VERSION ""

NS_ :

BS_:

BU_: AAF AAF_Tester ABS ACU ADRV AEMC AFLS AHLS APRK AVM BCM CAMERA CGW CLU CUBIS DATC DI_BOX Dummy ECS EMS EPB ESC EVP FATC FPCM FRONT_RADAR HUD IAP IBOX LCA LDWS_LKAS LPI LVR MDPS MTS ODS OPI PGS PSB REA SAS SCC SMK SNV SPAS TCU TMU TPMS _4WD

BS_:

BU_: XXX CAMERA FRONT_RADAR ADRV APRK

BO_ 353 MSG_161: 32 CCNC
 SG_ CHECKSUM : 0|16@1+ (1,0) [0|65535] "" XXX
 SG_ COUNTER : 16|8@1+ (1,0) [0|255] "" XXX
 SG_ FCA_ICON : 24|3@1+ (1,0) [0|7] "" XXX
 SG_ FCA_ALT_ICON : 27|3@1+ (1,0) [0|7] "" XXX
 SG_ LKA_ICON : 30|3@1+ (1,0) [0|3] "" XXX
 SG_ HBA_ICON : 33|3@1+ (1,0) [0|7] "" XXX
 SG_ ZEROS_1 : 36|4@1+ (1,0) [0|15] "" XXX
 SG_ ZEROS_2 : 40|2@1+ (1,0) [0|3] "" XXX
 SG_ FCA_IMAGE : 42|3@1+ (1,0) [0|7] "" XXX
 SG_ ZEROS_3 : 45|3@1+ (1,0) [0|7] "" XXX
 SG_ ZEROS_4 : 48|3@1+ (1,0) [0|7] "" XXX
 SG_ BCA_LEFT : 51|3@1+ (1,0) [0|7] "" XXX
 SG_ BCA_RIGHT : 54|3@1+ (1,0) [0|7] "" XXX
 SG_ LCA_LEFT_ARROW : 57|3@1+ (1,0) [0|7] "" XXX
 SG_ LCA_RIGHT_ARROW : 60|3@1+ (1,0) [0|7] "" XXX
 SG_ ZEROS_5 : 63|1@0+ (1,0) [0|1] "" XXX
 SG_ CENTERLINE : 64|2@1+ (1,0) [0|3] "" XXX
 SG_ TARGET : 66|3@1+ (1,0) [0|7] "" XXX
 SG_ TARGET_POSITION : 69|11@1+ (1,0) [0|7] "" XXX
 SG_ LANELINE_LEFT : 80|4@1+ (1,0) [0|15] "" XXX
 SG_ LANELINE_LEFT_POSITION : 84|6@1+ (1,0) [0|15] "" XXX
 SG_ LANELINE_RIGHT : 90|4@1+ (1,0) [0|15] "" XXX
 SG_ LANELINE_RIGHT_POSITION : 94|6@1+ (1,0) [0|3] "" XXX
 SG_ LANELINE_CURVATURE : 100|5@1- (1,15) [0|31] "" XXX
 SG_ LANE_HIGHLIGHT : 105|4@1+ (1,0) [0|15] "" XXX
 SG_ LANE_HIGHLIGHT_DISTANCE : 109|11@1+ (1,0) [0|7] "" XXX
 SG_ LANE_LEFT : 120|3@1+ (1,0) [0|7] "" XXX
 SG_ LANE_RIGHT : 123|3@1+ (1,0) [0|7] "" XXX
 SG_ LANE_ZOOM : 126|2@1+ (1,0) [0|3] "" XXX
 SG_ ALERTS_1 : 128|6@1+ (1,0) [0|63] "" XXX
 SG_ ALERTS_2 : 134|5@1+ (1,0) [0|3] "" XXX
 SG_ ALERTS_3 : 139|4@1+ (1,0) [0|15] "" XXX
 SG_ ALERTS_4 : 143|9@1+ (1,0) [0|511] "" XXX
 SG_ ALERTS_5 : 152|5@1+ (1,0) [0|7] "" XXX
 SG_ MUTE : 157|3@1+ (1,0) [0|7] "" XXX
 SG_ SOUNDS_1 : 160|4@1+ (1,0) [0|3] "" XXX
 SG_ SOUNDS_2 : 164|4@1+ (1,0) [0|3] "" XXX
 SG_ SOUNDS_3 : 168|4@1+ (1,0) [0|15] "" XXX
 SG_ SOUNDS_4 : 172|3@1+ (1,0) [0|7] "" XXX
 SG_ ZEROS_6 : 175|1@0+ (1,0) [0|1] "" XXX
 SG_ ZEROS_7 : 176|5@1+ (1,0) [0|31] "" XXX
 SG_ SETSPEED_HUD : 181|3@1+ (1,0) [0|3] "" XXX
 SG_ DISTANCE_LEAD : 184|5@1+ (1,0) [0|31] "" XXX
 SG_ DISTANCE_CAR : 189|3@1+ (1,0) [0|7] "" XXX
 SG_ DISTANCE_SPACING : 192|4@1+ (1,0) [0|15] "" XXX
 SG_ DISTANCE : 196|4@1+ (1,0) [0|7] "" XXX
 SG_ SETSPEED_SPEED : 200|8@1+ (1,0) [0|255] "" XXX
 SG_ SETSPEED : 208|4@1+ (1,0) [0|3] "" XXX
 SG_ HDA_ICON : 212|4@1+ (1,0) [0|3] "" XXX
 SG_ SLA_ICON : 216|4@1+ (1,0) [0|15] "" XXX
 SG_ NAV_ICON : 220|4@1+ (1,0) [0|3] "" XXX
 SG_ LFA_ICON : 224|4@1+ (1,0) [0|3] "" XXX
 SG_ LCA_LEFT_ICON : 228|4@1+ (1,0) [0|15] "" XXX
 SG_ LCA_RIGHT_ICON : 232|4@1+ (1,0) [0|15] "" XXX
 SG_ BACKGROUND : 236|4@1+ (1,0) [0|15] "" XXX
 SG_ DAW_ICON : 240|3@1+ (1,0) [0|7] "" XXX
 SG_ CAR_CIRCLE : 243|3@1+ (1,0) [0|7] "" XXX
 SG_ ZEROS_8 : 246|2@1+ (1,0) [0|3] "" XXX
 SG_ ZEROS_9 : 248|8@1+ (1,0) [0|255] "" XXX

BO_ 354 MSG_162: 32 CCNC
 SG_ CHECKSUM : 0|16@1+ (1,0) [0|65535] "" XXX
 SG_ COUNTER : 16|8@1+ (1,0) [0|255] "" XXX
 SG_ SPEEDLIMIT_STYLE : 24|4@1+ (1,0) [0|7] "" XXX
 SG_ SPEEDLIMIT_FLASH : 28|4@1+ (1,0) [0|15] "" XXX
 SG_ SPEEDLIMIT : 32|8@1+ (1,0) [0|255] "" XXX
 SG_ SIGNS : 40|8@1+ (1,0) [0|15] "" XXX
 SG_ SPEEDLIMIT_WEATHER : 48|4@1+ (1,0) [0|15] "" XXX
 SG_ VIBRATE : 52|3@1+ (1,0) [0|7] "" XXX
 SG_ ZEROS_1 : 55|1@0+ (1,0) [0|1] "" XXX
 SG_ ZEROS_2 : 56|8@1+ (1,0) [0|255] "" XXX
 SG_ LEAD : 64|5@1+ (1,0) [0|31] "" XXX
 SG_ LEAD_DISTANCE : 69|11@1+ (1,0) [0|2047] "" XXX
 SG_ LEAD_LATERAL : 80|7@1+ (1,0) [0|127] "" XXX
 SG_ ZEROS_3 : 87|1@0+ (1,0) [0|1] "" XXX
 SG_ LEAD_ALT : 88|5@1+ (1,0) [0|31] "" XXX
 SG_ LEAD_ALT_DISTANCE : 93|11@1+ (1,0) [0|2047] "" XXX
 SG_ LEAD_ALT_LATERAL : 104|7@1+ (1,0) [0|127] "" XXX
 SG_ ZEROS_4 : 111|1@0+ (1,0) [0|1] "" XXX
 SG_ LEAD_LEFT : 112|5@1+ (1,0) [0|31] "" XXX
 SG_ LEAD_LEFT_DISTANCE : 117|11@1+ (1,0) [0|2047] "" XXX
 SG_ LEAD_LEFT_LATERAL : 128|7@1+ (1,0) [0|127] "" XXX
 SG_ ZEROS_5 : 135|1@0+ (1,0) [0|1] "" XXX
 SG_ LEAD_RIGHT : 136|5@1+ (1,0) [0|31] "" XXX
 SG_ LEAD_RIGHT_DISTANCE : 141|11@1+ (1,0) [0|2047] "" XXX
 SG_ LEAD_RIGHT_LATERAL : 152|7@1+ (1,0) [0|127] "" XXX
 SG_ ZEROS_6 : 159|1@0+ (1,0) [0|1] "" XXX
 SG_ ZEROS_7 : 160|8@1+ (1,0) [0|255] "" XXX
 SG_ ZEROS_8 : 168|8@1+ (1,0) [0|255] "" XXX
 SG_ ZEROS_9 : 176|8@1+ (1,0) [0|255] "" XXX
 SG_ ZEROS_10 : 184|8@1+ (1,0) [0|255] "" XXX
 SG_ ZEROS_11 : 192|8@1+ (1,0) [0|255] "" XXX
 SG_ ZEROS_12 : 200|8@1+ (1,0) [0|255] "" XXX
 SG_ ZEROS_13 : 208|5@1+ (1,0) [0|31] "" XXX
 SG_ FAULT_FSS : 213|3@1+ (1,0) [0|7] "" XXX
 SG_ FAULT_FCA : 216|3@1+ (1,0) [0|7] "" XXX
 SG_ FAULT_LSS : 219|3@1+ (1,0) [0|7] "" XXX
 SG_ FAULT_SLA : 222|3@1+ (1,0) [0|7] "" XXX
 SG_ FAULT_DAW : 225|3@1+ (1,0) [0|7] "" XXX
 SG_ FAULT_HBA : 228|3@1+ (1,0) [0|7] "" XXX
 SG_ FAULT_SCC : 231|3@1+ (1,0) [0|7] "" XXX
 SG_ FAULT_LFA : 234|3@1+ (1,0) [0|7] "" XXX
 SG_ FAULT_HDA : 237|3@1+ (1,0) [0|7] "" XXX
 SG_ FAULT_LCA : 240|3@1+ (1,0) [0|7] "" XXX
 SG_ FAULT_HDP : 243|3@1+ (1,0) [0|7] "" XXX
 SG_ FAULT_DAS : 246|3@1+ (1,0) [0|7] "" XXX
 SG_ FAULT_ESS : 249|3@1+ (1,0) [0|7] "" XXX
 SG_ ZEROS_14 : 252|4@1+ (1,0) [0|15] "" XXX

BS_:

BU_: IAP ODS _4WD BCM HUD DATC MDPS AAF_Tester AEMC SMK _4WD EPB CUBIS MTS TMU EVP CGW TPMS LPI DI_BOX SPAS EMS LCA TCU IBOX FATC AFLS FPCM SCC AHLS AVM ABS SNV OPI PGS SAS AAF Dummy LDWS_LKAS LVR ESC PSB CLU ECS ACU REA

BO_ 1532 ODS13: 5 ODS
 SG_ CR_Ods_ID : 0|8@1+ (1.0,0.0) [0.0|255.0] ""  ACU
 SG_ CR_Ods_Chksum_H : 8|8@1+ (1.0,0.0) [0.0|255.0] ""  Dummy
 SG_ CR_Ods_Chksum_L : 16|8@1+ (1.0,0.0) [0.0|255.0] ""  Dummy
 SG_ CR_Ods_RomID_H : 24|8@1+ (1.0,0.0) [0.0|255.0] ""  Dummy
 SG_ CR_Ods_RomID_L : 32|8@1+ (1.0,0.0) [0.0|255.0] ""  Dummy

BO_ 1531 ODS12: 8 ODS
 SG_ CR_Ods_SerNum0 : 0|8@1+ (1.0,0.0) [0.0|255.0] ""  ACU
 SG_ CR_Ods_SerNum1 : 8|8@1+ (1.0,0.0) [0.0|255.0] ""  ACU
 SG_ CR_Ods_SerNum2 : 16|8@1+ (1.0,0.0) [0.0|255.0] ""  ACU
 SG_ CR_Ods_SerNum3 : 24|8@1+ (1.0,0.0) [0.0|255.0] ""  ACU
 SG_ CR_Ods_SerNum4 : 32|8@1+ (1.0,0.0) [0.0|255.0] ""  ACU
 SG_ CR_Ods_SerNum5 : 40|8@1+ (1.0,0.0) [0.0|255.0] ""  ACU
 SG_ CR_Ods_SerNum6 : 48|8@1+ (1.0,0.0) [0.0|255.0] ""  ACU
 SG_ CR_Ods_SerNum7 : 56|8@1+ (1.0,0.0) [0.0|255.0] ""  ACU

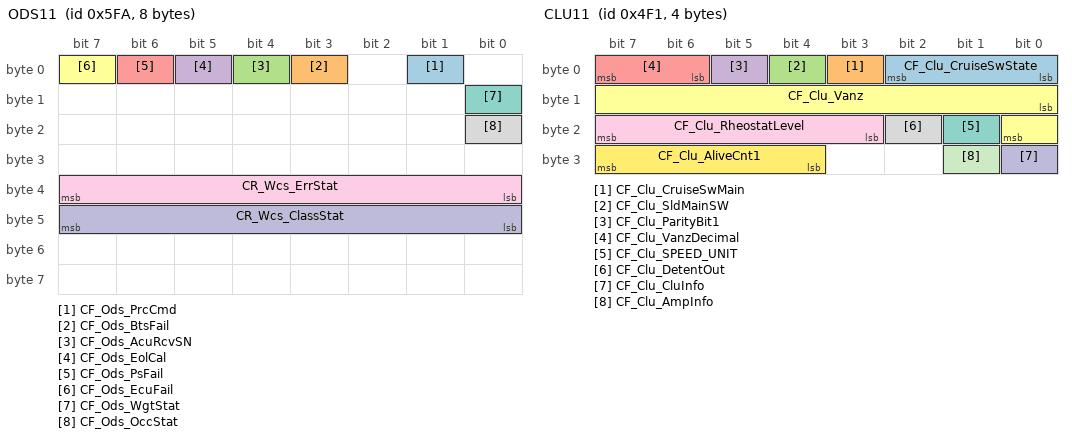
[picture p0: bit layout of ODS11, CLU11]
BO_ 1530 ODS11: 8 ODS
 SG_ CF_Ods_PrcCmd : 1|1@1+ (1.0,0.0) [0.0|1.0] ""  Dummy
 SG_ CF_Ods_BtsFail : 3|1@1+ (1.0,0.0) [0.0|1.0] ""  Dummy
 SG_ CF_Ods_AcuRcvSN : 4|1@1+ (1.0,0.0) [0.0|1.0] ""  ACU
 SG_ CF_Ods_EolCal : 5|1@1+ (1.0,0.0) [0.0|1.0] ""  ACU
 SG_ CF_Ods_PsFail : 6|1@1+ (1.0,0.0) [0.0|1.0] ""  ACU
 SG_ CF_Ods_EcuFail : 7|1@1+ (1.0,0.0) [0.0|1.0] ""  ACU
 SG_ CF_Ods_WgtStat : 8|1@1+ (1.0,0.0) [0.0|1.0] ""  ACU
 SG_ CF_Ods_OccStat : 16|1@1+ (1.0,0.0) [0.0|1.0] ""  ACU
 SG_ CR_Wcs_ErrStat : 32|8@1+ (1.0,0.0) [0.0|63.0] ""  ACU
 SG_ CR_Wcs_ClassStat : 40|8@1+ (1.0,0.0) [0.0|4.0] ""  ACU,BCM

BO_ 1017 ECS12: 4 ECS
 SG_ Height_FL : 0|8@1+ (1.0,-128.0) [-128.0|127.0] "mm"  AFLS
 SG_ Height_FR : 8|8@1+ (1.0,-128.0) [-128.0|127.0] "mm"  AFLS
 SG_ Height_RL : 16|8@1+ (1.0,-128.0) [-128.0|127.0] "mm"  AFLS
 SG_ Height_RR : 24|8@1+ (1.0,-128.0) [-128.0|127.0] "mm"  AFLS

BO_ 1268 SPAS12: 8 SPAS
 SG_ CF_Spas_HMI_Stat : 0|8@1+ (1.0,0.0) [0.0|255.0] ""  CLU
 SG_ CF_Spas_Disp : 8|2@1+ (1.0,0.0) [0.0|3.0] ""  CLU,EMS
 SG_ CF_Spas_FIL_Ind : 10|3@1+ (1.0,0.0) [0.0|7.0] ""  AVM,CLU
 SG_ CF_Spas_FIR_Ind : 13|3@1+ (1.0,0.0) [0.0|7.0] ""  AVM,CLU
 SG_ CF_Spas_FOL_Ind : 16|3@1+ (1.0,0.0) [0.0|7.0] ""  AVM,CLU
 SG_ CF_Spas_FOR_Ind : 19|3@1+ (1.0,0.0) [0.0|7.0] ""  AVM,CLU
 SG_ CF_Spas_VolDown : 22|2@1+ (1.0,0.0) [0.0|3.0] ""  CLU
 SG_ CF_Spas_RIL_Ind : 24|3@1+ (1.0,0.0) [0.0|7.0] ""  AVM,CLU
 SG_ CF_Spas_RIR_Ind : 27|3@1+ (1.0,0.0) [0.0|7.0] ""  AVM,CLU
 SG_ CF_Spas_FLS_Alarm : 30|2@1+ (1.0,0.0) [0.0|3.0] ""  CLU
 SG_ CF_Spas_ROL_Ind : 32|3@1+ (1.0,0.0) [0.0|7.0] ""  AVM,CLU
 SG_ CF_Spas_ROR_Ind : 35|3@1+ (1.0,0.0) [0.0|7.0] ""  AVM,CLU
 SG_ CF_Spas_FCS_Alarm : 38|2@1+ (1.0,0.0) [0.0|3.0] ""  CLU
 SG_ CF_Spas_FI_Ind : 40|3@1+ (1.0,0.0) [0.0|7.0] ""  AVM,CLU
 SG_ CF_Spas_RI_Ind : 43|3@1+ (1.0,0.0) [0.0|7.0] ""  AVM,CLU
 SG_ CF_Spas_FRS_Alarm : 46|2@1+ (1.0,0.0) [0.0|3.0] ""  CLU
 SG_ CF_Spas_FR_Alarm : 48|2@1+ (1.0,0.0) [0.0|3.0] ""  BCM,CLU
 SG_ CF_Spas_RR_Alarm : 50|2@1+ (1.0,0.0) [0.0|3.0] ""  BCM,CLU
 SG_ CF_Spas_BEEP_Alarm : 52|4@1+ (1.0,0.0) [0.0|15.0] ""  BCM,CLU
 SG_ CF_Spas_StatAlarm : 56|1@1+ (1.0,0.0) [0.0|1.0] ""  CLU
 SG_ CF_Spas_RLS_Alarm : 57|2@1+ (1.0,0.0) [0.0|3.0] ""  CLU
 SG_ CF_Spas_RCS_Alarm : 59|2@1+ (1.0,0.0) [0.0|3.0] ""  CLU
 SG_ CF_Spas_RRS_Alarm : 61|2@1+ (1.0,0.0) [0.0|3.0] ""  CLU

BO_ 1265 CLU11: 4 CLU
 SG_ CF_Clu_CruiseSwState : 0|3@1+ (1.0,0.0) [0.0|7.0] ""  EMS,LDWS_LKAS,SCC
 SG_ CF_Clu_CruiseSwMain : 3|1@1+ (1.0,0.0) [0.0|1.0] ""  EMS,LDWS_LKAS,SCC
 SG_ CF_Clu_SldMainSW : 4|1@1+ (1.0,0.0) [0.0|1.0] ""  EMS
 SG_ CF_Clu_ParityBit1 : 5|1@1+ (1.0,0.0) [0.0|1.0] "pulse count"  EMS
 SG_ CF_Clu_VanzDecimal : 6|2@1+ (0.125,0.0) [0.0|0.375] ""  EMS
 SG_ CF_Clu_Vanz : 8|9@1+ (0.5,0.0) [0.0|255.5] "km/h or MPH"  BCM,CUBIS,EMS,IBOX,LDWS_LKAS,MDPS,SCC
 SG_ CF_Clu_SPEED_UNIT : 17|1@1+ (1.0,0.0) [0.0|1.0] ""  BCM,CUBIS,EMS,IBOX,LDWS_LKAS,MDPS,SCC
 SG_ CF_Clu_DetentOut : 18|1@1+ (1.0,0.0) [0.0|1.0] ""  AVM,BCM,LCA,PGS,SPAS
 SG_ CF_Clu_RheostatLevel : 19|5@1+ (1.0,0.0) [0.0|31.0] ""  AVM,BCM,LCA,PGS,SPAS
 SG_ CF_Clu_CluInfo : 24|1@1+ (1.0,0.0) [0.0|1.0] ""  BCM
 SG_ CF_Clu_AmpInfo : 25|1@1+ (1.0,0.0) [0.0|1.0] ""  BCM
 SG_ CF_Clu_AliveCnt1 : 28|4@1+ (1.0,0.0) [0.0|15.0] ""  AHLS,EMS,EPB,LDWS_LKAS,MDPS,SCC

BO_ 1260 Sign_Detection: 8 XXX
 SG_ SpeedLim_Nav_Cam : 40|8@1+ (1,0) [0|255] "km/h / mph" XXX
 SG_ SpeedLim_Nav_Cam2 : 48|8@1+ (1,0) [0|255] "km/h / mph" XXX

BO_ 1492 TMU_GW_PE_01: 8 CLU
 SG_ TMU_IVRActivity : 0|2@1+ (1.0,0.0) [0.0|3.0] ""  DATC
 SG_ TMU_PhoneActivity : 2|2@1+ (1.0,0.0) [0.0|3.0] ""  DATC

BO_ 1491 HU_DATC_PE_00: 8 CLU
 SG_ HU_VRActivity : 0|2@1+ (1.0,0.0) [0.0|3.0] ""  DATC
 SG_ HU_PhoneActivity : 2|2@1+ (1.0,0.0) [0.0|3.0] ""  DATC
 SG_ BlowerNoiseControl : 4|2@1+ (1.0,0.0) [0.0|3.0] ""  DATC

BO_ 1490 HU_DATC_E_02: 8 CLU
 SG_ HU_DATC_RearOnOffSet : 6|2@1+ (1.0,0.0) [0.0|3.0] ""  DATC
 SG_ HU_DATC_ADSOnOffSet : 8|2@1+ (1.0,0.0) [0.0|3.0] ""  DATC

BO_ 1479 EMS21: 8 EMS
 SG_ SCR_LEVEL_WARN_LAMP : 0|1@1+ (1.0,0.0) [0.0|1.0] ""  CLU
 SG_ SCR_LEVEL_WARN : 1|3@1+ (1.0,0.0) [0.0|4.0] ""  CLU
 SG_ SCR_SYS_ERROR_WARN : 4|3@1+ (1.0,0.0) [0.0|7.0] ""  CLU
 SG_ SCR_SYSTEM_WARN_LAMP : 7|1@1+ (1.0,0.0) [0.0|1.0] ""  CLU
 SG_ SCR_INDUCEMENT_EXIT_COND : 8|2@1+ (1.0,0.0) [0.0|3.0] ""  CLU
 SG_ SCR_UREA_LEVEL : 16|8@1+ (0.5,0.0) [0.0|100.0] "%"  CLU
 SG_ SCR_NO_REMAINING_RESTARTS : 24|8@1+ (1.0,0.0) [0.0|255.0] ""  CLU
 SG_ SCR_REMAINING_DISTANCE : 32|16@1+ (1.0,0.0) [0.0|25000.0] "km"  CLU

BO_ 1472 GW_Warning_PE: 8 BCM
 SG_ Audio_VolumeDown : 38|2@1+ (1.0,0.0) [0.0|3.0] ""  CLU
 SG_ Pas_Spkr_Flh_Alarm : 48|2@1+ (1.0,0.0) [0.0|3.0] ""  CLU
 SG_ Pas_Spkr_Fcnt_Alarm : 50|2@1+ (1.0,0.0) [0.0|3.0] ""  CLU
 SG_ Pas_Spkr_Frh_Alarm : 52|2@1+ (1.0,0.0) [0.0|3.0] ""  CLU
 SG_ Pas_Spkr_Rlh_Alarm : 56|2@1+ (1.0,0.0) [0.0|3.0] ""  CLU,PGS
 SG_ Pas_Spkr_Rcnt_Alarm : 58|2@1+ (1.0,0.0) [0.0|3.0] ""  CLU
 SG_ Pas_Spkr_Rrh_Alarm : 60|2@1+ (1.0,0.0) [0.0|3.0] ""  CLU,PGS

BO_ 1984 CAL_SAS11: 2 ESC
 SG_ CCW : 0|4@1+ (1.0,0.0) [0.0|15.0] ""  SAS
 SG_ SAS_CID : 4|11@1+ (1.0,0.0) [0.0|2047.0] ""  SAS

BO_ 1456 CLU12: 4 CLU
 SG_ CF_Clu_Odometer : 0|24@1+ (0.1,0.0) [0.0|1677721.4] "km"  _4WD,AAF,BCM,CUBIS,EMS,EPB,IBOX,LDWS_LKAS,SCC,TPMS

BO_ 688 SAS11: 5 MDPS
 SG_ SAS_Angle : 0|16@1- (0.1,0.0) [-3276.8|3276.7] "Deg"  _4WD,ACU,AFLS,AVM,CLU,ECS,EMS,ESC,IBOX,LCA,LDWS_LKAS,PGS,PSB,SCC,SPAS,TCU,_4WD,ACU,AFLS,AVM,BCM,CLU,ECS,EMS,ESC,IBOX,LCA,LDWS_LKAS,PGS,PSB,SCC,SPAS,TCU
 SG_ SAS_Speed : 16|8@1+ (4.0,0.0) [0.0|1016.0] ""  AFLS,ECS,ESC,IBOX,LDWS_LKAS,SCC,SPAS,TCU,AFLS,ECS,ESC,IBOX,LDWS_LKAS,SCC,SPAS,TCU
 SG_ SAS_Stat : 24|8@1+ (1.0,0.0) [0.0|255.0] ""  ECS,ESC,IBOX,LDWS_LKAS,PSB,SCC,SPAS,TCU,ECS,ESC,IBOX,LDWS_LKAS,PSB,SCC,SPAS,TCU
 SG_ MsgCount : 32|4@1+ (1.0,0.0) [0.0|15.0] ""  ECS,ESC,IBOX,LDWS_LKAS,PSB,SCC,SPAS,ECS,ESC,IBOX,LDWS_LKAS,PSB,SCC,SPAS
 SG_ CheckSum : 36|4@1+ (1.0,0.0) [0.0|15.0] ""  ECS,EMS,ESC,IBOX,LDWS_LKAS,PSB,SCC,SPAS,ECS,EMS,ESC,IBOX,LDWS_LKAS,PSB,SCC,SPAS

BO_ 1441 ACU12: 8 ACU
 SG_ CR_Acu_SN : 0|64@1+ (1.0,0.0) [0.0|0.0] ""  ODS

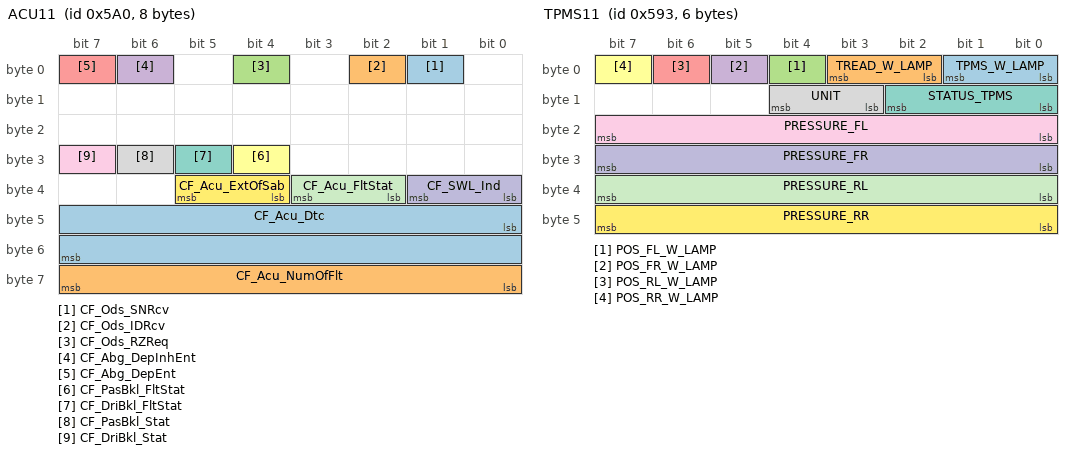
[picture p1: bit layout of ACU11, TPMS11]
BO_ 1440 ACU11: 8 ACU
 SG_ CF_Ods_SNRcv : 1|1@1+ (1.0,0.0) [0.0|1.0] ""  ODS
 SG_ CF_Ods_IDRcv : 2|1@1+ (1.0,0.0) [0.0|1.0] ""  ODS
 SG_ CF_Ods_RZReq : 4|1@1+ (1.0,0.0) [0.0|1.0] ""  ODS
 SG_ CF_Abg_DepInhEnt : 6|1@1+ (1.0,0.0) [0.0|1.0] ""  ODS
 SG_ CF_Abg_DepEnt : 7|1@1+ (1.0,0.0) [0.0|1.0] ""  ODS
 SG_ CF_PasBkl_FltStat : 28|1@1+ (1.0,0.0) [0.0|1.0] ""  ODS,PSB
 SG_ CF_DriBkl_FltStat : 29|1@1+ (1.0,0.0) [0.0|1.0] ""  ODS,PSB
 SG_ CF_PasBkl_Stat : 30|1@1+ (1.0,0.0) [0.0|1.0] ""  IBOX,ODS,PSB,TMU
 SG_ CF_DriBkl_Stat : 31|1@1+ (1.0,0.0) [0.0|1.0] ""  ODS,PSB
 SG_ CF_SWL_Ind : 32|2@1+ (1.0,0.0) [0.0|3.0] ""  CUBIS,IBOX
 SG_ CF_Acu_FltStat : 34|2@1+ (1.0,0.0) [0.0|3.0] ""  CUBIS,IBOX
 SG_ CF_Acu_ExtOfSab : 36|2@1+ (1.0,0.0) [0.0|3.0] ""  BCM,CLU,CUBIS,IBOX
 SG_ CF_Acu_Dtc : 40|16@1+ (1.0,0.0) [0.0|65535.0] ""  CUBIS,IBOX
 SG_ CF_Acu_NumOfFlt : 56|8@1+ (1.0,0.0) [0.0|255.0] ""  CUBIS,IBOX

BO_ 1437 AHLS11: 8 AHLS
 SG_ CF_Ahls_WarnLamp : 0|2@1+ (1.0,0.0) [0.0|3.0] ""  CLU
 SG_ CF_Ahls_WarnMsg : 2|2@1+ (1.0,0.0) [0.0|3.0] ""  CLU

BO_ 1434 PSB11: 2 PSB
 SG_ PSB_LH_FAIL : 0|2@1+ (1.0,0.0) [0.0|3.0] ""  CLU
 SG_ PSB_LH_TGL : 2|1@1+ (1.0,0.0) [0.0|1.0] ""  CLU
 SG_ PSB_LH_ACT : 3|4@1+ (1.0,0.0) [0.0|4.0] ""  Dummy
 SG_ PSB_RH_FAIL : 8|2@1+ (1.0,0.0) [0.0|3.0] ""  CLU
 SG_ PSB_RH_TGL : 10|1@1+ (1.0,0.0) [0.0|1.0] ""  CLU
 SG_ PSB_RH_ACT : 11|4@1+ (1.0,0.0) [0.0|4.0] ""  Dummy

BO_ 916 TCS13: 8 ESC
 SG_ aBasis : 0|11@1+ (0.01,-10.23) [-10.23|10.24] "m/s^2"  EMS,SCC
 SG_ BrakeLight : 11|1@1+ (1.0,0.0) [0.0|1.0] ""  CLU,EMS,SCC
 SG_ DCEnable : 12|1@1+ (1.0,0.0) [0.0|1.0] ""  EMS,SCC
 SG_ AliveCounterTCS : 13|3@1+ (1.0,0.0) [0.0|7.0] ""  EMS,SCC
 SG_ Pre_TCS_CTL : 16|1@1+ (1.0,0.0) [0.0|1.0] ""  Vector__XXX
 SG_ EBA_ACK : 17|1@1+ (1.0,0.0) [0.0|1.0] ""  Vector__XXX
 SG_ FCA_ACK : 18|1@1+ (1.0,0.0) [0.0|1.0] ""  Vector__XXX
 SG_ DF_BF_STAT : 19|2@1+ (1.0,0.0) [0.0|3.0] ""  BCW
 SG_ SCCReqLim : 22|2@1+ (1.0,0.0) [0.0|3.0] ""  SCC
 SG_ TQI_SCC : 24|8@1+ (0.390625,0.0) [0.0|199.609375] "%"  Vector__XXX
 SG_ ACCEL_REF_ACC : 32|11@1+ (0.01,-10.23) [-10.23|10.24] "m/s^2"  EMS,SCC
 SG_ ACCEnable : 43|2@1+ (1.0,0.0) [0.0|3.0] ""  EMS,SCC
 SG_ DriverOverride : 45|2@1+ (1.0,0.0) [0.0|3.0] ""  EMS,SCC
 SG_ StandStill : 47|1@1+ (1.0,0.0) [0.0|1.0] ""  EMS,SCC
 SG_ CheckSum_TCS3 : 48|4@1+ (1.0,0.0) [0.0|15.0] ""  EMS,SCC
 SG_ ACC_EQUIP : 52|1@1+ (1.0,0.0) [0.0|1.0] ""  EMS,SCC
 SG_ PBRAKE_ACT : 53|1@1+ (1.0,0.0) [0.0|1.0] ""  EMS,SCC
 SG_ ACC_REQ : 54|1@1+ (1.0,0.0) [0.0|1.0] ""  EMS
 SG_ DriverBraking : 55|1@1+ (1.0,0.0) [0.0|1.0] ""  EMS,SCC
 SG_ CF_VSM_Coded : 56|1@1+ (1.0,0.0) [0.0|1.0] ""  SCC
 SG_ CF_VSM_Avail : 57|2@1+ (1.0,0.0) [0.0|3.0] ""  CLU,SCC
 SG_ CF_VSM_Handshake : 59|1@1+ (1.0,0.0) [0.0|1.0] ""  SCC
 SG_ CF_DriBkeStat : 60|1@1+ (1.0,0.0) [0.0|1.0] ""  SCC
 SG_ CF_VSM_ConfSwi : 61|2@1+ (1.0,0.0) [0.0|3.0] ""  SCC
 SG_ AEB_EQUIP : 63|1@1+ (1.0,0.0) [0.0|1.0] ""  SCC

BO_ 1427 TPMS11: 6 BCM
 SG_ TPMS_W_LAMP : 0|2@1+ (1.0,0.0) [0.0|3.0] ""  CLU,CUBIS,HUD,IBOX,CLU,CUBIS,HUD,IBOX
 SG_ TREAD_W_LAMP : 2|2@1+ (1.0,0.0) [0.0|3.0] ""  CLU,CUBIS,HUD,IBOX,CLU,CUBIS,HUD,IBOX
 SG_ POS_FL_W_LAMP : 4|1@1+ (1.0,0.0) [0.0|1.0] ""  CLU,CUBIS,HUD,IBOX
 SG_ POS_FR_W_LAMP : 5|1@1+ (1.0,0.0) [0.0|1.0] ""  CLU,CUBIS,HUD,IBOX
 SG_ POS_RL_W_LAMP : 6|1@1+ (1.0,0.0) [0.0|1.0] ""  CLU,CUBIS,HUD,IBOX
 SG_ POS_RR_W_LAMP : 7|1@1+ (1.0,0.0) [0.0|1.0] ""  CLU,CUBIS,HUD,IBOX
 SG_ STATUS_TPMS : 8|3@1+ (1.0,0.0) [0.0|0.0] ""  CLU
 SG_ UNIT : 11|2@1+ (1.0,0.0) [0.0|3.0] ""  CLU
 SG_ PRESSURE_FL : 16|8@1+ (1.0,0.0) [0.0|255.0] ""  CLU
 SG_ PRESSURE_FR : 24|8@1+ (1.0,0.0) [0.0|255.0] ""  CLU
 SG_ PRESSURE_RL : 32|8@1+ (1.0,0.0) [0.0|255.0] ""  CLU
 SG_ PRESSURE_RR : 40|8@1+ (1.0,0.0) [0.0|255.0] ""  CLU

BO_ 915 TCS12: 4 ESC
 SG_ SA_COUNT : 0|16@1+ (2.0,-32768.0) [-32768.0|98302.0] ""  _4WD,ACU,MDPS
 SG_ SA_Z_COUNT : 16|15@1+ (2.0,-32768.0) [-32768.0|32766.0] ""  _4WD,ACU,MDPS
 SG_ SA_Z_FLAG : 31|1@1+ (1.0,0.0) [0.0|1.0] ""  _4WD,ACU,MDPS

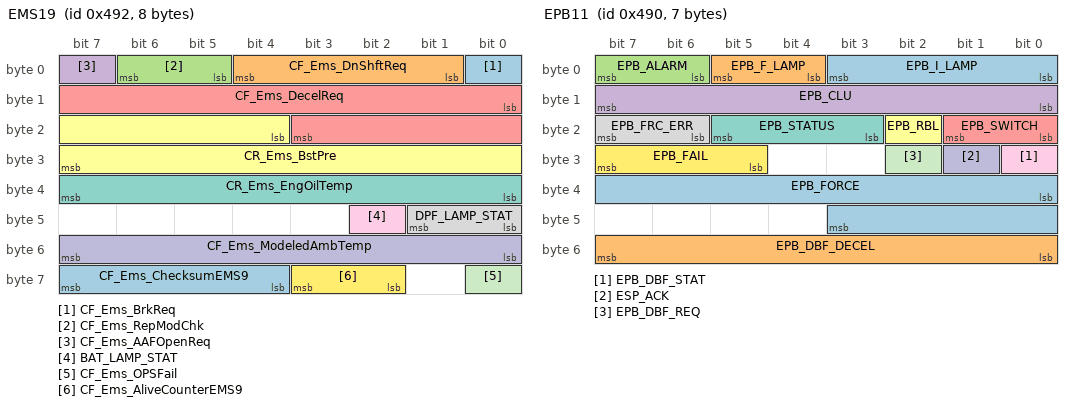
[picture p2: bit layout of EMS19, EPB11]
BO_ 1170 EMS19: 8 EMS
 SG_ CF_Ems_BrkReq : 0|1@1+ (1.0,0.0) [0.0|1.0] ""  ESC,IBOX,TCU
 SG_ CF_Ems_DnShftReq : 1|4@1+ (1.0,0.0) [0.0|14.0] ""  IBOX,TCU
 SG_ CF_Ems_RepModChk : 5|2@1+ (1.0,0.0) [0.0|3.0] ""  IBOX
 SG_ CF_Ems_AAFOpenReq : 7|1@1+ (1.0,0.0) [0.0|1.0] ""  AAF,IBOX
 SG_ CF_Ems_DecelReq : 8|12@1+ (0.0010,-4.094) [-4.094|0.0] "m/s^2"  ESC,IBOX,TCU
 SG_ CR_Ems_BstPre : 20|12@1+ (1.322,0.0) [0.0|4094.0] "hPa"  CLU,IBOX
 SG_ CR_Ems_EngOilTemp : 32|8@1+ (0.75,-40.0) [0.0|254.0] "deg"  CLU,IBOX
 SG_ DPF_LAMP_STAT : 40|2@1+ (1.0,0.0) [0.0|3.0] ""  CLU,IBOX
 SG_ BAT_LAMP_STAT : 42|1@1+ (1.0,0.0) [0.0|1.0] ""  CLU,IBOX
 SG_ CF_Ems_ModeledAmbTemp : 48|8@1+ (0.5,-41.0) [-41.0|85.5] "deg"  AAF,IBOX
 SG_ CF_Ems_OPSFail : 56|1@1+ (1.0,0.0) [0.0|1.0] ""  CLU,IBOX
 SG_ CF_Ems_AliveCounterEMS9 : 58|2@1+ (1.0,0.0) [0.0|3.0] ""  AAF,ABS,CUBIS,ECS,EPB,IBOX,MDPS,REA,SCC,SMK,TCU
 SG_ CF_Ems_ChecksumEMS9 : 60|4@1+ (1.0,0.0) [0.0|15.0] ""  AAF,ABS,CUBIS,ECS,EPB,IBOX,MDPS,REA,SCC,SMK,TCU

BO_ 1425 AFLS11: 2 AFLS
 SG_ AFLS_STAT : 1|2@1+ (1.0,0.0) [0.0|3.0] ""  CLU
 SG_ CF_Afls_TrfChgStat : 3|1@1+ (1.0,0.0) [0.0|1.0] ""  CLU
 SG_ CF_Afls_LedHLStat : 4|2@1+ (1.0,0.0) [0.0|3.0] ""  CLU

BO_ 912 SPAS11: 7 SPAS
 SG_ CF_Spas_Stat : 0|4@1+ (1.0,0.0) [0.0|15.0] ""  ESC,MDPS
 SG_ CF_Spas_TestMode : 4|2@1+ (1.0,0.0) [0.0|3.0] ""  MDPS
 SG_ CR_Spas_StrAngCmd : 8|16@1- (0.1,0.0) [-3276.8|3276.7] ""  MDPS
 SG_ CF_Spas_BeepAlarm : 24|4@1+ (1.0,0.0) [0.0|15.0] ""  CLU
 SG_ CF_Spas_Mode_Seq : 28|2@1+ (1.0,0.0) [0.0|3.0] ""  CLU
 SG_ CF_Spas_AliveCnt : 32|8@1+ (1.0,0.0) [0.0|255.0] ""  MDPS
 SG_ CF_Spas_Chksum : 40|8@1+ (1.0,0.0) [0.0|255.0] ""  MDPS
 SG_ CF_Spas_PasVol : 48|3@1+ (1.0,0.0) [0.0|7.0] ""  CGW,CLU

BO_ 1168 EPB11: 7 EPB
 SG_ EPB_I_LAMP : 0|4@1+ (1.0,0.0) [0.0|15.0] ""  BCM,CLU,CUBIS,ESC,IBOX
 SG_ EPB_F_LAMP : 4|2@1+ (1.0,0.0) [0.0|3.0] ""  CLU,CUBIS,ESC,IBOX
 SG_ EPB_ALARM : 6|2@1+ (1.0,0.0) [0.0|3.0] ""  CLU,ESC
 SG_ EPB_CLU : 8|8@1+ (1.0,0.0) [0.0|255.0] ""  CLU,ESC
 SG_ EPB_SWITCH : 16|2@1+ (1.0,0.0) [0.0|3.0] ""  ESC,SCC
 SG_ EPB_RBL : 18|1@1+ (1.0,0.0) [0.0|1.0] ""  EMS,ESC
 SG_ EPB_STATUS : 19|3@1+ (1.0,0.0) [0.0|7.0] ""  CLU,EMS,ESC,SCC,TCU
 SG_ EPB_FRC_ERR : 22|2@1+ (1.0,0.0) [0.0|3.0] ""  EMS,ESC,SCC,TCU
 SG_ EPB_DBF_STAT : 24|1@1+ (1.0,0.0) [0.0|1.0] ""  ESC
 SG_ ESP_ACK : 25|1@1+ (1.0,0.0) [0.0|1.0] ""  ESC
 SG_ EPB_DBF_REQ : 26|1@1+ (1.0,0.0) [0.0|1.0] ""  ESC
 SG_ EPB_FAIL : 29|3@1+ (1.0,0.0) [0.0|7.0] ""  ESC,SCC
 SG_ EPB_FORCE : 32|12@1+ (1.0,-1000.0) [-1000.0|3000.0] ""  ESC
 SG_ EPB_DBF_DECEL : 48|8@1+ (0.01,0.0) [0.0|2.54] "g"  ESC

BO_ 399 EMS_H12: 8 EMS
 SG_ R_TqAcnApvC : 0|8@1+ (0.2,0.0) [0.0|51.0] "Nm"  DATC,IBOX
 SG_ R_PAcnC : 8|8@1+ (125.0,0.0) [0.0|31875.0] "hPa"  DATC,IBOX
 SG_ TQI_B : 16|8@1+ (0.390625,0.0) [0.0|99.609375] "%"  ABS,ESC,IBOX
 SG_ SLD_VS : 24|8@1+ (1.0,0.0) [0.0|255.0] "km/h"  CLU,IBOX
 SG_ CF_CdaStat : 32|3@1+ (1.0,0.0) [0.0|7.0] ""  AEMC,IBOX,TCU
 SG_ CF_Ems_IsgStat : 35|3@1+ (1.0,0.0) [0.0|7.0] ""  ABS,BCM,CLU,DATC,EPB,ESC,IBOX,LDWS_LKAS,MDPS,SMK,TCU
 SG_ CF_Ems_OilChg : 38|1@1+ (1.0,0.0) [0.0|1.0] ""  CLU,IBOX
 SG_ CF_Ems_EtcLimpMod : 39|1@1+ (1.0,0.0) [0.0|1.0] ""  CLU,IBOX
 SG_ R_NEngIdlTgC : 40|8@1+ (10.0,0.0) [0.0|2550.0] "rpm"  DATC,IBOX,TCU
 SG_ CF_Ems_UpTarGr : 48|1@1+ (1.0,0.0) [0.0|1.0] ""  CLU,IBOX
 SG_ CF_Ems_DownTarGr : 49|1@1+ (1.0,0.0) [0.0|1.0] ""  CLU,IBOX
 SG_ CF_Ems_DesCurGr : 50|4@1+ (1.0,0.0) [0.0|15.0] ""  CLU,IBOX
 SG_ CF_Ems_SldAct : 54|1@1+ (1.0,0.0) [0.0|1.0] ""  CLU,IBOX
 SG_ CF_Ems_SldPosAct : 55|1@1+ (1.0,0.0) [0.0|1.0] ""  CLU,IBOX
 SG_ CF_Ems_HPresStat : 56|1@1+ (1.0,0.0) [0.0|1.0] ""  IBOX,TCU
 SG_ CF_Ems_IsgBuz : 57|1@1+ (1.0,0.0) [0.0|1.0] ""  CLU,IBOX
 SG_ CF_Ems_IdlStpFCO : 58|1@1+ (1.0,0.0) [0.0|1.0] ""  CLU,IBOX
 SG_ CF_Ems_FCopen : 59|1@1+ (1.0,0.0) [0.0|1.0] ""  CLU,IBOX
 SG_ CF_Ems_ActEcoAct : 60|1@1+ (1.0,0.0) [0.0|1.0] ""  CLU,IBOX,TCU
 SG_ CF_Ems_EngRunNorm : 61|1@1+ (1.0,0.0) [0.0|1.0] ""  ABS,ESC,IBOX,TCU
 SG_ CF_Ems_IsgStat2 : 62|2@1+ (2.0,0.0) [0.0|3.0] ""  CLU,IBOX,TCU

BO_ 1419 LCA11: 8 LCA
 SG_ CF_Lca_Stat : 0|4@1+ (1.0,0.0) [0.0|15.0] ""  BCM,CLU
 SG_ CF_Rcta_Stat : 4|4@1+ (1.0,0.0) [0.0|15.0] ""  BCM,CLU
 SG_ CF_Lca_IndLeft : 8|2@1+ (1.0,0.0) [0.0|3.0] ""  BCM,CLU
 SG_ CF_Rcw_Stat : 10|4@1+ (1.0,0.0) [0.0|15.0] ""  BCM,CLU
 SG_ CF_RCW_Warning : 14|2@1+ (1.0,0.0) [0.0|3.0] ""  BCM,CLU
 SG_ CF_Lca_IndRight : 16|2@1+ (1.0,0.0) [0.0|3.0] ""  BCM,CLU
 SG_ CF_Lca_SndWan_Stat : 18|2@1+ (1.0,0.0) [0.0|3.0] ""  BCM,CLU
 SG_ CF_FR_SndWan : 20|1@1+ (1.0,0.0) [0.0|1.0] ""  BCM,CLU
 SG_ CF_FL_SndWan : 21|1@1+ (1.0,0.0) [0.0|1.0] ""  BCM,CLU
 SG_ CF_RR_SndWan : 22|1@1+ (1.0,0.0) [0.0|1.0] ""  BCM,CLU
 SG_ CF_RL_SndWan : 23|1@1+ (1.0,0.0) [0.0|1.0] ""  BCM,CLU
 SG_ CF_Lca_IndBriLeft : 24|8@1+ (1.0,0.0) [0.0|255.0] ""  BCM,CLU
 SG_ CF_Lca_IndBriRight : 32|8@1+ (1.0,0.0) [0.0|255.0] ""  BCM,CLU
 SG_ CF_RCTA_IndBriLeft : 40|8@1+ (1.0,0.0) [0.0|255.0] ""  BCM,CLU
 SG_ CF_RCTA_IndBriRight : 48|8@1+ (1.0,0.0) [0.0|255.0] ""  BCM,CLU
 SG_ CF_RCTA_IndLeft : 56|2@1+ (1.0,0.0) [0.0|3.0] ""  BCM,CLU
 SG_ CF_RCTA_IndRight : 58|2@1+ (1.0,0.0) [0.0|3.0] ""  BCM,CLU
 SG_ CF_SndWarnForClu : 60|1@1+ (1.0,0.0) [0.0|1.0] ""  CLU

BO_ 906 ABS11: 8 ABS
 SG_ ABS_DEF : 0|1@1+ (1.0,0.0) [0.0|1.0] ""  _4WD,ACU,EMS,SPAS,TCU
 SG_ EBD_DEF : 1|1@1+ (1.0,0.0) [0.0|1.0] ""  _4WD,EMS,SPAS,TCU
 SG_ ABS_ACT : 2|1@1+ (1.0,0.0) [0.0|1.0] ""  _4WD,ACU,EPB,SPAS,TCU
 SG_ ABS_W_LAMP : 3|1@1+ (1.0,0.0) [0.0|1.0] ""  _4WD,CLU,CUBIS,MTS,TMU
 SG_ EBD_W_LAMP : 4|1@1+ (1.0,0.0) [0.0|1.0] ""  _4WD,CLU
 SG_ ABS_DIAG : 5|1@1+ (1.0,0.0) [0.0|1.0] ""  _4WD,CLU
 SG_ ESS_STAT : 6|2@1+ (1.0,0.0) [0.0|3.0] ""  _4WD,BCM,CLU,EMS

BO_ 903 WHL_PUL11: 6 ABS
 SG_ WHL_PUL_FL : 0|8@1+ (0.5,0.0) [0.0|127.5] "pulse count"  CUBIS,EPB,IBOX,SPAS,TMU,TPMS,CUBIS,EPB,IBOX,LDWS_LKAS,SPAS,TMU,TPMS
 SG_ WHL_PUL_FR : 8|8@1+ (0.5,0.0) [0.0|127.5] "pulse count"  CUBIS,EPB,IBOX,SPAS,TMU,TPMS,CUBIS,EPB,IBOX,LDWS_LKAS,SPAS,TMU,TPMS
 SG_ WHL_PUL_RL : 16|8@1+ (0.5,0.0) [0.0|127.5] "pulse count"  CUBIS,EPB,IBOX,SPAS,TMU,TPMS,CUBIS,EPB,IBOX,LDWS_LKAS,SPAS,TMU,TPMS
 SG_ WHL_PUL_RR : 24|8@1+ (0.5,0.0) [0.0|127.5] "pulse count"  CUBIS,EPB,IBOX,SPAS,TMU,TPMS,CUBIS,EPB,IBOX,LDWS_LKAS,SPAS,TMU,TPMS
 SG_ WHL_DIR_FL : 32|2@1+ (1.0,0.0) [0.0|3.0] ""  EPB,SPAS,TPMS,EPB,LCA,SPAS,TPMS
 SG_ WHL_DIR_FR : 34|2@1+ (1.0,0.0) [0.0|3.0] ""  EPB,SPAS,TPMS,EPB,LCA,SPAS,TPMS
 SG_ WHL_DIR_RL : 36|2@1+ (1.0,0.0) [0.0|3.0] ""  EPB,SPAS,TPMS,EPB,LCA,SPAS,TPMS
 SG_ WHL_DIR_RR : 38|2@1+ (1.0,0.0) [0.0|3.0] ""  EPB,SPAS,TPMS,EPB,LCA,SPAS,TPMS
 SG_ WHL_PUL_Chksum : 40|8@1+ (1.0,0.0) [0.0|255.0] ""  EPB,SPAS,TPMS,EPB,LCA,LDWS_LKAS,SPAS,TPMS

BO_ 1415 TMU11: 8 IBOX
 SG_ CF_Tmu_VehSld : 0|1@1+ (1.0,0.0) [0.0|1.0] ""  EMS
 SG_ CF_Tmu_VehImmo : 1|1@1+ (1.0,0.0) [0.0|1.0] ""  EMS
 SG_ CF_Tmu_ReqRepCnd : 2|2@1+ (1.0,0.0) [0.0|3.0] ""  EMS
 SG_ CF_Tmu_AirconCtr : 4|1@1+ (1.0,0.0) [0.0|1.0] ""  DATC
 SG_ CF_Tmu_TempMd : 5|1@1+ (1.0,0.0) [0.0|1.0] ""  DATC
 SG_ CF_Tmu_TempSet : 6|16@1+ (1.0,0.0) [0.0|20.0] ""  DATC
 SG_ CF_Tmu_DefrostCtr : 22|1@1+ (1.0,0.0) [0.0|1.0] ""  DATC,FATC
 SG_ CF_Tmu_AliveCnt1 : 56|4@1+ (1.0,0.0) [0.0|15.0] ""  EMS

BO_ 902 WHL_SPD11: 8 ABS
 SG_ WHL_SPD_FL : 0|14@1+ (0.03125,0.0) [0.0|511.96875] "km/h"  _4WD,AFLS,AHLS,AVM,CLU,CUBIS,ECS,EMS,EPB,IBOX,LDWS_LKAS,PGS,PSB,SCC,SMK,SPAS,TCU,TPMS,_4WD,ACU,AFLS,AHLS,AVM,CLU,ECS,EMS,EPB,IBOX,LCA,LDWS_LKAS,PGS,PSB,SCC,SMK,SPAS,TCU,TPMS
 SG_ WHL_SPD_FR : 16|14@1+ (0.03125,0.0) [0.0|511.96875] "km/h"  _4WD,ACU,AFLS,AHLS,AVM,CLU,CUBIS,ECS,EMS,EPB,IBOX,LDWS_LKAS,PGS,PSB,SCC,SMK,SPAS,TCU,TPMS,_4WD,ACU,AFLS,AHLS,AVM,CLU,ECS,EMS,EPB,IBOX,LCA,LDWS_LKAS,PGS,PSB,SCC,SMK,SPAS,TCU,TPMS
 SG_ WHL_SPD_RL : 32|14@1+ (0.03125,0.0) [0.0|511.96875] "km/h"  _4WD,AFLS,AHLS,AVM,BCM,CLU,CUBIS,ECS,EMS,EPB,IBOX,LDWS_LKAS,PGS,PSB,SCC,SMK,SPAS,TCU,TPMS,_4WD,ACU,AFLS,AHLS,AVM,BCM,CLU,ECS,EMS,EPB,IBOX,LCA,LDWS_LKAS,PGS,PSB,SCC,SMK,SPAS,TCU,TPMS
 SG_ WHL_SPD_RR : 48|14@1+ (0.03125,0.0) [0.0|511.96875] "km/h"  _4WD,AFLS,AHLS,AVM,CLU,CUBIS,ECS,EMS,EPB,IBOX,LDWS_LKAS,PGS,PSB,SCC,SMK,SPAS,TCU,TPMS,_4WD,ACU,AFLS,AHLS,AVM,CLU,ECS,EMS,EPB,IBOX,LCA,LDWS_LKAS,PGS,PSB,SCC,SMK,SPAS,TCU,TPMS
 SG_ WHL_SPD_AliveCounter_LSB : 14|2@1+ (1.0,0.0) [0.0|15.0] ""  _4WD,EMS,LPI,TCU,TMU
 SG_ WHL_SPD_AliveCounter_MSB : 30|2@1+ (1.0,0.0) [0.0|15.0] ""  _4WD,EMS,LPI,TCU,TMU
 SG_ WHL_SPD_Checksum_LSB : 46|2@1+ (1.0,0.0) [0.0|15.0] ""  _4WD,EMS,LPI,TCU,TMU
 SG_ WHL_SPD_Checksum_MSB : 62|2@1+ (1.0,0.0) [0.0|15.0] ""  _4WD,EMS,LPI,TCU,TMU

BO_ 1414 EVP11: 3 EVP
 SG_ CF_Evp_Stat : 0|1@1+ (1.0,0.0) [0.0|1.0] ""  CLU

BO_ 1412 AAF11: 8 AAF
 SG_ CF_Aaf_ActFlapStatus : 0|2@1+ (1.0,0.0) [0.0|3.0] ""  AAF_Tester
 SG_ CF_Aaf_ModeStatus : 2|3@1+ (1.0,0.0) [0.0|7.0] ""  AAF_Tester
 SG_ CF_Aaf_WrnLamp : 5|1@1+ (1.0,0.0) [0.0|1.0] ""  CLU
 SG_ CF_Aaf_ErrStatus : 6|10@1+ (1.0,0.0) [0.0|1023.0] ""  AAF_Tester,EMS
 SG_ CF_Aaf_OpenRqSysAct : 16|8@1+ (1.0,0.0) [0.0|255.0] ""  AAF_Tester
 SG_ CF_Aaf_PStatus : 24|8@1+ (1.0,0.0) [0.0|100.0] "%"  AAF_Tester
 SG_ CF_Aaf_OpenRqSysSol : 32|8@1+ (1.0,0.0) [0.0|255.0] ""  AAF_Tester
 SG_ CF_Aaf_SolFlapStatus : 40|2@1+ (1.0,0.0) [0.0|3.0] ""  AAF_Tester
 SG_ CF_Aaf_MilOnReq : 42|1@1+ (1.0,0.0) [0.0|1.0] ""  EMS

BO_ 900 EMS17: 8 EMS
 SG_ CF_Ems_PkpCurMSV : 0|8@1+ (1.0,0.0) [0.0|255.0] ""  DI_BOX
 SG_ CF_Ems_HolCurMSV : 8|8@1+ (1.0,0.0) [0.0|255.0] ""  DI_BOX
 SG_ CF_Ems_InjVBnkAct : 16|8@1+ (1.0,0.0) [0.0|255.0] ""  DI_BOX
 SG_ CF_Ems_InjVActSet : 24|8@1+ (1.0,0.0) [0.0|255.0] ""  DI_BOX
 SG_ CF_Ems_DiagFulHDEV : 32|1@1+ (1.0,0.0) [0.0|1.0] ""  DI_BOX
 SG_ CF_Ems_SwiOffIC1 : 33|1@1+ (1.0,0.0) [0.0|1.0] ""  DI_BOX
 SG_ CF_Ems_SwiOffIC2 : 34|1@1+ (1.0,0.0) [0.0|1.0] ""  DI_BOX
 SG_ CF_Ems_DiagReqHDEV : 38|1@1+ (1.0,0.0) [0.0|1.0] ""  DI_BOX
 SG_ CR_Ems_DutyCycMSV : 40|8@1+ (0.3921568627,0.0) [0.0|100.0] "%"  DI_BOX
 SG_ CR_Ems_BatVolRly : 48|8@1+ (0.1,0.0) [0.0|25.5] "V"  DI_BOX

BO_ 1411 CUBIS11: 8 CUBIS
 SG_ CF_Cubis_HUDisp : 0|4@1+ (1.0,0.0) [0.0|15.0] ""  CLU

BO_ 899 FATC11: 8 DATC
 SG_ CR_Fatc_TqAcnOut : 0|8@1+ (0.2,0.0) [0.0|50.8] "Nm"  EMS,IBOX
 SG_ CF_Fatc_AcnRqSwi : 8|1@1+ (1.0,0.0) [0.0|1.0] ""  AAF,EMS,IBOX
 SG_ CF_Fatc_AcnCltEnRq : 9|1@1+ (1.0,0.0) [0.0|1.0] ""  EMS,IBOX
 SG_ CF_Fatc_EcvFlt : 10|1@1+ (1.0,0.0) [0.0|1.0] ""  EMS,IBOX
 SG_ CF_Fatc_BlwrOn : 11|1@1+ (1.0,0.0) [0.0|1.0] ""  EMS,IBOX
 SG_ CF_FATC_Iden : 12|2@1+ (1.0,0.0) [0.0|3.0] ""  EMS,IBOX
 SG_ CF_Fatc_BlwrMax : 14|1@1+ (1.0,0.0) [0.0|1.0] ""  CLU,EMS,IBOX
 SG_ CF_Fatc_EngStartReq : 15|1@1+ (1.0,0.0) [0.0|1.0] ""  EMS,IBOX
 SG_ CF_Fatc_IsgStopReq : 16|1@1+ (1.0,0.0) [0.0|1.0] ""  EMS,IBOX
 SG_ CF_Fatc_CtrInf : 17|3@1+ (1.0,0.0) [0.0|7.0] ""  EMS,IBOX
 SG_ CF_Fatc_MsgCnt : 20|4@1+ (1.0,0.0) [0.0|15.0] ""  EMS,IBOX
 SG_ CR_Fatc_OutTemp : 24|8@1+ (0.5,-40.0) [-40.0|60.0] "deg"  BCM,CLU,EMS,IBOX,SPAS,TCU,TPMS
 SG_ CR_Fatc_OutTempSns : 32|8@1+ (0.5,-40.0) [-40.0|60.0] "deg"  AAF,AHLS,CLU,EMS,IBOX,SPAS,TCU
 SG_ CF_Fatc_Compload : 40|3@1+ (1.0,0.0) [0.0|7.0] ""  EMS,IBOX
 SG_ CF_Fatc_ActiveEco : 43|1@1+ (1.0,0.0) [0.0|1.0] ""  CLU,IBOX
 SG_ CF_Fatc_AutoActivation : 44|1@1+ (1.0,0.0) [0.0|1.0] ""  IBOX
 SG_ CF_Fatc_DefSw : 45|1@1+ (1.0,0.0) [0.0|1.0] ""  BCM,IBOX
 SG_ CF_Fatc_PtcRlyStat : 46|1@1+ (1.0,0.0) [0.0|1.0] ""  EMS,IBOX
 SG_ CF_Fatc_ChkSum : 56|8@1+ (1.0,0.0) [0.0|255.0] ""  EMS,IBOX,SPAS

BO_ 129 EMS_DCT12: 8 EMS
 SG_ CR_Ems_SoakTimeExt : 0|6@1+ (5.0,0.0) [0.0|315.0] "Min"  TCU
 SG_ BRAKE_ACT : 6|2@1+ (1.0,0.0) [0.0|3.0] ""  TCU
 SG_ CF_Ems_EngOperStat : 8|8@1+ (1.0,0.0) [0.0|255.0] ""  TCU
 SG_ CR_Ems_IndAirTemp : 16|8@1+ (0.75,-48.0) [-48.0|143.25] "deg"  TCU
 SG_ CF_Ems_Alive2 : 56|4@1+ (1.0,0.0) [0.0|15.0] ""  TCU
 SG_ CF_Ems_ChkSum2 : 60|4@1+ (1.0,0.0) [0.0|15.0] ""  TCU

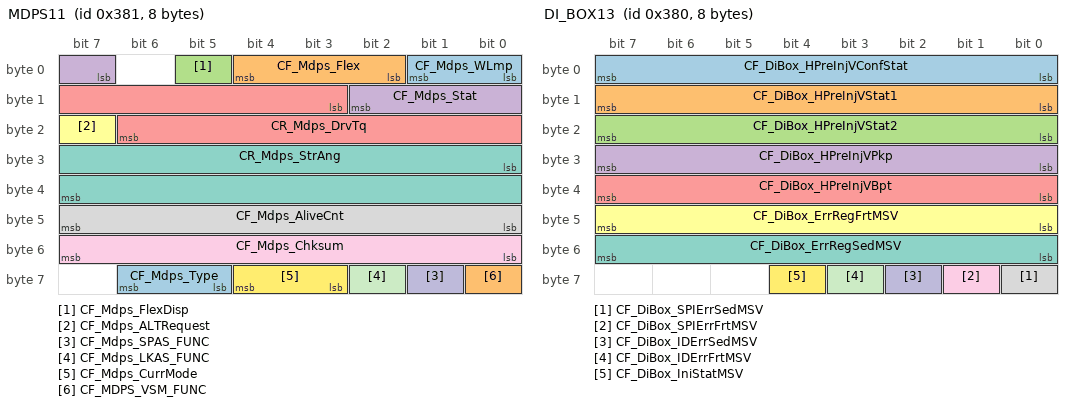
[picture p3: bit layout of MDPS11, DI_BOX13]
BO_ 897 MDPS11: 8 MDPS
 SG_ CF_Mdps_WLmp : 0|2@1+ (1.0,0.0) [0.0|3.0] ""  CLU,CUBIS,EMS,IBOX,SPAS
 SG_ CF_Mdps_Flex : 2|3@1+ (1.0,0.0) [0.0|3.0] ""  CLU,LDWS_LKAS
 SG_ CF_Mdps_FlexDisp : 5|1@1+ (1.0,0.0) [0.0|1.0] ""  CLU
 SG_ CF_Mdps_Stat : 7|4@1+ (1.0,0.0) [0.0|15.0] ""  SPAS
 SG_ CR_Mdps_DrvTq : 11|12@1+ (1.0,-2048.0) [-2048.0|2046.0] ""  SPAS
 SG_ CF_Mdps_ALTRequest : 23|1@1+ (1.0,0.0) [0.0|1.0] ""  EMS
 SG_ CR_Mdps_StrAng : 24|16@1- (0.1,0.0) [-3276.8|3276.7] "Deg"  SPAS
 SG_ CF_Mdps_AliveCnt : 40|8@1+ (1.0,0.0) [0.0|255.0] ""  LDWS_LKAS,SPAS
 SG_ CF_Mdps_Chksum : 48|8@1+ (1.0,0.0) [0.0|255.0] ""  LDWS_LKAS,SPAS
 SG_ CF_Mdps_SPAS_FUNC : 57|1@1+ (1.0,0.0) [0.0|1.0] "flag"  SPAS
 SG_ CF_Mdps_LKAS_FUNC : 58|1@1+ (1.0,0.0) [0.0|1.0] "flag"  LDWS_LKAS
 SG_ CF_Mdps_CurrMode : 59|2@1+ (1.0,0.0) [0.0|3.0] ""  LDWS_LKAS
 SG_ CF_Mdps_Type : 61|2@1+ (1.0,0.0) [0.0|2.0] ""  LDWS_LKAS,SPAS
 SG_ CF_MDPS_VSM_FUNC : 56|1@0+ (1.0,0.0) [0.0|1.0] "" XXX

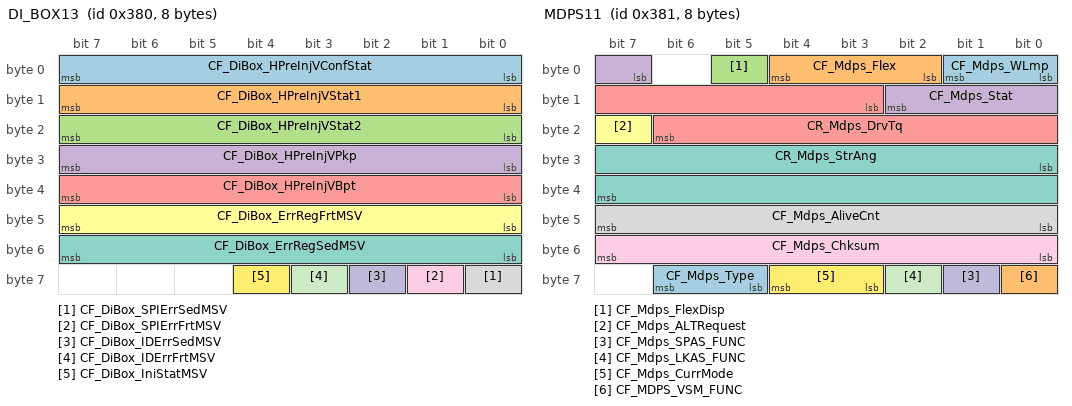
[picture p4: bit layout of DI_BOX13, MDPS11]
BO_ 896 DI_BOX13: 8 DI_BOX
 SG_ CF_DiBox_HPreInjVConfStat : 0|8@1+ (1.0,0.0) [0.0|255.0] ""  EMS
 SG_ CF_DiBox_HPreInjVStat1 : 8|8@1+ (1.0,0.0) [0.0|255.0] ""  EMS
 SG_ CF_DiBox_HPreInjVStat2 : 16|8@1+ (1.0,0.0) [0.0|255.0] ""  EMS
 SG_ CF_DiBox_HPreInjVPkp : 24|8@1+ (1.0,0.0) [0.0|255.0] ""  EMS
 SG_ CF_DiBox_HPreInjVBpt : 32|8@1+ (1.0,0.0) [0.0|255.0] ""  EMS
 SG_ CF_DiBox_ErrRegFrtMSV : 40|8@1+ (1.0,0.0) [0.0|255.0] ""  EMS
 SG_ CF_DiBox_ErrRegSedMSV : 48|8@1+ (1.0,0.0) [0.0|255.0] ""  EMS
 SG_ CF_DiBox_SPIErrSedMSV : 56|1@1+ (1.0,0.0) [0.0|1.0] ""  EMS
 SG_ CF_DiBox_SPIErrFrtMSV : 57|1@1+ (1.0,0.0) [0.0|1.0] ""  EMS
 SG_ CF_DiBox_IDErrSedMSV : 58|1@1+ (1.0,0.0) [0.0|1.0] ""  EMS
 SG_ CF_DiBox_IDErrFrtMSV : 59|1@1+ (1.0,0.0) [0.0|1.0] ""  EMS
 SG_ CF_DiBox_IniStatMSV : 60|1@1+ (1.0,0.0) [0.0|1.0] ""  EMS

BO_ 640 EMS13: 8 EMS
 SG_ LV_FUEL_TYPE_ECU : 0|1@1+ (1.0,0.0) [0.0|1.0] ""  BCM,CLU,LPI,SMK
 SG_ LV_BFS_CFIRM : 1|1@1+ (1.0,0.0) [0.0|1.0] ""  LPI
 SG_ LV_CRASH : 2|1@1+ (1.0,0.0) [0.0|1.0] ""  LPI
 SG_ LV_VB_OFF_ACT : 3|1@1+ (1.0,0.0) [0.0|1.0] ""  LPI
 SG_ LV_GSL_MAP M : 4|1@1+ (1.0,0.0) [0.0|1.0] ""  LPI
 SG_ LV_ENG_TURN : 5|1@1+ (1.0,0.0) [0.0|1.0] ""  LPI
 SG_ ERR_FUEL : 8|8@1+ (1.0,0.0) [0.0|255.0] ""  LPI
 SG_ EOS : 16|8@1+ (1.0,0.0) [0.0|255.0] ""  LPI
 SG_ TCO : 24|8@1+ (0.75,-48.0) [-48.0|143.25] "deg"  LPI
 SG_ N_32 : 32|8@1+ (32.0,0.0) [0.0|8160.0] "rpm"  LPI
 SG_ MAF : 40|8@1+ (5.447,0.0) [0.0|1388.985] "mg/TDC"  LPI
 SG_ TIA : 48|8@1+ (0.75,-48.0) [-48.0|143.25] "deg"  LPI
 SG_ MAP m1 : 56|8@1+ (0.47058,0.0) [0.0|119.9979] "kPa"  LPI
 SG_ AMP m0 : 56|8@1+ (21.22,0.0) [0.0|5411.1] "hPa"  LPI

BO_ 128 EMS_DCT11: 8 EMS
 SG_ PV_AV_CAN : 0|8@1+ (0.3906,0.0) [0.0|99.603] "%"  TCU
 SG_ TQ_STND : 8|6@1+ (10.0,0.0) [0.0|630.0] "Nm"  TCU
 SG_ F_N_ENG : 14|1@1+ (1.0,0.0) [0.0|1.0] ""  TCU
 SG_ F_SUB_TQI : 15|1@1+ (1.0,0.0) [0.0|1.0] ""  TCU
 SG_ N : 16|16@1+ (0.25,0.0) [0.0|16383.75] "rpm"  TCU
 SG_ TQI_ACOR : 32|8@1+ (0.390625,0.0) [0.0|99.6094] "%"  IBOX,TCU
 SG_ TQFR : 40|8@1+ (0.390625,0.0) [0.0|99.6094] "%"  TCU
 SG_ TQI : 48|8@1+ (0.390625,0.0) [0.0|99.609375] "%"  TCU
 SG_ CF_Ems_Alive : 56|4@1+ (1.0,0.0) [0.0|15.0] ""  TCU
 SG_ CF_Ems_ChkSum : 60|4@1+ (1.0,0.0) [0.0|15.0] ""  TCU

BO_ 1407 HU_MON_PE_01: 8 CLU
 SG_ HU_Type : 0|8@1+ (1.0,0.0) [0.0|255.0] ""  AVM,PGS

BO_ 127 CGW5: 8 BCM
 SG_ C_StopLampLhOpenSts : 0|1@1+ (1.0,0.0) [0.0|1.0] ""  CLU
 SG_ C_StopLampRhOpenSts : 1|1@1+ (1.0,0.0) [0.0|1.0] ""  CLU
 SG_ C_HMSLOpenSts : 2|1@1+ (1.0,0.0) [0.0|1.0] ""  CLU
 SG_ C_HLampLowLhOpenSts : 3|1@1+ (1.0,0.0) [0.0|1.0] ""  CLU
 SG_ C_HLampLowRhOpenSts : 4|1@1+ (1.0,0.0) [0.0|1.0] ""  CLU
 SG_ C_HLampHighLhOpenSts : 5|1@1+ (1.0,0.0) [0.0|1.0] ""  CLU
 SG_ C_HLampHighRhOpenSts : 6|1@1+ (1.0,0.0) [0.0|1.0] ""  CLU
 SG_ C_DRLLampLhOpenSts : 7|1@1+ (1.0,0.0) [0.0|1.0] ""  CLU
 SG_ C_DRLLampRhOpenSts : 8|1@1+ (1.0,0.0) [0.0|1.0] ""  CLU
 SG_ C_RearFOGLhOpenSts : 9|1@1+ (1.0,0.0) [0.0|1.0] ""  CLU
 SG_ C_RearFOGRhOpenSts : 10|1@1+ (1.0,0.0) [0.0|1.0] ""  CLU
 SG_ C_FrontFOGLhOpenSts : 11|1@1+ (1.0,0.0) [0.0|1.0] ""  CLU
 SG_ C_FrontFOGRhOpenSts : 12|1@1+ (1.0,0.0) [0.0|1.0] ""  CLU
 SG_ C_RearEXTTailLhOpenSts : 13|1@1+ (1.0,0.0) [0.0|1.0] ""  CLU
 SG_ C_RearEXTTailRhOpenSts : 14|1@1+ (1.0,0.0) [0.0|1.0] ""  CLU
 SG_ C_FrontEXTTailLhOpenSts : 15|1@1+ (1.0,0.0) [0.0|1.0] ""  CLU
 SG_ C_FrontEXTTailRhOpenSts : 16|1@1+ (1.0,0.0) [0.0|1.0] ""  CLU
 SG_ C_RearTSIGLhOpenSts : 17|1@1+ (1.0,0.0) [0.0|1.0] ""  CLU
 SG_ C_RearTSIGRhOpenSts : 18|1@1+ (1.0,0.0) [0.0|1.0] ""  CLU
 SG_ C_FrontTSIGLhOpenSts : 19|1@1+ (1.0,0.0) [0.0|1.0] ""  CLU
 SG_ C_FrontTSIGRhOpenSts : 20|1@1+ (1.0,0.0) [0.0|1.0] ""  CLU
 SG_ C_SBendingLhOpenSts : 21|1@1+ (1.0,0.0) [0.0|1.0] ""  CLU
 SG_ C_SBendingRhOpenSts : 22|1@1+ (1.0,0.0) [0.0|1.0] ""  CLU
 SG_ C_LicensePlateLhOpenSts : 23|1@1+ (1.0,0.0) [0.0|1.0] ""  CLU
 SG_ C_LicensePlateRhOpenSts : 24|1@1+ (1.0,0.0) [0.0|1.0] ""  CLU

BO_ 354 TCU_DCT13: 3 TCU
 SG_ Clutch_Driving_Tq : 0|10@1+ (1.0,-512.0) [0.0|0.0] "Nm"  ESC
 SG_ Cluster_Engine_RPM : 10|13@1+ (0.9766,0.0) [0.0|0.0] ""  CLU
 SG_ Cluster_Engine_RPM_Flag : 23|1@1+ (1.0,0.0) [0.0|0.0] ""  CLU

BO_ 127 CGW5: 8 BCM
 SG_ C_StopLampLhOpenSts : 0|1@1+ (1.0,0.0) [0.0|1.0] ""  CLU
 SG_ C_StopLampRhOpenSts : 1|1@1+ (1.0,0.0) [0.0|1.0] ""  CLU
 SG_ C_HMSLOpenSts : 2|1@1+ (1.0,0.0) [0.0|1.0] ""  CLU
 SG_ C_HLampLowLhOpenSts : 3|1@1+ (1.0,0.0) [0.0|1.0] ""  CLU
 SG_ C_HLampLowRhOpenSts : 4|1@1+ (1.0,0.0) [0.0|1.0] ""  CLU
 SG_ C_HLampHighLhOpenSts : 5|1@1+ (1.0,0.0) [0.0|1.0] ""  CLU
 SG_ C_HLampHighRhOpenSts : 6|1@1+ (1.0,0.0) [0.0|1.0] ""  CLU
 SG_ C_DRLLampLhOpenSts : 7|1@1+ (1.0,0.0) [0.0|1.0] ""  CLU
 SG_ C_DRLLampRhOpenSts : 8|1@1+ (1.0,0.0) [0.0|1.0] ""  CLU
 SG_ C_RearFOGLhOpenSts : 9|1@1+ (1.0,0.0) [0.0|1.0] ""  CLU
 SG_ C_RearFOGRhOpenSts : 10|1@1+ (1.0,0.0) [0.0|1.0] ""  CLU
 SG_ C_FrontFOGLhOpenSts : 11|1@1+ (1.0,0.0) [0.0|1.0] ""  CLU
 SG_ C_FrontFOGRhOpenSts : 12|1@1+ (1.0,0.0) [0.0|1.0] ""  CLU
 SG_ C_RearEXTTailLhOpenSts : 13|1@1+ (1.0,0.0) [0.0|1.0] ""  CLU
 SG_ C_RearEXTTailRhOpenSts : 14|1@1+ (1.0,0.0) [0.0|1.0] ""  CLU
 SG_ C_FrontEXTTailLhOpenSts : 15|1@1+ (1.0,0.0) [0.0|1.0] ""  CLU
 SG_ C_FrontEXTTailRhOpenSts : 16|1@1+ (1.0,0.0) [0.0|1.0] ""  CLU
 SG_ C_RearTSIGLhOpenSts : 17|1@1+ (1.0,0.0) [0.0|1.0] ""  CLU
 SG_ C_RearTSIGRhOpenSts : 18|1@1+ (1.0,0.0) [0.0|1.0] ""  CLU
 SG_ C_FrontTSIGLhOpenSts : 19|1@1+ (1.0,0.0) [0.0|1.0] ""  CLU
 SG_ C_FrontTSIGRhOpenSts : 20|1@1+ (1.0,0.0) [0.0|1.0] ""  CLU
 SG_ C_SBendingLhOpenSts : 21|1@1+ (1.0,0.0) [0.0|1.0] ""  CLU
 SG_ C_SBendingRhOpenSts : 22|1@1+ (1.0,0.0) [0.0|1.0] ""  CLU
 SG_ C_LicensePlateLhOpenSts : 23|1@1+ (1.0,0.0) [0.0|1.0] ""  CLU
 SG_ C_LicensePlateRhOpenSts : 24|1@1+ (1.0,0.0) [0.0|1.0] ""  CLU

BO_ 128 EMS_DCT11: 8 EMS
 SG_ PV_AV_CAN : 0|8@1+ (0.3906,0.0) [0.0|99.603] "%"  TCU
 SG_ TQ_STND : 8|6@1+ (10.0,0.0) [0.0|630.0] "Nm"  TCU
 SG_ F_N_ENG : 14|1@1+ (1.0,0.0) [0.0|1.0] ""  TCU
 SG_ F_SUB_TQI : 15|1@1+ (1.0,0.0) [0.0|1.0] ""  TCU
 SG_ N : 16|16@1+ (0.25,0.0) [0.0|16383.75] "rpm"  TCU
 SG_ TQI_ACOR : 32|8@1+ (0.390625,0.0) [0.0|99.6094] "%"  IBOX,TCU
 SG_ TQFR : 40|8@1+ (0.390625,0.0) [0.0|99.6094] "%"  TCU
 SG_ TQI : 48|8@1+ (0.390625,0.0) [0.0|99.609375] "%"  TCU
 SG_ CF_Ems_Alive : 56|4@1+ (1.0,0.0) [0.0|15.0] ""  TCU
 SG_ CF_Ems_ChkSum : 60|4@1+ (1.0,0.0) [0.0|15.0] ""  TCU

BO_ 129 EMS_DCT12: 8 EMS
 SG_ CR_Ems_SoakTimeExt : 0|6@1+ (5.0,0.0) [0.0|315.0] "Min"  TCU
 SG_ BRAKE_ACT : 6|2@1+ (1.0,0.0) [0.0|3.0] ""  TCU
 SG_ CF_Ems_EngOperStat : 8|8@1+ (1.0,0.0) [0.0|255.0] ""  TCU
 SG_ CR_Ems_IndAirTemp : 16|8@1+ (0.75,-48.0) [-48.0|143.25] "deg"  TCU
 SG_ CF_Ems_Alive2 : 56|4@1+ (1.0,0.0) [0.0|15.0] ""  TCU
 SG_ CF_Ems_ChkSum2 : 60|4@1+ (1.0,0.0) [0.0|15.0] ""  TCU

BO_ 353 MSG_161: 32 CCNC
 SG_ CHECKSUM : 0|16@1+ (1,0) [0|65535] "" XXX
 SG_ COUNTER : 16|8@1+ (1,0) [0|255] "" XXX
 SG_ FCA_ICON : 24|3@1+ (1,0) [0|7] "" XXX
 SG_ FCA_ALT_ICON : 27|3@1+ (1,0) [0|7] "" XXX
 SG_ LKA_ICON : 30|3@1+ (1,0) [0|3] "" XXX
 SG_ HBA_ICON : 33|3@1+ (1,0) [0|7] "" XXX
 SG_ ZEROS_1 : 36|4@1+ (1,0) [0|15] "" XXX
 SG_ ZEROS_2 : 40|2@1+ (1,0) [0|3] "" XXX
 SG_ FCA_IMAGE : 42|3@1+ (1,0) [0|7] "" XXX
 SG_ ZEROS_3 : 45|3@1+ (1,0) [0|7] "" XXX
 SG_ ZEROS_4 : 48|3@1+ (1,0) [0|7] "" XXX
 SG_ BCA_LEFT : 51|3@1+ (1,0) [0|7] "" XXX
 SG_ BCA_RIGHT : 54|3@1+ (1,0) [0|7] "" XXX
 SG_ LCA_LEFT_ARROW : 57|3@1+ (1,0) [0|7] "" XXX
 SG_ LCA_RIGHT_ARROW : 60|3@1+ (1,0) [0|7] "" XXX
 SG_ ZEROS_5 : 63|1@0+ (1,0) [0|1] "" XXX
 SG_ CENTERLINE : 64|2@1+ (1,0) [0|3] "" XXX
 SG_ TARGET : 66|3@1+ (1,0) [0|7] "" XXX
 SG_ TARGET_POSITION : 69|11@1+ (1,0) [0|7] "" XXX
 SG_ LANELINE_LEFT : 80|4@1+ (1,0) [0|15] "" XXX
 SG_ LANELINE_LEFT_POSITION : 84|6@1+ (1,0) [0|15] "" XXX
 SG_ LANELINE_RIGHT : 90|4@1+ (1,0) [0|15] "" XXX
 SG_ LANELINE_RIGHT_POSITION : 94|6@1+ (1,0) [0|3] "" XXX
 SG_ LANELINE_CURVATURE : 100|5@1- (1,15) [0|31] "" XXX
 SG_ LANE_HIGHLIGHT : 105|4@1+ (1,0) [0|15] "" XXX
 SG_ LANE_HIGHLIGHT_DISTANCE : 109|11@1+ (1,0) [0|7] "" XXX
 SG_ LANE_LEFT : 120|3@1+ (1,0) [0|7] "" XXX
 SG_ LANE_RIGHT : 123|3@1+ (1,0) [0|7] "" XXX
 SG_ LANE_ZOOM : 126|2@1+ (1,0) [0|3] "" XXX
 SG_ ALERTS_1 : 128|6@1+ (1,0) [0|63] "" XXX
 SG_ ALERTS_2 : 134|5@1+ (1,0) [0|3] "" XXX
 SG_ ALERTS_3 : 139|4@1+ (1,0) [0|15] "" XXX
 SG_ ALERTS_4 : 143|9@1+ (1,0) [0|511] "" XXX
 SG_ ALERTS_5 : 152|5@1+ (1,0) [0|7] "" XXX
 SG_ MUTE : 157|3@1+ (1,0) [0|7] "" XXX
 SG_ SOUNDS_1 : 160|4@1+ (1,0) [0|3] "" XXX
 SG_ SOUNDS_2 : 164|4@1+ (1,0) [0|3] "" XXX
 SG_ SOUNDS_3 : 168|4@1+ (1,0) [0|15] "" XXX
 SG_ SOUNDS_4 : 172|3@1+ (1,0) [0|7] "" XXX
 SG_ ZEROS_6 : 175|1@0+ (1,0) [0|1] "" XXX
 SG_ ZEROS_7 : 176|5@1+ (1,0) [0|31] "" XXX
 SG_ SETSPEED_HUD : 181|3@1+ (1,0) [0|3] "" XXX
 SG_ DISTANCE_LEAD : 184|5@1+ (1,0) [0|31] "" XXX
 SG_ DISTANCE_CAR : 189|3@1+ (1,0) [0|7] "" XXX
 SG_ DISTANCE_SPACING : 192|4@1+ (1,0) [0|15] "" XXX
 SG_ DISTANCE : 196|4@1+ (1,0) [0|7] "" XXX
 SG_ SETSPEED_SPEED : 200|8@1+ (1,0) [0|255] "" XXX
 SG_ SETSPEED : 208|4@1+ (1,0) [0|3] "" XXX
 SG_ HDA_ICON : 212|4@1+ (1,0) [0|3] "" XXX
 SG_ SLA_ICON : 216|4@1+ (1,0) [0|15] "" XXX
 SG_ NAV_ICON : 220|4@1+ (1,0) [0|3] "" XXX
 SG_ LFA_ICON : 224|4@1+ (1,0) [0|3] "" XXX
 SG_ LCA_LEFT_ICON : 228|4@1+ (1,0) [0|15] "" XXX
 SG_ LCA_RIGHT_ICON : 232|4@1+ (1,0) [0|15] "" XXX
 SG_ BACKGROUND : 236|4@1+ (1,0) [0|15] "" XXX
 SG_ DAW_ICON : 240|3@1+ (1,0) [0|7] "" XXX
 SG_ CAR_CIRCLE : 243|3@1+ (1,0) [0|7] "" XXX
 SG_ ZEROS_8 : 246|2@1+ (1,0) [0|3] "" XXX
 SG_ ZEROS_9 : 248|8@1+ (1,0) [0|255] "" XXX

BO_ 354 MSG_162: 32 CCNC
 SG_ CHECKSUM : 0|16@1+ (1,0) [0|65535] "" XXX
 SG_ COUNTER : 16|8@1+ (1,0) [0|255] "" XXX
 SG_ SPEEDLIMIT_STYLE : 24|4@1+ (1,0) [0|7] "" XXX
 SG_ SPEEDLIMIT_FLASH : 28|4@1+ (1,0) [0|15] "" XXX
 SG_ SPEEDLIMIT : 32|8@1+ (1,0) [0|255] "" XXX
 SG_ SIGNS : 40|8@1+ (1,0) [0|15] "" XXX
 SG_ SPEEDLIMIT_WEATHER : 48|4@1+ (1,0) [0|15] "" XXX
 SG_ VIBRATE : 52|3@1+ (1,0) [0|7] "" XXX
 SG_ ZEROS_1 : 55|1@0+ (1,0) [0|1] "" XXX
 SG_ ZEROS_2 : 56|8@1+ (1,0) [0|255] "" XXX
 SG_ LEAD : 64|5@1+ (1,0) [0|31] "" XXX
 SG_ LEAD_DISTANCE : 69|11@1+ (1,0) [0|2047] "" XXX
 SG_ LEAD_LATERAL : 80|7@1+ (1,0) [0|127] "" XXX
 SG_ ZEROS_3 : 87|1@0+ (1,0) [0|1] "" XXX
 SG_ LEAD_ALT : 88|5@1+ (1,0) [0|31] "" XXX
 SG_ LEAD_ALT_DISTANCE : 93|11@1+ (1,0) [0|2047] "" XXX
 SG_ LEAD_ALT_LATERAL : 104|7@1+ (1,0) [0|127] "" XXX
 SG_ ZEROS_4 : 111|1@0+ (1,0) [0|1] "" XXX
 SG_ LEAD_LEFT : 112|5@1+ (1,0) [0|31] "" XXX
 SG_ LEAD_LEFT_DISTANCE : 117|11@1+ (1,0) [0|2047] "" XXX
 SG_ LEAD_LEFT_LATERAL : 128|7@1+ (1,0) [0|127] "" XXX
 SG_ ZEROS_5 : 135|1@0+ (1,0) [0|1] "" XXX
 SG_ LEAD_RIGHT : 136|5@1+ (1,0) [0|31] "" XXX
 SG_ LEAD_RIGHT_DISTANCE : 141|11@1+ (1,0) [0|2047] "" XXX
 SG_ LEAD_RIGHT_LATERAL : 152|7@1+ (1,0) [0|127] "" XXX
 SG_ ZEROS_6 : 159|1@0+ (1,0) [0|1] "" XXX
 SG_ ZEROS_7 : 160|8@1+ (1,0) [0|255] "" XXX
 SG_ ZEROS_8 : 168|8@1+ (1,0) [0|255] "" XXX
 SG_ ZEROS_9 : 176|8@1+ (1,0) [0|255] "" XXX
 SG_ ZEROS_10 : 184|8@1+ (1,0) [0|255] "" XXX
 SG_ ZEROS_11 : 192|8@1+ (1,0) [0|255] "" XXX
 SG_ ZEROS_12 : 200|8@1+ (1,0) [0|255] "" XXX
 SG_ ZEROS_13 : 208|5@1+ (1,0) [0|31] "" XXX
 SG_ FAULT_FSS : 213|3@1+ (1,0) [0|7] "" XXX
 SG_ FAULT_FCA : 216|3@1+ (1,0) [0|7] "" XXX
 SG_ FAULT_LSS : 219|3@1+ (1,0) [0|7] "" XXX
 SG_ FAULT_SLA : 222|3@1+ (1,0) [0|7] "" XXX
 SG_ FAULT_DAW : 225|3@1+ (1,0) [0|7] "" XXX
 SG_ FAULT_HBA : 228|3@1+ (1,0) [0|7] "" XXX
 SG_ FAULT_SCC : 231|3@1+ (1,0) [0|7] "" XXX
 SG_ FAULT_LFA : 234|3@1+ (1,0) [0|7] "" XXX
 SG_ FAULT_HDA : 237|3@1+ (1,0) [0|7] "" XXX
 SG_ FAULT_LCA : 240|3@1+ (1,0) [0|7] "" XXX
 SG_ FAULT_HDP : 243|3@1+ (1,0) [0|7] "" XXX
 SG_ FAULT_DAS : 246|3@1+ (1,0) [0|7] "" XXX
 SG_ FAULT_ESS : 249|3@1+ (1,0) [0|7] "" XXX
 SG_ ZEROS_14 : 252|4@1+ (1,0) [0|15] "" XXX

BO_ 399 EMS_H12: 8 EMS
 SG_ R_TqAcnApvC : 0|8@1+ (0.2,0.0) [0.0|51.0] "Nm"  DATC,IBOX
 SG_ R_PAcnC : 8|8@1+ (125.0,0.0) [0.0|31875.0] "hPa"  DATC,IBOX
 SG_ TQI_B : 16|8@1+ (0.390625,0.0) [0.0|99.609375] "%"  ABS,ESC,IBOX
 SG_ SLD_VS : 24|8@1+ (1.0,0.0) [0.0|255.0] "km/h"  CLU,IBOX
 SG_ CF_CdaStat : 32|3@1+ (1.0,0.0) [0.0|7.0] ""  AEMC,IBOX,TCU
 SG_ CF_Ems_IsgStat : 35|3@1+ (1.0,0.0) [0.0|7.0] ""  ABS,BCM,CLU,DATC,EPB,ESC,IBOX,LDWS_LKAS,MDPS,SMK,TCU
 SG_ CF_Ems_OilChg : 38|1@1+ (1.0,0.0) [0.0|1.0] ""  CLU,IBOX
 SG_ CF_Ems_EtcLimpMod : 39|1@1+ (1.0,0.0) [0.0|1.0] ""  CLU,IBOX
 SG_ R_NEngIdlTgC : 40|8@1+ (10.0,0.0) [0.0|2550.0] "rpm"  DATC,IBOX,TCU
 SG_ CF_Ems_UpTarGr : 48|1@1+ (1.0,0.0) [0.0|1.0] ""  CLU,IBOX
 SG_ CF_Ems_DownTarGr : 49|1@1+ (1.0,0.0) [0.0|1.0] ""  CLU,IBOX
 SG_ CF_Ems_DesCurGr : 50|4@1+ (1.0,0.0) [0.0|15.0] ""  CLU,IBOX
 SG_ CF_Ems_SldAct : 54|1@1+ (1.0,0.0) [0.0|1.0] ""  CLU,IBOX
 SG_ CF_Ems_SldPosAct : 55|1@1+ (1.0,0.0) [0.0|1.0] ""  CLU,IBOX
 SG_ CF_Ems_HPresStat : 56|1@1+ (1.0,0.0) [0.0|1.0] ""  IBOX,TCU
 SG_ CF_Ems_IsgBuz : 57|1@1+ (1.0,0.0) [0.0|1.0] ""  CLU,IBOX
 SG_ CF_Ems_IdlStpFCO : 58|1@1+ (1.0,0.0) [0.0|1.0] ""  CLU,IBOX
 SG_ CF_Ems_FCopen : 59|1@1+ (1.0,0.0) [0.0|1.0] ""  CLU,IBOX
 SG_ CF_Ems_ActEcoAct : 60|1@1+ (1.0,0.0) [0.0|1.0] ""  CLU,IBOX,TCU
 SG_ CF_Ems_EngRunNorm : 61|1@1+ (1.0,0.0) [0.0|1.0] ""  ABS,ESC,IBOX,TCU
 SG_ CF_Ems_IsgStat2 : 62|2@1+ (2.0,0.0) [0.0|3.0] ""  CLU,IBOX,TCU

BO_ 640 EMS13: 8 EMS
 SG_ LV_FUEL_TYPE_ECU : 0|1@1+ (1.0,0.0) [0.0|1.0] ""  BCM,CLU,LPI,SMK
 SG_ LV_BFS_CFIRM : 1|1@1+ (1.0,0.0) [0.0|1.0] ""  LPI
 SG_ LV_CRASH : 2|1@1+ (1.0,0.0) [0.0|1.0] ""  LPI
 SG_ LV_VB_OFF_ACT : 3|1@1+ (1.0,0.0) [0.0|1.0] ""  LPI
 SG_ LV_GSL_MAP M : 4|1@1+ (1.0,0.0) [0.0|1.0] ""  LPI
 SG_ LV_ENG_TURN : 5|1@1+ (1.0,0.0) [0.0|1.0] ""  LPI
 SG_ ERR_FUEL : 8|8@1+ (1.0,0.0) [0.0|255.0] ""  LPI
 SG_ EOS : 16|8@1+ (1.0,0.0) [0.0|255.0] ""  LPI
 SG_ TCO : 24|8@1+ (0.75,-48.0) [-48.0|143.25] "deg"  LPI
 SG_ N_32 : 32|8@1+ (32.0,0.0) [0.0|8160.0] "rpm"  LPI
 SG_ MAF : 40|8@1+ (5.447,0.0) [0.0|1388.985] "mg/TDC"  LPI
 SG_ TIA : 48|8@1+ (0.75,-48.0) [-48.0|143.25] "deg"  LPI
 SG_ MAP m1 : 56|8@1+ (0.47058,0.0) [0.0|119.9979] "kPa"  LPI
 SG_ AMP m0 : 56|8@1+ (21.22,0.0) [0.0|5411.1] "hPa"  LPI

BO_ 688 SAS11: 5 MDPS
 SG_ SAS_Angle : 0|16@1- (0.1,0.0) [-3276.8|3276.7] "Deg"  _4WD,ACU,AFLS,AVM,CLU,ECS,EMS,ESC,IBOX,LCA,LDWS_LKAS,PGS,PSB,SCC,SPAS,TCU,_4WD,ACU,AFLS,AVM,BCM,CLU,ECS,EMS,ESC,IBOX,LCA,LDWS_LKAS,PGS,PSB,SCC,SPAS,TCU
 SG_ SAS_Speed : 16|8@1+ (4.0,0.0) [0.0|1016.0] ""  AFLS,ECS,ESC,IBOX,LDWS_LKAS,SCC,SPAS,TCU,AFLS,ECS,ESC,IBOX,LDWS_LKAS,SCC,SPAS,TCU
 SG_ SAS_Stat : 24|8@1+ (1.0,0.0) [0.0|255.0] ""  ECS,ESC,IBOX,LDWS_LKAS,PSB,SCC,SPAS,TCU,ECS,ESC,IBOX,LDWS_LKAS,PSB,SCC,SPAS,TCU
 SG_ MsgCount : 32|4@1+ (1.0,0.0) [0.0|15.0] ""  ECS,ESC,IBOX,LDWS_LKAS,PSB,SCC,SPAS,ECS,ESC,IBOX,LDWS_LKAS,PSB,SCC,SPAS
 SG_ CheckSum : 36|4@1+ (1.0,0.0) [0.0|15.0] ""  ECS,EMS,ESC,IBOX,LDWS_LKAS,PSB,SCC,SPAS,ECS,EMS,ESC,IBOX,LDWS_LKAS,PSB,SCC,SPAS

BO_ 896 DI_BOX13: 8 DI_BOX
 SG_ CF_DiBox_HPreInjVConfStat : 0|8@1+ (1.0,0.0) [0.0|255.0] ""  EMS
 SG_ CF_DiBox_HPreInjVStat1 : 8|8@1+ (1.0,0.0) [0.0|255.0] ""  EMS
 SG_ CF_DiBox_HPreInjVStat2 : 16|8@1+ (1.0,0.0) [0.0|255.0] ""  EMS
 SG_ CF_DiBox_HPreInjVPkp : 24|8@1+ (1.0,0.0) [0.0|255.0] ""  EMS
 SG_ CF_DiBox_HPreInjVBpt : 32|8@1+ (1.0,0.0) [0.0|255.0] ""  EMS
 SG_ CF_DiBox_ErrRegFrtMSV : 40|8@1+ (1.0,0.0) [0.0|255.0] ""  EMS
 SG_ CF_DiBox_ErrRegSedMSV : 48|8@1+ (1.0,0.0) [0.0|255.0] ""  EMS
 SG_ CF_DiBox_SPIErrSedMSV : 56|1@1+ (1.0,0.0) [0.0|1.0] ""  EMS
 SG_ CF_DiBox_SPIErrFrtMSV : 57|1@1+ (1.0,0.0) [0.0|1.0] ""  EMS
 SG_ CF_DiBox_IDErrSedMSV : 58|1@1+ (1.0,0.0) [0.0|1.0] ""  EMS
 SG_ CF_DiBox_IDErrFrtMSV : 59|1@1+ (1.0,0.0) [0.0|1.0] ""  EMS
 SG_ CF_DiBox_IniStatMSV : 60|1@1+ (1.0,0.0) [0.0|1.0] ""  EMS

BO_ 897 MDPS11: 8 MDPS
 SG_ CF_Mdps_WLmp : 0|2@1+ (1.0,0.0) [0.0|3.0] ""  CLU,CUBIS,EMS,IBOX,SPAS
 SG_ CF_Mdps_Flex : 2|3@1+ (1.0,0.0) [0.0|3.0] ""  CLU,LDWS_LKAS
 SG_ CF_Mdps_FlexDisp : 5|1@1+ (1.0,0.0) [0.0|1.0] ""  CLU
 SG_ CF_Mdps_Stat : 7|4@1+ (1.0,0.0) [0.0|15.0] ""  SPAS
 SG_ CR_Mdps_DrvTq : 11|12@1+ (1.0,-2048.0) [-2048.0|2046.0] ""  SPAS
 SG_ CF_Mdps_ALTRequest : 23|1@1+ (1.0,0.0) [0.0|1.0] ""  EMS
 SG_ CR_Mdps_StrAng : 24|16@1- (0.1,0.0) [-3276.8|3276.7] "Deg"  SPAS
 SG_ CF_Mdps_AliveCnt : 40|8@1+ (1.0,0.0) [0.0|255.0] ""  LDWS_LKAS,SPAS
 SG_ CF_Mdps_Chksum : 48|8@1+ (1.0,0.0) [0.0|255.0] ""  LDWS_LKAS,SPAS
 SG_ CF_Mdps_SPAS_FUNC : 57|1@1+ (1.0,0.0) [0.0|1.0] "flag"  SPAS
 SG_ CF_Mdps_LKAS_FUNC : 58|1@1+ (1.0,0.0) [0.0|1.0] "flag"  LDWS_LKAS
 SG_ CF_Mdps_CurrMode : 59|2@1+ (1.0,0.0) [0.0|3.0] ""  LDWS_LKAS
 SG_ CF_Mdps_Type : 61|2@1+ (1.0,0.0) [0.0|2.0] ""  LDWS_LKAS,SPAS
 SG_ CF_MDPS_VSM_FUNC : 56|1@0+ (1.0,0.0) [0.0|1.0] "" XXX

BO_ 899 FATC11: 8 DATC
 SG_ CR_Fatc_TqAcnOut : 0|8@1+ (0.2,0.0) [0.0|50.8] "Nm"  EMS,IBOX
 SG_ CF_Fatc_AcnRqSwi : 8|1@1+ (1.0,0.0) [0.0|1.0] ""  AAF,EMS,IBOX
 SG_ CF_Fatc_AcnCltEnRq : 9|1@1+ (1.0,0.0) [0.0|1.0] ""  EMS,IBOX
 SG_ CF_Fatc_EcvFlt : 10|1@1+ (1.0,0.0) [0.0|1.0] ""  EMS,IBOX
 SG_ CF_Fatc_BlwrOn : 11|1@1+ (1.0,0.0) [0.0|1.0] ""  EMS,IBOX
 SG_ CF_FATC_Iden : 12|2@1+ (1.0,0.0) [0.0|3.0] ""  EMS,IBOX
 SG_ CF_Fatc_BlwrMax : 14|1@1+ (1.0,0.0) [0.0|1.0] ""  CLU,EMS,IBOX
 SG_ CF_Fatc_EngStartReq : 15|1@1+ (1.0,0.0) [0.0|1.0] ""  EMS,IBOX
 SG_ CF_Fatc_IsgStopReq : 16|1@1+ (1.0,0.0) [0.0|1.0] ""  EMS,IBOX
 SG_ CF_Fatc_CtrInf : 17|3@1+ (1.0,0.0) [0.0|7.0] ""  EMS,IBOX
 SG_ CF_Fatc_MsgCnt : 20|4@1+ (1.0,0.0) [0.0|15.0] ""  EMS,IBOX
 SG_ CR_Fatc_OutTemp : 24|8@1+ (0.5,-40.0) [-40.0|60.0] "deg"  BCM,CLU,EMS,IBOX,SPAS,TCU,TPMS
 SG_ CR_Fatc_OutTempSns : 32|8@1+ (0.5,-40.0) [-40.0|60.0] "deg"  AAF,AHLS,CLU,EMS,IBOX,SPAS,TCU
 SG_ CF_Fatc_Compload : 40|3@1+ (1.0,0.0) [0.0|7.0] ""  EMS,IBOX
 SG_ CF_Fatc_ActiveEco : 43|1@1+ (1.0,0.0) [0.0|1.0] ""  CLU,IBOX
 SG_ CF_Fatc_AutoActivation : 44|1@1+ (1.0,0.0) [0.0|1.0] ""  IBOX
 SG_ CF_Fatc_DefSw : 45|1@1+ (1.0,0.0) [0.0|1.0] ""  BCM,IBOX
 SG_ CF_Fatc_PtcRlyStat : 46|1@1+ (1.0,0.0) [0.0|1.0] ""  EMS,IBOX
 SG_ CF_Fatc_ChkSum : 56|8@1+ (1.0,0.0) [0.0|255.0] ""  EMS,IBOX,SPAS

BO_ 900 EMS17: 8 EMS
 SG_ CF_Ems_PkpCurMSV : 0|8@1+ (1.0,0.0) [0.0|255.0] ""  DI_BOX
 SG_ CF_Ems_HolCurMSV : 8|8@1+ (1.0,0.0) [0.0|255.0] ""  DI_BOX
 SG_ CF_Ems_InjVBnkAct : 16|8@1+ (1.0,0.0) [0.0|255.0] ""  DI_BOX
 SG_ CF_Ems_InjVActSet : 24|8@1+ (1.0,0.0) [0.0|255.0] ""  DI_BOX
 SG_ CF_Ems_DiagFulHDEV : 32|1@1+ (1.0,0.0) [0.0|1.0] ""  DI_BOX
 SG_ CF_Ems_SwiOffIC1 : 33|1@1+ (1.0,0.0) [0.0|1.0] ""  DI_BOX
 SG_ CF_Ems_SwiOffIC2 : 34|1@1+ (1.0,0.0) [0.0|1.0] ""  DI_BOX
 SG_ CF_Ems_DiagReqHDEV : 38|1@1+ (1.0,0.0) [0.0|1.0] ""  DI_BOX
 SG_ CR_Ems_DutyCycMSV : 40|8@1+ (0.3921568627,0.0) [0.0|100.0] "%"  DI_BOX
 SG_ CR_Ems_BatVolRly : 48|8@1+ (0.1,0.0) [0.0|25.5] "V"  DI_BOX

BO_ 902 WHL_SPD11: 8 ABS
 SG_ WHL_SPD_FL : 0|14@1+ (0.03125,0.0) [0.0|511.96875] "km/h"  _4WD,AFLS,AHLS,AVM,CLU,CUBIS,ECS,EMS,EPB,IBOX,LDWS_LKAS,PGS,PSB,SCC,SMK,SPAS,TCU,TPMS,_4WD,ACU,AFLS,AHLS,AVM,CLU,ECS,EMS,EPB,IBOX,LCA,LDWS_LKAS,PGS,PSB,SCC,SMK,SPAS,TCU,TPMS
 SG_ WHL_SPD_FR : 16|14@1+ (0.03125,0.0) [0.0|511.96875] "km/h"  _4WD,ACU,AFLS,AHLS,AVM,CLU,CUBIS,ECS,EMS,EPB,IBOX,LDWS_LKAS,PGS,PSB,SCC,SMK,SPAS,TCU,TPMS,_4WD,ACU,AFLS,AHLS,AVM,CLU,ECS,EMS,EPB,IBOX,LCA,LDWS_LKAS,PGS,PSB,SCC,SMK,SPAS,TCU,TPMS
 SG_ WHL_SPD_RL : 32|14@1+ (0.03125,0.0) [0.0|511.96875] "km/h"  _4WD,AFLS,AHLS,AVM,BCM,CLU,CUBIS,ECS,EMS,EPB,IBOX,LDWS_LKAS,PGS,PSB,SCC,SMK,SPAS,TCU,TPMS,_4WD,ACU,AFLS,AHLS,AVM,BCM,CLU,ECS,EMS,EPB,IBOX,LCA,LDWS_LKAS,PGS,PSB,SCC,SMK,SPAS,TCU,TPMS
 SG_ WHL_SPD_RR : 48|14@1+ (0.03125,0.0) [0.0|511.96875] "km/h"  _4WD,AFLS,AHLS,AVM,CLU,CUBIS,ECS,EMS,EPB,IBOX,LDWS_LKAS,PGS,PSB,SCC,SMK,SPAS,TCU,TPMS,_4WD,ACU,AFLS,AHLS,AVM,CLU,ECS,EMS,EPB,IBOX,LCA,LDWS_LKAS,PGS,PSB,SCC,SMK,SPAS,TCU,TPMS
 SG_ WHL_SPD_AliveCounter_LSB : 14|2@1+ (1.0,0.0) [0.0|15.0] ""  _4WD,EMS,LPI,TCU,TMU
 SG_ WHL_SPD_AliveCounter_MSB : 30|2@1+ (1.0,0.0) [0.0|15.0] ""  _4WD,EMS,LPI,TCU,TMU
 SG_ WHL_SPD_Checksum_LSB : 46|2@1+ (1.0,0.0) [0.0|15.0] ""  _4WD,EMS,LPI,TCU,TMU
 SG_ WHL_SPD_Checksum_MSB : 62|2@1+ (1.0,0.0) [0.0|15.0] ""  _4WD,EMS,LPI,TCU,TMU

BO_ 903 WHL_PUL11: 6 ABS
 SG_ WHL_PUL_FL : 0|8@1+ (0.5,0.0) [0.0|127.5] "pulse count"  CUBIS,EPB,IBOX,SPAS,TMU,TPMS,CUBIS,EPB,IBOX,LDWS_LKAS,SPAS,TMU,TPMS
 SG_ WHL_PUL_FR : 8|8@1+ (0.5,0.0) [0.0|127.5] "pulse count"  CUBIS,EPB,IBOX,SPAS,TMU,TPMS,CUBIS,EPB,IBOX,LDWS_LKAS,SPAS,TMU,TPMS
 SG_ WHL_PUL_RL : 16|8@1+ (0.5,0.0) [0.0|127.5] "pulse count"  CUBIS,EPB,IBOX,SPAS,TMU,TPMS,CUBIS,EPB,IBOX,LDWS_LKAS,SPAS,TMU,TPMS
 SG_ WHL_PUL_RR : 24|8@1+ (0.5,0.0) [0.0|127.5] "pulse count"  CUBIS,EPB,IBOX,SPAS,TMU,TPMS,CUBIS,EPB,IBOX,LDWS_LKAS,SPAS,TMU,TPMS
 SG_ WHL_DIR_FL : 32|2@1+ (1.0,0.0) [0.0|3.0] ""  EPB,SPAS,TPMS,EPB,LCA,SPAS,TPMS
 SG_ WHL_DIR_FR : 34|2@1+ (1.0,0.0) [0.0|3.0] ""  EPB,SPAS,TPMS,EPB,LCA,SPAS,TPMS
 SG_ WHL_DIR_RL : 36|2@1+ (1.0,0.0) [0.0|3.0] ""  EPB,SPAS,TPMS,EPB,LCA,SPAS,TPMS
 SG_ WHL_DIR_RR : 38|2@1+ (1.0,0.0) [0.0|3.0] ""  EPB,SPAS,TPMS,EPB,LCA,SPAS,TPMS
 SG_ WHL_PUL_Chksum : 40|8@1+ (1.0,0.0) [0.0|255.0] ""  EPB,SPAS,TPMS,EPB,LCA,LDWS_LKAS,SPAS,TPMS

BO_ 906 ABS11: 8 ABS
 SG_ ABS_DEF : 0|1@1+ (1.0,0.0) [0.0|1.0] ""  _4WD,ACU,EMS,SPAS,TCU
 SG_ EBD_DEF : 1|1@1+ (1.0,0.0) [0.0|1.0] ""  _4WD,EMS,SPAS,TCU
 SG_ ABS_ACT : 2|1@1+ (1.0,0.0) [0.0|1.0] ""  _4WD,ACU,EPB,SPAS,TCU
 SG_ ABS_W_LAMP : 3|1@1+ (1.0,0.0) [0.0|1.0] ""  _4WD,CLU,CUBIS,MTS,TMU
 SG_ EBD_W_LAMP : 4|1@1+ (1.0,0.0) [0.0|1.0] ""  _4WD,CLU
 SG_ ABS_DIAG : 5|1@1+ (1.0,0.0) [0.0|1.0] ""  _4WD,CLU
 SG_ ESS_STAT : 6|2@1+ (1.0,0.0) [0.0|3.0] ""  _4WD,BCM,CLU,EMS

BO_ 912 SPAS11: 7 SPAS
 SG_ CF_Spas_Stat : 0|4@1+ (1.0,0.0) [0.0|15.0] ""  ESC,MDPS
 SG_ CF_Spas_TestMode : 4|2@1+ (1.0,0.0) [0.0|3.0] ""  MDPS
 SG_ CR_Spas_StrAngCmd : 8|16@1- (0.1,0.0) [-3276.8|3276.7] ""  MDPS
 SG_ CF_Spas_BeepAlarm : 24|4@1+ (1.0,0.0) [0.0|15.0] ""  CLU
 SG_ CF_Spas_Mode_Seq : 28|2@1+ (1.0,0.0) [0.0|3.0] ""  CLU
 SG_ CF_Spas_AliveCnt : 32|8@1+ (1.0,0.0) [0.0|255.0] ""  MDPS
 SG_ CF_Spas_Chksum : 40|8@1+ (1.0,0.0) [0.0|255.0] ""  MDPS
 SG_ CF_Spas_PasVol : 48|3@1+ (1.0,0.0) [0.0|7.0] ""  CGW,CLU

BO_ 915 TCS12: 4 ESC
 SG_ SA_COUNT : 0|16@1+ (2.0,-32768.0) [-32768.0|98302.0] ""  _4WD,ACU,MDPS
 SG_ SA_Z_COUNT : 16|15@1+ (2.0,-32768.0) [-32768.0|32766.0] ""  _4WD,ACU,MDPS
 SG_ SA_Z_FLAG : 31|1@1+ (1.0,0.0) [0.0|1.0] ""  _4WD,ACU,MDPS

BO_ 916 TCS13: 8 ESC
 SG_ aBasis : 0|11@1+ (0.01,-10.23) [-10.23|10.24] "m/s^2"  EMS,SCC
 SG_ BrakeLight : 11|1@1+ (1.0,0.0) [0.0|1.0] ""  CLU,EMS,SCC
 SG_ DCEnable : 12|1@1+ (1.0,0.0) [0.0|1.0] ""  EMS,SCC
 SG_ AliveCounterTCS : 13|3@1+ (1.0,0.0) [0.0|7.0] ""  EMS,SCC
 SG_ Pre_TCS_CTL : 16|1@1+ (1.0,0.0) [0.0|1.0] ""  Vector__XXX
 SG_ EBA_ACK : 17|1@1+ (1.0,0.0) [0.0|1.0] ""  Vector__XXX
 SG_ FCA_ACK : 18|1@1+ (1.0,0.0) [0.0|1.0] ""  Vector__XXX
 SG_ DF_BF_STAT : 19|2@1+ (1.0,0.0) [0.0|3.0] ""  BCW
 SG_ SCCReqLim : 22|2@1+ (1.0,0.0) [0.0|3.0] ""  SCC
 SG_ TQI_SCC : 24|8@1+ (0.390625,0.0) [0.0|199.609375] "%"  Vector__XXX
 SG_ ACCEL_REF_ACC : 32|11@1+ (0.01,-10.23) [-10.23|10.24] "m/s^2"  EMS,SCC
 SG_ ACCEnable : 43|2@1+ (1.0,0.0) [0.0|3.0] ""  EMS,SCC
 SG_ DriverOverride : 45|2@1+ (1.0,0.0) [0.0|3.0] ""  EMS,SCC
 SG_ StandStill : 47|1@1+ (1.0,0.0) [0.0|1.0] ""  EMS,SCC
 SG_ CheckSum_TCS3 : 48|4@1+ (1.0,0.0) [0.0|15.0] ""  EMS,SCC
 SG_ ACC_EQUIP : 52|1@1+ (1.0,0.0) [0.0|1.0] ""  EMS,SCC
 SG_ PBRAKE_ACT : 53|1@1+ (1.0,0.0) [0.0|1.0] ""  EMS,SCC
 SG_ ACC_REQ : 54|1@1+ (1.0,0.0) [0.0|1.0] ""  EMS
 SG_ DriverBraking : 55|1@1+ (1.0,0.0) [0.0|1.0] ""  EMS,SCC
 SG_ CF_VSM_Coded : 56|1@1+ (1.0,0.0) [0.0|1.0] ""  SCC
 SG_ CF_VSM_Avail : 57|2@1+ (1.0,0.0) [0.0|3.0] ""  CLU,SCC
 SG_ CF_VSM_Handshake : 59|1@1+ (1.0,0.0) [0.0|1.0] ""  SCC
 SG_ CF_DriBkeStat : 60|1@1+ (1.0,0.0) [0.0|1.0] ""  SCC
 SG_ CF_VSM_ConfSwi : 61|2@1+ (1.0,0.0) [0.0|3.0] ""  SCC
 SG_ AEB_EQUIP : 63|1@1+ (1.0,0.0) [0.0|1.0] ""  SCC

BO_ 1017 ECS12: 4 ECS
 SG_ Height_FL : 0|8@1+ (1.0,-128.0) [-128.0|127.0] "mm"  AFLS
 SG_ Height_FR : 8|8@1+ (1.0,-128.0) [-128.0|127.0] "mm"  AFLS
 SG_ Height_RL : 16|8@1+ (1.0,-128.0) [-128.0|127.0] "mm"  AFLS
 SG_ Height_RR : 24|8@1+ (1.0,-128.0) [-128.0|127.0] "mm"  AFLS

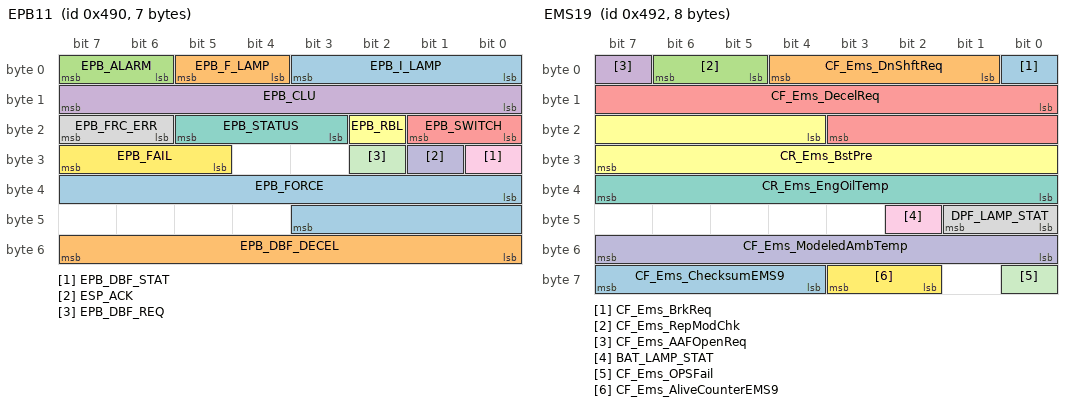
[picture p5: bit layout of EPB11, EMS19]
BO_ 1168 EPB11: 7 EPB
 SG_ EPB_I_LAMP : 0|4@1+ (1.0,0.0) [0.0|15.0] ""  BCM,CLU,CUBIS,ESC,IBOX
 SG_ EPB_F_LAMP : 4|2@1+ (1.0,0.0) [0.0|3.0] ""  CLU,CUBIS,ESC,IBOX
 SG_ EPB_ALARM : 6|2@1+ (1.0,0.0) [0.0|3.0] ""  CLU,ESC
 SG_ EPB_CLU : 8|8@1+ (1.0,0.0) [0.0|255.0] ""  CLU,ESC
 SG_ EPB_SWITCH : 16|2@1+ (1.0,0.0) [0.0|3.0] ""  ESC,SCC
 SG_ EPB_RBL : 18|1@1+ (1.0,0.0) [0.0|1.0] ""  EMS,ESC
 SG_ EPB_STATUS : 19|3@1+ (1.0,0.0) [0.0|7.0] ""  CLU,EMS,ESC,SCC,TCU
 SG_ EPB_FRC_ERR : 22|2@1+ (1.0,0.0) [0.0|3.0] ""  EMS,ESC,SCC,TCU
 SG_ EPB_DBF_STAT : 24|1@1+ (1.0,0.0) [0.0|1.0] ""  ESC
 SG_ ESP_ACK : 25|1@1+ (1.0,0.0) [0.0|1.0] ""  ESC
 SG_ EPB_DBF_REQ : 26|1@1+ (1.0,0.0) [0.0|1.0] ""  ESC
 SG_ EPB_FAIL : 29|3@1+ (1.0,0.0) [0.0|7.0] ""  ESC,SCC
 SG_ EPB_FORCE : 32|12@1+ (1.0,-1000.0) [-1000.0|3000.0] ""  ESC
 SG_ EPB_DBF_DECEL : 48|8@1+ (0.01,0.0) [0.0|2.54] "g"  ESC

BO_ 1170 EMS19: 8 EMS
 SG_ CF_Ems_BrkReq : 0|1@1+ (1.0,0.0) [0.0|1.0] ""  ESC,IBOX,TCU
 SG_ CF_Ems_DnShftReq : 1|4@1+ (1.0,0.0) [0.0|14.0] ""  IBOX,TCU
 SG_ CF_Ems_RepModChk : 5|2@1+ (1.0,0.0) [0.0|3.0] ""  IBOX
 SG_ CF_Ems_AAFOpenReq : 7|1@1+ (1.0,0.0) [0.0|1.0] ""  AAF,IBOX
 SG_ CF_Ems_DecelReq : 8|12@1+ (0.0010,-4.094) [-4.094|0.0] "m/s^2"  ESC,IBOX,TCU
 SG_ CR_Ems_BstPre : 20|12@1+ (1.322,0.0) [0.0|4094.0] "hPa"  CLU,IBOX
 SG_ CR_Ems_EngOilTemp : 32|8@1+ (0.75,-40.0) [0.0|254.0] "deg"  CLU,IBOX
 SG_ DPF_LAMP_STAT : 40|2@1+ (1.0,0.0) [0.0|3.0] ""  CLU,IBOX
 SG_ BAT_LAMP_STAT : 42|1@1+ (1.0,0.0) [0.0|1.0] ""  CLU,IBOX
 SG_ CF_Ems_ModeledAmbTemp : 48|8@1+ (0.5,-41.0) [-41.0|85.5] "deg"  AAF,IBOX
 SG_ CF_Ems_OPSFail : 56|1@1+ (1.0,0.0) [0.0|1.0] ""  CLU,IBOX
 SG_ CF_Ems_AliveCounterEMS9 : 58|2@1+ (1.0,0.0) [0.0|3.0] ""  AAF,ABS,CUBIS,ECS,EPB,IBOX,MDPS,REA,SCC,SMK,TCU
 SG_ CF_Ems_ChecksumEMS9 : 60|4@1+ (1.0,0.0) [0.0|15.0] ""  AAF,ABS,CUBIS,ECS,EPB,IBOX,MDPS,REA,SCC,SMK,TCU

BO_ 1260 Sign_Detection: 8 XXX
 SG_ SpeedLim_Nav_Cam : 40|8@1+ (1,0) [0|255] "km/h / mph" XXX
 SG_ SpeedLim_Nav_Cam2 : 48|8@1+ (1,0) [0|255] "km/h / mph" XXX

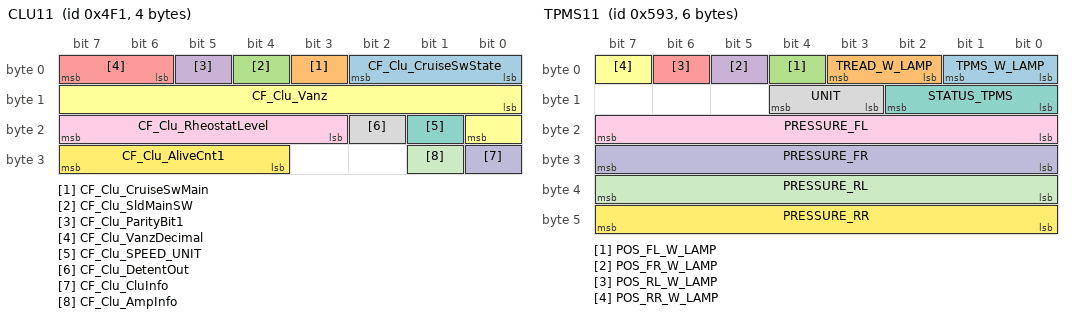
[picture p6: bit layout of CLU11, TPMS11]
BO_ 1265 CLU11: 4 CLU
 SG_ CF_Clu_CruiseSwState : 0|3@1+ (1.0,0.0) [0.0|7.0] ""  EMS,LDWS_LKAS,SCC
 SG_ CF_Clu_CruiseSwMain : 3|1@1+ (1.0,0.0) [0.0|1.0] ""  EMS,LDWS_LKAS,SCC
 SG_ CF_Clu_SldMainSW : 4|1@1+ (1.0,0.0) [0.0|1.0] ""  EMS
 SG_ CF_Clu_ParityBit1 : 5|1@1+ (1.0,0.0) [0.0|1.0] "pulse count"  EMS
 SG_ CF_Clu_VanzDecimal : 6|2@1+ (0.125,0.0) [0.0|0.375] ""  EMS
 SG_ CF_Clu_Vanz : 8|9@1+ (0.5,0.0) [0.0|255.5] "km/h or MPH"  BCM,CUBIS,EMS,IBOX,LDWS_LKAS,MDPS,SCC
 SG_ CF_Clu_SPEED_UNIT : 17|1@1+ (1.0,0.0) [0.0|1.0] ""  BCM,CUBIS,EMS,IBOX,LDWS_LKAS,MDPS,SCC
 SG_ CF_Clu_DetentOut : 18|1@1+ (1.0,0.0) [0.0|1.0] ""  AVM,BCM,LCA,PGS,SPAS
 SG_ CF_Clu_RheostatLevel : 19|5@1+ (1.0,0.0) [0.0|31.0] ""  AVM,BCM,LCA,PGS,SPAS
 SG_ CF_Clu_CluInfo : 24|1@1+ (1.0,0.0) [0.0|1.0] ""  BCM
 SG_ CF_Clu_AmpInfo : 25|1@1+ (1.0,0.0) [0.0|1.0] ""  BCM
 SG_ CF_Clu_AliveCnt1 : 28|4@1+ (1.0,0.0) [0.0|15.0] ""  AHLS,EMS,EPB,LDWS_LKAS,MDPS,SCC

BO_ 1268 SPAS12: 8 SPAS
 SG_ CF_Spas_HMI_Stat : 0|8@1+ (1.0,0.0) [0.0|255.0] ""  CLU
 SG_ CF_Spas_Disp : 8|2@1+ (1.0,0.0) [0.0|3.0] ""  CLU,EMS
 SG_ CF_Spas_FIL_Ind : 10|3@1+ (1.0,0.0) [0.0|7.0] ""  AVM,CLU
 SG_ CF_Spas_FIR_Ind : 13|3@1+ (1.0,0.0) [0.0|7.0] ""  AVM,CLU
 SG_ CF_Spas_FOL_Ind : 16|3@1+ (1.0,0.0) [0.0|7.0] ""  AVM,CLU
 SG_ CF_Spas_FOR_Ind : 19|3@1+ (1.0,0.0) [0.0|7.0] ""  AVM,CLU
 SG_ CF_Spas_VolDown : 22|2@1+ (1.0,0.0) [0.0|3.0] ""  CLU
 SG_ CF_Spas_RIL_Ind : 24|3@1+ (1.0,0.0) [0.0|7.0] ""  AVM,CLU
 SG_ CF_Spas_RIR_Ind : 27|3@1+ (1.0,0.0) [0.0|7.0] ""  AVM,CLU
 SG_ CF_Spas_FLS_Alarm : 30|2@1+ (1.0,0.0) [0.0|3.0] ""  CLU
 SG_ CF_Spas_ROL_Ind : 32|3@1+ (1.0,0.0) [0.0|7.0] ""  AVM,CLU
 SG_ CF_Spas_ROR_Ind : 35|3@1+ (1.0,0.0) [0.0|7.0] ""  AVM,CLU
 SG_ CF_Spas_FCS_Alarm : 38|2@1+ (1.0,0.0) [0.0|3.0] ""  CLU
 SG_ CF_Spas_FI_Ind : 40|3@1+ (1.0,0.0) [0.0|7.0] ""  AVM,CLU
 SG_ CF_Spas_RI_Ind : 43|3@1+ (1.0,0.0) [0.0|7.0] ""  AVM,CLU
 SG_ CF_Spas_FRS_Alarm : 46|2@1+ (1.0,0.0) [0.0|3.0] ""  CLU
 SG_ CF_Spas_FR_Alarm : 48|2@1+ (1.0,0.0) [0.0|3.0] ""  BCM,CLU
 SG_ CF_Spas_RR_Alarm : 50|2@1+ (1.0,0.0) [0.0|3.0] ""  BCM,CLU
 SG_ CF_Spas_BEEP_Alarm : 52|4@1+ (1.0,0.0) [0.0|15.0] ""  BCM,CLU
 SG_ CF_Spas_StatAlarm : 56|1@1+ (1.0,0.0) [0.0|1.0] ""  CLU
 SG_ CF_Spas_RLS_Alarm : 57|2@1+ (1.0,0.0) [0.0|3.0] ""  CLU
 SG_ CF_Spas_RCS_Alarm : 59|2@1+ (1.0,0.0) [0.0|3.0] ""  CLU
 SG_ CF_Spas_RRS_Alarm : 61|2@1+ (1.0,0.0) [0.0|3.0] ""  CLU

BO_ 1407 HU_MON_PE_01: 8 CLU
 SG_ HU_Type : 0|8@1+ (1.0,0.0) [0.0|255.0] ""  AVM,PGS

BO_ 1411 CUBIS11: 8 CUBIS
 SG_ CF_Cubis_HUDisp : 0|4@1+ (1.0,0.0) [0.0|15.0] ""  CLU

BO_ 1412 AAF11: 8 AAF
 SG_ CF_Aaf_ActFlapStatus : 0|2@1+ (1.0,0.0) [0.0|3.0] ""  AAF_Tester
 SG_ CF_Aaf_ModeStatus : 2|3@1+ (1.0,0.0) [0.0|7.0] ""  AAF_Tester
 SG_ CF_Aaf_WrnLamp : 5|1@1+ (1.0,0.0) [0.0|1.0] ""  CLU
 SG_ CF_Aaf_ErrStatus : 6|10@1+ (1.0,0.0) [0.0|1023.0] ""  AAF_Tester,EMS
 SG_ CF_Aaf_OpenRqSysAct : 16|8@1+ (1.0,0.0) [0.0|255.0] ""  AAF_Tester
 SG_ CF_Aaf_PStatus : 24|8@1+ (1.0,0.0) [0.0|100.0] "%"  AAF_Tester
 SG_ CF_Aaf_OpenRqSysSol : 32|8@1+ (1.0,0.0) [0.0|255.0] ""  AAF_Tester
 SG_ CF_Aaf_SolFlapStatus : 40|2@1+ (1.0,0.0) [0.0|3.0] ""  AAF_Tester
 SG_ CF_Aaf_MilOnReq : 42|1@1+ (1.0,0.0) [0.0|1.0] ""  EMS

BO_ 1414 EVP11: 3 EVP
 SG_ CF_Evp_Stat : 0|1@1+ (1.0,0.0) [0.0|1.0] ""  CLU

BO_ 1415 TMU11: 8 IBOX
 SG_ CF_Tmu_VehSld : 0|1@1+ (1.0,0.0) [0.0|1.0] ""  EMS
 SG_ CF_Tmu_VehImmo : 1|1@1+ (1.0,0.0) [0.0|1.0] ""  EMS
 SG_ CF_Tmu_ReqRepCnd : 2|2@1+ (1.0,0.0) [0.0|3.0] ""  EMS
 SG_ CF_Tmu_AirconCtr : 4|1@1+ (1.0,0.0) [0.0|1.0] ""  DATC
 SG_ CF_Tmu_TempMd : 5|1@1+ (1.0,0.0) [0.0|1.0] ""  DATC
 SG_ CF_Tmu_TempSet : 6|16@1+ (1.0,0.0) [0.0|20.0] ""  DATC
 SG_ CF_Tmu_DefrostCtr : 22|1@1+ (1.0,0.0) [0.0|1.0] ""  DATC,FATC
 SG_ CF_Tmu_AliveCnt1 : 56|4@1+ (1.0,0.0) [0.0|15.0] ""  EMS

BO_ 1419 LCA11: 8 LCA
 SG_ CF_Lca_Stat : 0|4@1+ (1.0,0.0) [0.0|15.0] ""  BCM,CLU
 SG_ CF_Rcta_Stat : 4|4@1+ (1.0,0.0) [0.0|15.0] ""  BCM,CLU
 SG_ CF_Lca_IndLeft : 8|2@1+ (1.0,0.0) [0.0|3.0] ""  BCM,CLU
 SG_ CF_Rcw_Stat : 10|4@1+ (1.0,0.0) [0.0|15.0] ""  BCM,CLU
 SG_ CF_RCW_Warning : 14|2@1+ (1.0,0.0) [0.0|3.0] ""  BCM,CLU
 SG_ CF_Lca_IndRight : 16|2@1+ (1.0,0.0) [0.0|3.0] ""  BCM,CLU
 SG_ CF_Lca_SndWan_Stat : 18|2@1+ (1.0,0.0) [0.0|3.0] ""  BCM,CLU
 SG_ CF_FR_SndWan : 20|1@1+ (1.0,0.0) [0.0|1.0] ""  BCM,CLU
 SG_ CF_FL_SndWan : 21|1@1+ (1.0,0.0) [0.0|1.0] ""  BCM,CLU
 SG_ CF_RR_SndWan : 22|1@1+ (1.0,0.0) [0.0|1.0] ""  BCM,CLU
 SG_ CF_RL_SndWan : 23|1@1+ (1.0,0.0) [0.0|1.0] ""  BCM,CLU
 SG_ CF_Lca_IndBriLeft : 24|8@1+ (1.0,0.0) [0.0|255.0] ""  BCM,CLU
 SG_ CF_Lca_IndBriRight : 32|8@1+ (1.0,0.0) [0.0|255.0] ""  BCM,CLU
 SG_ CF_RCTA_IndBriLeft : 40|8@1+ (1.0,0.0) [0.0|255.0] ""  BCM,CLU
 SG_ CF_RCTA_IndBriRight : 48|8@1+ (1.0,0.0) [0.0|255.0] ""  BCM,CLU
 SG_ CF_RCTA_IndLeft : 56|2@1+ (1.0,0.0) [0.0|3.0] ""  BCM,CLU
 SG_ CF_RCTA_IndRight : 58|2@1+ (1.0,0.0) [0.0|3.0] ""  BCM,CLU
 SG_ CF_SndWarnForClu : 60|1@1+ (1.0,0.0) [0.0|1.0] ""  CLU

BO_ 1425 AFLS11: 2 AFLS
 SG_ AFLS_STAT : 1|2@1+ (1.0,0.0) [0.0|3.0] ""  CLU
 SG_ CF_Afls_TrfChgStat : 3|1@1+ (1.0,0.0) [0.0|1.0] ""  CLU
 SG_ CF_Afls_LedHLStat : 4|2@1+ (1.0,0.0) [0.0|3.0] ""  CLU

BO_ 1427 TPMS11: 6 BCM
 SG_ TPMS_W_LAMP : 0|2@1+ (1.0,0.0) [0.0|3.0] ""  CLU,CUBIS,HUD,IBOX,CLU,CUBIS,HUD,IBOX
 SG_ TREAD_W_LAMP : 2|2@1+ (1.0,0.0) [0.0|3.0] ""  CLU,CUBIS,HUD,IBOX,CLU,CUBIS,HUD,IBOX
 SG_ POS_FL_W_LAMP : 4|1@1+ (1.0,0.0) [0.0|1.0] ""  CLU,CUBIS,HUD,IBOX
 SG_ POS_FR_W_LAMP : 5|1@1+ (1.0,0.0) [0.0|1.0] ""  CLU,CUBIS,HUD,IBOX
 SG_ POS_RL_W_LAMP : 6|1@1+ (1.0,0.0) [0.0|1.0] ""  CLU,CUBIS,HUD,IBOX
 SG_ POS_RR_W_LAMP : 7|1@1+ (1.0,0.0) [0.0|1.0] ""  CLU,CUBIS,HUD,IBOX
 SG_ STATUS_TPMS : 8|3@1+ (1.0,0.0) [0.0|0.0] ""  CLU
 SG_ UNIT : 11|2@1+ (1.0,0.0) [0.0|3.0] ""  CLU
 SG_ PRESSURE_FL : 16|8@1+ (1.0,0.0) [0.0|255.0] ""  CLU
 SG_ PRESSURE_FR : 24|8@1+ (1.0,0.0) [0.0|255.0] ""  CLU
 SG_ PRESSURE_RL : 32|8@1+ (1.0,0.0) [0.0|255.0] ""  CLU
 SG_ PRESSURE_RR : 40|8@1+ (1.0,0.0) [0.0|255.0] ""  CLU

BO_ 1434 PSB11: 2 PSB
 SG_ PSB_LH_FAIL : 0|2@1+ (1.0,0.0) [0.0|3.0] ""  CLU
 SG_ PSB_LH_TGL : 2|1@1+ (1.0,0.0) [0.0|1.0] ""  CLU
 SG_ PSB_LH_ACT : 3|4@1+ (1.0,0.0) [0.0|4.0] ""  Dummy
 SG_ PSB_RH_FAIL : 8|2@1+ (1.0,0.0) [0.0|3.0] ""  CLU
 SG_ PSB_RH_TGL : 10|1@1+ (1.0,0.0) [0.0|1.0] ""  CLU
 SG_ PSB_RH_ACT : 11|4@1+ (1.0,0.0) [0.0|4.0] ""  Dummy

BO_ 1437 AHLS11: 8 AHLS
 SG_ CF_Ahls_WarnLamp : 0|2@1+ (1.0,0.0) [0.0|3.0] ""  CLU
 SG_ CF_Ahls_WarnMsg : 2|2@1+ (1.0,0.0) [0.0|3.0] ""  CLU

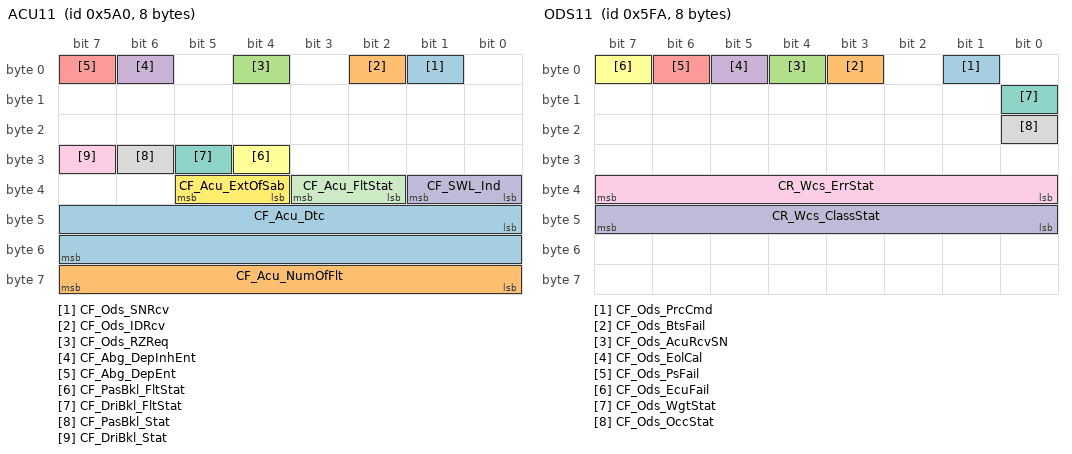
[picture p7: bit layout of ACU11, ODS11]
BO_ 1440 ACU11: 8 ACU
 SG_ CF_Ods_SNRcv : 1|1@1+ (1.0,0.0) [0.0|1.0] ""  ODS
 SG_ CF_Ods_IDRcv : 2|1@1+ (1.0,0.0) [0.0|1.0] ""  ODS
 SG_ CF_Ods_RZReq : 4|1@1+ (1.0,0.0) [0.0|1.0] ""  ODS
 SG_ CF_Abg_DepInhEnt : 6|1@1+ (1.0,0.0) [0.0|1.0] ""  ODS
 SG_ CF_Abg_DepEnt : 7|1@1+ (1.0,0.0) [0.0|1.0] ""  ODS
 SG_ CF_PasBkl_FltStat : 28|1@1+ (1.0,0.0) [0.0|1.0] ""  ODS,PSB
 SG_ CF_DriBkl_FltStat : 29|1@1+ (1.0,0.0) [0.0|1.0] ""  ODS,PSB
 SG_ CF_PasBkl_Stat : 30|1@1+ (1.0,0.0) [0.0|1.0] ""  IBOX,ODS,PSB,TMU
 SG_ CF_DriBkl_Stat : 31|1@1+ (1.0,0.0) [0.0|1.0] ""  ODS,PSB
 SG_ CF_SWL_Ind : 32|2@1+ (1.0,0.0) [0.0|3.0] ""  CUBIS,IBOX
 SG_ CF_Acu_FltStat : 34|2@1+ (1.0,0.0) [0.0|3.0] ""  CUBIS,IBOX
 SG_ CF_Acu_ExtOfSab : 36|2@1+ (1.0,0.0) [0.0|3.0] ""  BCM,CLU,CUBIS,IBOX
 SG_ CF_Acu_Dtc : 40|16@1+ (1.0,0.0) [0.0|65535.0] ""  CUBIS,IBOX
 SG_ CF_Acu_NumOfFlt : 56|8@1+ (1.0,0.0) [0.0|255.0] ""  CUBIS,IBOX

BO_ 1441 ACU12: 8 ACU
 SG_ CR_Acu_SN : 0|64@1+ (1.0,0.0) [0.0|0.0] ""  ODS

BO_ 1456 CLU12: 4 CLU
 SG_ CF_Clu_Odometer : 0|24@1+ (0.1,0.0) [0.0|1677721.4] "km"  _4WD,AAF,BCM,CUBIS,EMS,EPB,IBOX,LDWS_LKAS,SCC,TPMS

BO_ 1472 GW_Warning_PE: 8 BCM
 SG_ Audio_VolumeDown : 38|2@1+ (1.0,0.0) [0.0|3.0] ""  CLU
 SG_ Pas_Spkr_Flh_Alarm : 48|2@1+ (1.0,0.0) [0.0|3.0] ""  CLU
 SG_ Pas_Spkr_Fcnt_Alarm : 50|2@1+ (1.0,0.0) [0.0|3.0] ""  CLU
 SG_ Pas_Spkr_Frh_Alarm : 52|2@1+ (1.0,0.0) [0.0|3.0] ""  CLU
 SG_ Pas_Spkr_Rlh_Alarm : 56|2@1+ (1.0,0.0) [0.0|3.0] ""  CLU,PGS
 SG_ Pas_Spkr_Rcnt_Alarm : 58|2@1+ (1.0,0.0) [0.0|3.0] ""  CLU
 SG_ Pas_Spkr_Rrh_Alarm : 60|2@1+ (1.0,0.0) [0.0|3.0] ""  CLU,PGS

BO_ 1479 EMS21: 8 EMS
 SG_ SCR_LEVEL_WARN_LAMP : 0|1@1+ (1.0,0.0) [0.0|1.0] ""  CLU
 SG_ SCR_LEVEL_WARN : 1|3@1+ (1.0,0.0) [0.0|4.0] ""  CLU
 SG_ SCR_SYS_ERROR_WARN : 4|3@1+ (1.0,0.0) [0.0|7.0] ""  CLU
 SG_ SCR_SYSTEM_WARN_LAMP : 7|1@1+ (1.0,0.0) [0.0|1.0] ""  CLU
 SG_ SCR_INDUCEMENT_EXIT_COND : 8|2@1+ (1.0,0.0) [0.0|3.0] ""  CLU
 SG_ SCR_UREA_LEVEL : 16|8@1+ (0.5,0.0) [0.0|100.0] "%"  CLU
 SG_ SCR_NO_REMAINING_RESTARTS : 24|8@1+ (1.0,0.0) [0.0|255.0] ""  CLU
 SG_ SCR_REMAINING_DISTANCE : 32|16@1+ (1.0,0.0) [0.0|25000.0] "km"  CLU

BO_ 1490 HU_DATC_E_02: 8 CLU
 SG_ HU_DATC_RearOnOffSet : 6|2@1+ (1.0,0.0) [0.0|3.0] ""  DATC
 SG_ HU_DATC_ADSOnOffSet : 8|2@1+ (1.0,0.0) [0.0|3.0] ""  DATC

BO_ 1491 HU_DATC_PE_00: 8 CLU
 SG_ HU_VRActivity : 0|2@1+ (1.0,0.0) [0.0|3.0] ""  DATC
 SG_ HU_PhoneActivity : 2|2@1+ (1.0,0.0) [0.0|3.0] ""  DATC
 SG_ BlowerNoiseControl : 4|2@1+ (1.0,0.0) [0.0|3.0] ""  DATC

BO_ 1492 TMU_GW_PE_01: 8 CLU
 SG_ TMU_IVRActivity : 0|2@1+ (1.0,0.0) [0.0|3.0] ""  DATC
 SG_ TMU_PhoneActivity : 2|2@1+ (1.0,0.0) [0.0|3.0] ""  DATC

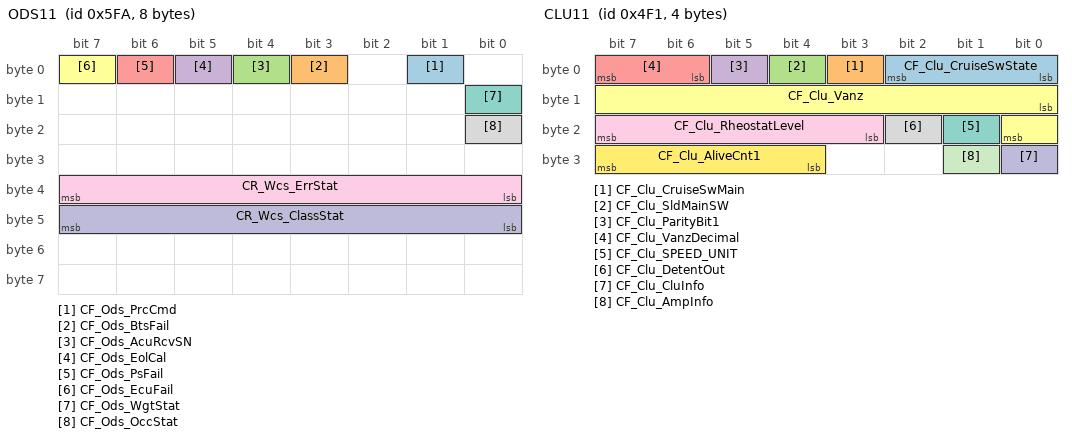
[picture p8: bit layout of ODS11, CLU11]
BO_ 1530 ODS11: 8 ODS
 SG_ CF_Ods_PrcCmd : 1|1@1+ (1.0,0.0) [0.0|1.0] ""  Dummy
 SG_ CF_Ods_BtsFail : 3|1@1+ (1.0,0.0) [0.0|1.0] ""  Dummy
 SG_ CF_Ods_AcuRcvSN : 4|1@1+ (1.0,0.0) [0.0|1.0] ""  ACU
 SG_ CF_Ods_EolCal : 5|1@1+ (1.0,0.0) [0.0|1.0] ""  ACU
 SG_ CF_Ods_PsFail : 6|1@1+ (1.0,0.0) [0.0|1.0] ""  ACU
 SG_ CF_Ods_EcuFail : 7|1@1+ (1.0,0.0) [0.0|1.0] ""  ACU
 SG_ CF_Ods_WgtStat : 8|1@1+ (1.0,0.0) [0.0|1.0] ""  ACU
 SG_ CF_Ods_OccStat : 16|1@1+ (1.0,0.0) [0.0|1.0] ""  ACU
 SG_ CR_Wcs_ErrStat : 32|8@1+ (1.0,0.0) [0.0|63.0] ""  ACU
 SG_ CR_Wcs_ClassStat : 40|8@1+ (1.0,0.0) [0.0|4.0] ""  ACU,BCM

BO_ 1531 ODS12: 8 ODS
 SG_ CR_Ods_SerNum0 : 0|8@1+ (1.0,0.0) [0.0|255.0] ""  ACU
 SG_ CR_Ods_SerNum1 : 8|8@1+ (1.0,0.0) [0.0|255.0] ""  ACU
 SG_ CR_Ods_SerNum2 : 16|8@1+ (1.0,0.0) [0.0|255.0] ""  ACU
 SG_ CR_Ods_SerNum3 : 24|8@1+ (1.0,0.0) [0.0|255.0] ""  ACU
 SG_ CR_Ods_SerNum4 : 32|8@1+ (1.0,0.0) [0.0|255.0] ""  ACU
 SG_ CR_Ods_SerNum5 : 40|8@1+ (1.0,0.0) [0.0|255.0] ""  ACU
 SG_ CR_Ods_SerNum6 : 48|8@1+ (1.0,0.0) [0.0|255.0] ""  ACU
 SG_ CR_Ods_SerNum7 : 56|8@1+ (1.0,0.0) [0.0|255.0] ""  ACU

BO_ 1532 ODS13: 5 ODS
 SG_ CR_Ods_ID : 0|8@1+ (1.0,0.0) [0.0|255.0] ""  ACU
 SG_ CR_Ods_Chksum_H : 8|8@1+ (1.0,0.0) [0.0|255.0] ""  Dummy
 SG_ CR_Ods_Chksum_L : 16|8@1+ (1.0,0.0) [0.0|255.0] ""  Dummy
 SG_ CR_Ods_RomID_H : 24|8@1+ (1.0,0.0) [0.0|255.0] ""  Dummy
 SG_ CR_Ods_RomID_L : 32|8@1+ (1.0,0.0) [0.0|255.0] ""  Dummy

BO_ 1984 CAL_SAS11: 2 ESC
 SG_ CCW : 0|4@1+ (1.0,0.0) [0.0|15.0] ""  SAS
 SG_ SAS_CID : 4|11@1+ (1.0,0.0) [0.0|2047.0] ""  SAS

VAL_ 916 ACCEnable 0 "SCC ready" 1 "SCC temp fault" 2 "SCC permanent fault" 3 "SCC permanent fault, communication issue";

BS_:

BU_: XXX CAMERA FRONT_RADAR ADRV APRK

BO_ 353 MSG_161: 32 CCNC
 SG_ CHECKSUM : 0|16@1+ (1,0) [0|65535] "" XXX
 SG_ COUNTER : 16|8@1+ (1,0) [0|255] "" XXX
 SG_ FCA_ICON : 24|3@1+ (1,0) [0|7] "" XXX
 SG_ FCA_ALT_ICON : 27|3@1+ (1,0) [0|7] "" XXX
 SG_ LKA_ICON : 30|3@1+ (1,0) [0|3] "" XXX
 SG_ HBA_ICON : 33|3@1+ (1,0) [0|7] "" XXX
 SG_ ZEROS_1 : 36|4@1+ (1,0) [0|15] "" XXX
 SG_ ZEROS_2 : 40|2@1+ (1,0) [0|3] "" XXX
 SG_ FCA_IMAGE : 42|3@1+ (1,0) [0|7] "" XXX
 SG_ ZEROS_3 : 45|3@1+ (1,0) [0|7] "" XXX
 SG_ ZEROS_4 : 48|3@1+ (1,0) [0|7] "" XXX
 SG_ BCA_LEFT : 51|3@1+ (1,0) [0|7] "" XXX
 SG_ BCA_RIGHT : 54|3@1+ (1,0) [0|7] "" XXX
 SG_ LCA_LEFT_ARROW : 57|3@1+ (1,0) [0|7] "" XXX
 SG_ LCA_RIGHT_ARROW : 60|3@1+ (1,0) [0|7] "" XXX
 SG_ ZEROS_5 : 63|1@0+ (1,0) [0|1] "" XXX
 SG_ CENTERLINE : 64|2@1+ (1,0) [0|3] "" XXX
 SG_ TARGET : 66|3@1+ (1,0) [0|7] "" XXX
 SG_ TARGET_POSITION : 69|11@1+ (1,0) [0|7] "" XXX
 SG_ LANELINE_LEFT : 80|4@1+ (1,0) [0|15] "" XXX
 SG_ LANELINE_LEFT_POSITION : 84|6@1+ (1,0) [0|15] "" XXX
 SG_ LANELINE_RIGHT : 90|4@1+ (1,0) [0|15] "" XXX
 SG_ LANELINE_RIGHT_POSITION : 94|6@1+ (1,0) [0|3] "" XXX
 SG_ LANELINE_CURVATURE : 100|5@1- (1,15) [0|31] "" XXX
 SG_ LANE_HIGHLIGHT : 105|4@1+ (1,0) [0|15] "" XXX
 SG_ LANE_HIGHLIGHT_DISTANCE : 109|11@1+ (1,0) [0|7] "" XXX
 SG_ LANE_LEFT : 120|3@1+ (1,0) [0|7] "" XXX
 SG_ LANE_RIGHT : 123|3@1+ (1,0) [0|7] "" XXX
 SG_ LANE_ZOOM : 126|2@1+ (1,0) [0|3] "" XXX
 SG_ ALERTS_1 : 128|6@1+ (1,0) [0|63] "" XXX
 SG_ ALERTS_2 : 134|5@1+ (1,0) [0|3] "" XXX
 SG_ ALERTS_3 : 139|4@1+ (1,0) [0|15] "" XXX
 SG_ ALERTS_4 : 143|9@1+ (1,0) [0|511] "" XXX
 SG_ ALERTS_5 : 152|5@1+ (1,0) [0|7] "" XXX
 SG_ MUTE : 157|3@1+ (1,0) [0|7] "" XXX
 SG_ SOUNDS_1 : 160|4@1+ (1,0) [0|3] "" XXX
 SG_ SOUNDS_2 : 164|4@1+ (1,0) [0|3] "" XXX
 SG_ SOUNDS_3 : 168|4@1+ (1,0) [0|15] "" XXX
 SG_ SOUNDS_4 : 172|3@1+ (1,0) [0|7] "" XXX
 SG_ ZEROS_6 : 175|1@0+ (1,0) [0|1] "" XXX
 SG_ ZEROS_7 : 176|5@1+ (1,0) [0|31] "" XXX
 SG_ SETSPEED_HUD : 181|3@1+ (1,0) [0|3] "" XXX
 SG_ DISTANCE_LEAD : 184|5@1+ (1,0) [0|31] "" XXX
 SG_ DISTANCE_CAR : 189|3@1+ (1,0) [0|7] "" XXX
 SG_ DISTANCE_SPACING : 192|4@1+ (1,0) [0|15] "" XXX
 SG_ DISTANCE : 196|4@1+ (1,0) [0|7] "" XXX
 SG_ SETSPEED_SPEED : 200|8@1+ (1,0) [0|255] "" XXX
 SG_ SETSPEED : 208|4@1+ (1,0) [0|3] "" XXX
 SG_ HDA_ICON : 212|4@1+ (1,0) [0|3] "" XXX
 SG_ SLA_ICON : 216|4@1+ (1,0) [0|15] "" XXX
 SG_ NAV_ICON : 220|4@1+ (1,0) [0|3] "" XXX
 SG_ LFA_ICON : 224|4@1+ (1,0) [0|3] "" XXX
 SG_ LCA_LEFT_ICON : 228|4@1+ (1,0) [0|15] "" XXX
 SG_ LCA_RIGHT_ICON : 232|4@1+ (1,0) [0|15] "" XXX
 SG_ BACKGROUND : 236|4@1+ (1,0) [0|15] "" XXX
 SG_ DAW_ICON : 240|3@1+ (1,0) [0|7] "" XXX
 SG_ CAR_CIRCLE : 243|3@1+ (1,0) [0|7] "" XXX
 SG_ ZEROS_8 : 246|2@1+ (1,0) [0|3] "" XXX
 SG_ ZEROS_9 : 248|8@1+ (1,0) [0|255] "" XXX

BO_ 354 MSG_162: 32 CCNC
 SG_ CHECKSUM : 0|16@1+ (1,0) [0|65535] "" XXX
 SG_ COUNTER : 16|8@1+ (1,0) [0|255] "" XXX
 SG_ SPEEDLIMIT_STYLE : 24|4@1+ (1,0) [0|7] "" XXX
 SG_ SPEEDLIMIT_FLASH : 28|4@1+ (1,0) [0|15] "" XXX
 SG_ SPEEDLIMIT : 32|8@1+ (1,0) [0|255] "" XXX
 SG_ SIGNS : 40|8@1+ (1,0) [0|15] "" XXX
 SG_ SPEEDLIMIT_WEATHER : 48|4@1+ (1,0) [0|15] "" XXX
 SG_ VIBRATE : 52|3@1+ (1,0) [0|7] "" XXX
 SG_ ZEROS_1 : 55|1@0+ (1,0) [0|1] "" XXX
 SG_ ZEROS_2 : 56|8@1+ (1,0) [0|255] "" XXX
 SG_ LEAD : 64|5@1+ (1,0) [0|31] "" XXX
 SG_ LEAD_DISTANCE : 69|11@1+ (1,0) [0|2047] "" XXX
 SG_ LEAD_LATERAL : 80|7@1+ (1,0) [0|127] "" XXX
 SG_ ZEROS_3 : 87|1@0+ (1,0) [0|1] "" XXX
 SG_ LEAD_ALT : 88|5@1+ (1,0) [0|31] "" XXX
 SG_ LEAD_ALT_DISTANCE : 93|11@1+ (1,0) [0|2047] "" XXX
 SG_ LEAD_ALT_LATERAL : 104|7@1+ (1,0) [0|127] "" XXX
 SG_ ZEROS_4 : 111|1@0+ (1,0) [0|1] "" XXX
 SG_ LEAD_LEFT : 112|5@1+ (1,0) [0|31] "" XXX
 SG_ LEAD_LEFT_DISTANCE : 117|11@1+ (1,0) [0|2047] "" XXX
 SG_ LEAD_LEFT_LATERAL : 128|7@1+ (1,0) [0|127] "" XXX
 SG_ ZEROS_5 : 135|1@0+ (1,0) [0|1] "" XXX
 SG_ LEAD_RIGHT : 136|5@1+ (1,0) [0|31] "" XXX
 SG_ LEAD_RIGHT_DISTANCE : 141|11@1+ (1,0) [0|2047] "" XXX
 SG_ LEAD_RIGHT_LATERAL : 152|7@1+ (1,0) [0|127] "" XXX
 SG_ ZEROS_6 : 159|1@0+ (1,0) [0|1] "" XXX
 SG_ ZEROS_7 : 160|8@1+ (1,0) [0|255] "" XXX
 SG_ ZEROS_8 : 168|8@1+ (1,0) [0|255] "" XXX
 SG_ ZEROS_9 : 176|8@1+ (1,0) [0|255] "" XXX
 SG_ ZEROS_10 : 184|8@1+ (1,0) [0|255] "" XXX
 SG_ ZEROS_11 : 192|8@1+ (1,0) [0|255] "" XXX
 SG_ ZEROS_12 : 200|8@1+ (1,0) [0|255] "" XXX
 SG_ ZEROS_13 : 208|5@1+ (1,0) [0|31] "" XXX
 SG_ FAULT_FSS : 213|3@1+ (1,0) [0|7] "" XXX
 SG_ FAULT_FCA : 216|3@1+ (1,0) [0|7] "" XXX
 SG_ FAULT_LSS : 219|3@1+ (1,0) [0|7] "" XXX
 SG_ FAULT_SLA : 222|3@1+ (1,0) [0|7] "" XXX
 SG_ FAULT_DAW : 225|3@1+ (1,0) [0|7] "" XXX
 SG_ FAULT_HBA : 228|3@1+ (1,0) [0|7] "" XXX
 SG_ FAULT_SCC : 231|3@1+ (1,0) [0|7] "" XXX
 SG_ FAULT_LFA : 234|3@1+ (1,0) [0|7] "" XXX
 SG_ FAULT_HDA : 237|3@1+ (1,0) [0|7] "" XXX
 SG_ FAULT_LCA : 240|3@1+ (1,0) [0|7] "" XXX
 SG_ FAULT_HDP : 243|3@1+ (1,0) [0|7] "" XXX
 SG_ FAULT_DAS : 246|3@1+ (1,0) [0|7] "" XXX
 SG_ FAULT_ESS : 249|3@1+ (1,0) [0|7] "" XXX
 SG_ ZEROS_14 : 252|4@1+ (1,0) [0|15] "" XXX

BS_:

BU_: IAP ODS _4WD BCM HUD DATC MDPS AAF_Tester AEMC SMK _4WD EPB CUBIS MTS TMU EVP CGW TPMS LPI DI_BOX SPAS EMS LCA TCU IBOX FATC AFLS FPCM SCC AHLS AVM ABS SNV OPI PGS SAS AAF Dummy LDWS_LKAS LVR ESC PSB CLU ECS ACU REA

BO_ 1532 ODS13: 5 ODS
 SG_ CR_Ods_ID : 0|8@1+ (1.0,0.0) [0.0|255.0] ""  ACU
 SG_ CR_Ods_Chksum_H : 8|8@1+ (1.0,0.0) [0.0|255.0] ""  Dummy
 SG_ CR_Ods_Chksum_L : 16|8@1+ (1.0,0.0) [0.0|255.0] ""  Dummy
 SG_ CR_Ods_RomID_H : 24|8@1+ (1.0,0.0) [0.0|255.0] ""  Dummy
 SG_ CR_Ods_RomID_L : 32|8@1+ (1.0,0.0) [0.0|255.0] ""  Dummy

BO_ 1531 ODS12: 8 ODS
 SG_ CR_Ods_SerNum0 : 0|8@1+ (1.0,0.0) [0.0|255.0] ""  ACU
 SG_ CR_Ods_SerNum1 : 8|8@1+ (1.0,0.0) [0.0|255.0] ""  ACU
 SG_ CR_Ods_SerNum2 : 16|8@1+ (1.0,0.0) [0.0|255.0] ""  ACU
 SG_ CR_Ods_SerNum3 : 24|8@1+ (1.0,0.0) [0.0|255.0] ""  ACU
 SG_ CR_Ods_SerNum4 : 32|8@1+ (1.0,0.0) [0.0|255.0] ""  ACU
 SG_ CR_Ods_SerNum5 : 40|8@1+ (1.0,0.0) [0.0|255.0] ""  ACU
 SG_ CR_Ods_SerNum6 : 48|8@1+ (1.0,0.0) [0.0|255.0] ""  ACU
 SG_ CR_Ods_SerNum7 : 56|8@1+ (1.0,0.0) [0.0|255.0] ""  ACU

BO_ 1530 ODS11: 8 ODS
 SG_ CF_Ods_PrcCmd : 1|1@1+ (1.0,0.0) [0.0|1.0] ""  Dummy
 SG_ CF_Ods_BtsFail : 3|1@1+ (1.0,0.0) [0.0|1.0] ""  Dummy
 SG_ CF_Ods_AcuRcvSN : 4|1@1+ (1.0,0.0) [0.0|1.0] ""  ACU
 SG_ CF_Ods_EolCal : 5|1@1+ (1.0,0.0) [0.0|1.0] ""  ACU
 SG_ CF_Ods_PsFail : 6|1@1+ (1.0,0.0) [0.0|1.0] ""  ACU
 SG_ CF_Ods_EcuFail : 7|1@1+ (1.0,0.0) [0.0|1.0] ""  ACU
 SG_ CF_Ods_WgtStat : 8|1@1+ (1.0,0.0) [0.0|1.0] ""  ACU
 SG_ CF_Ods_OccStat : 16|1@1+ (1.0,0.0) [0.0|1.0] ""  ACU
 SG_ CR_Wcs_ErrStat : 32|8@1+ (1.0,0.0) [0.0|63.0] ""  ACU
 SG_ CR_Wcs_ClassStat : 40|8@1+ (1.0,0.0) [0.0|4.0] ""  ACU,BCM

BO_ 1017 ECS12: 4 ECS
 SG_ Height_FL : 0|8@1+ (1.0,-128.0) [-128.0|127.0] "mm"  AFLS
 SG_ Height_FR : 8|8@1+ (1.0,-128.0) [-128.0|127.0] "mm"  AFLS
 SG_ Height_RL : 16|8@1+ (1.0,-128.0) [-128.0|127.0] "mm"  AFLS
 SG_ Height_RR : 24|8@1+ (1.0,-128.0) [-128.0|127.0] "mm"  AFLS

BO_ 1268 SPAS12: 8 SPAS
 SG_ CF_Spas_HMI_Stat : 0|8@1+ (1.0,0.0) [0.0|255.0] ""  CLU
 SG_ CF_Spas_Disp : 8|2@1+ (1.0,0.0) [0.0|3.0] ""  CLU,EMS
 SG_ CF_Spas_FIL_Ind : 10|3@1+ (1.0,0.0) [0.0|7.0] ""  AVM,CLU
 SG_ CF_Spas_FIR_Ind : 13|3@1+ (1.0,0.0) [0.0|7.0] ""  AVM,CLU
 SG_ CF_Spas_FOL_Ind : 16|3@1+ (1.0,0.0) [0.0|7.0] ""  AVM,CLU
 SG_ CF_Spas_FOR_Ind : 19|3@1+ (1.0,0.0) [0.0|7.0] ""  AVM,CLU
 SG_ CF_Spas_VolDown : 22|2@1+ (1.0,0.0) [0.0|3.0] ""  CLU
 SG_ CF_Spas_RIL_Ind : 24|3@1+ (1.0,0.0) [0.0|7.0] ""  AVM,CLU
 SG_ CF_Spas_RIR_Ind : 27|3@1+ (1.0,0.0) [0.0|7.0] ""  AVM,CLU
 SG_ CF_Spas_FLS_Alarm : 30|2@1+ (1.0,0.0) [0.0|3.0] ""  CLU
 SG_ CF_Spas_ROL_Ind : 32|3@1+ (1.0,0.0) [0.0|7.0] ""  AVM,CLU
 SG_ CF_Spas_ROR_Ind : 35|3@1+ (1.0,0.0) [0.0|7.0] ""  AVM,CLU
 SG_ CF_Spas_FCS_Alarm : 38|2@1+ (1.0,0.0) [0.0|3.0] ""  CLU
 SG_ CF_Spas_FI_Ind : 40|3@1+ (1.0,0.0) [0.0|7.0] ""  AVM,CLU
 SG_ CF_Spas_RI_Ind : 43|3@1+ (1.0,0.0) [0.0|7.0] ""  AVM,CLU
 SG_ CF_Spas_FRS_Alarm : 46|2@1+ (1.0,0.0) [0.0|3.0] ""  CLU
 SG_ CF_Spas_FR_Alarm : 48|2@1+ (1.0,0.0) [0.0|3.0] ""  BCM,CLU
 SG_ CF_Spas_RR_Alarm : 50|2@1+ (1.0,0.0) [0.0|3.0] ""  BCM,CLU
 SG_ CF_Spas_BEEP_Alarm : 52|4@1+ (1.0,0.0) [0.0|15.0] ""  BCM,CLU
 SG_ CF_Spas_StatAlarm : 56|1@1+ (1.0,0.0) [0.0|1.0] ""  CLU
 SG_ CF_Spas_RLS_Alarm : 57|2@1+ (1.0,0.0) [0.0|3.0] ""  CLU
 SG_ CF_Spas_RCS_Alarm : 59|2@1+ (1.0,0.0) [0.0|3.0] ""  CLU
 SG_ CF_Spas_RRS_Alarm : 61|2@1+ (1.0,0.0) [0.0|3.0] ""  CLU

BO_ 1265 CLU11: 4 CLU
 SG_ CF_Clu_CruiseSwState : 0|3@1+ (1.0,0.0) [0.0|7.0] ""  EMS,LDWS_LKAS,SCC
 SG_ CF_Clu_CruiseSwMain : 3|1@1+ (1.0,0.0) [0.0|1.0] ""  EMS,LDWS_LKAS,SCC
 SG_ CF_Clu_SldMainSW : 4|1@1+ (1.0,0.0) [0.0|1.0] ""  EMS
 SG_ CF_Clu_ParityBit1 : 5|1@1+ (1.0,0.0) [0.0|1.0] "pulse count"  EMS
 SG_ CF_Clu_VanzDecimal : 6|2@1+ (0.125,0.0) [0.0|0.375] ""  EMS
 SG_ CF_Clu_Vanz : 8|9@1+ (0.5,0.0) [0.0|255.5] "km/h or MPH"  BCM,CUBIS,EMS,IBOX,LDWS_LKAS,MDPS,SCC
 SG_ CF_Clu_SPEED_UNIT : 17|1@1+ (1.0,0.0) [0.0|1.0] ""  BCM,CUBIS,EMS,IBOX,LDWS_LKAS,MDPS,SCC
 SG_ CF_Clu_DetentOut : 18|1@1+ (1.0,0.0) [0.0|1.0] ""  AVM,BCM,LCA,PGS,SPAS
 SG_ CF_Clu_RheostatLevel : 19|5@1+ (1.0,0.0) [0.0|31.0] ""  AVM,BCM,LCA,PGS,SPAS
 SG_ CF_Clu_CluInfo : 24|1@1+ (1.0,0.0) [0.0|1.0] ""  BCM
 SG_ CF_Clu_AmpInfo : 25|1@1+ (1.0,0.0) [0.0|1.0] ""  BCM
 SG_ CF_Clu_AliveCnt1 : 28|4@1+ (1.0,0.0) [0.0|15.0] ""  AHLS,EMS,EPB,LDWS_LKAS,MDPS,SCC

BO_ 1260 Sign_Detection: 8 XXX
 SG_ SpeedLim_Nav_Cam : 40|8@1+ (1,0) [0|255] "km/h / mph" XXX
 SG_ SpeedLim_Nav_Cam2 : 48|8@1+ (1,0) [0|255] "km/h / mph" XXX

BO_ 1492 TMU_GW_PE_01: 8 CLU
 SG_ TMU_IVRActivity : 0|2@1+ (1.0,0.0) [0.0|3.0] ""  DATC
 SG_ TMU_PhoneActivity : 2|2@1+ (1.0,0.0) [0.0|3.0] ""  DATC

BO_ 1491 HU_DATC_PE_00: 8 CLU
 SG_ HU_VRActivity : 0|2@1+ (1.0,0.0) [0.0|3.0] ""  DATC
 SG_ HU_PhoneActivity : 2|2@1+ (1.0,0.0) [0.0|3.0] ""  DATC
 SG_ BlowerNoiseControl : 4|2@1+ (1.0,0.0) [0.0|3.0] ""  DATC

BO_ 1490 HU_DATC_E_02: 8 CLU
 SG_ HU_DATC_RearOnOffSet : 6|2@1+ (1.0,0.0) [0.0|3.0] ""  DATC
 SG_ HU_DATC_ADSOnOffSet : 8|2@1+ (1.0,0.0) [0.0|3.0] ""  DATC

BO_ 1479 EMS21: 8 EMS
 SG_ SCR_LEVEL_WARN_LAMP : 0|1@1+ (1.0,0.0) [0.0|1.0] ""  CLU
 SG_ SCR_LEVEL_WARN : 1|3@1+ (1.0,0.0) [0.0|4.0] ""  CLU
 SG_ SCR_SYS_ERROR_WARN : 4|3@1+ (1.0,0.0) [0.0|7.0] ""  CLU
 SG_ SCR_SYSTEM_WARN_LAMP : 7|1@1+ (1.0,0.0) [0.0|1.0] ""  CLU
 SG_ SCR_INDUCEMENT_EXIT_COND : 8|2@1+ (1.0,0.0) [0.0|3.0] ""  CLU
 SG_ SCR_UREA_LEVEL : 16|8@1+ (0.5,0.0) [0.0|100.0] "%"  CLU
 SG_ SCR_NO_REMAINING_RESTARTS : 24|8@1+ (1.0,0.0) [0.0|255.0] ""  CLU
 SG_ SCR_REMAINING_DISTANCE : 32|16@1+ (1.0,0.0) [0.0|25000.0] "km"  CLU

BO_ 1472 GW_Warning_PE: 8 BCM
 SG_ Audio_VolumeDown : 38|2@1+ (1.0,0.0) [0.0|3.0] ""  CLU
 SG_ Pas_Spkr_Flh_Alarm : 48|2@1+ (1.0,0.0) [0.0|3.0] ""  CLU
 SG_ Pas_Spkr_Fcnt_Alarm : 50|2@1+ (1.0,0.0) [0.0|3.0] ""  CLU
 SG_ Pas_Spkr_Frh_Alarm : 52|2@1+ (1.0,0.0) [0.0|3.0] ""  CLU
 SG_ Pas_Spkr_Rlh_Alarm : 56|2@1+ (1.0,0.0) [0.0|3.0] ""  CLU,PGS
 SG_ Pas_Spkr_Rcnt_Alarm : 58|2@1+ (1.0,0.0) [0.0|3.0] ""  CLU
 SG_ Pas_Spkr_Rrh_Alarm : 60|2@1+ (1.0,0.0) [0.0|3.0] ""  CLU,PGS

BO_ 1984 CAL_SAS11: 2 ESC
 SG_ CCW : 0|4@1+ (1.0,0.0) [0.0|15.0] ""  SAS
 SG_ SAS_CID : 4|11@1+ (1.0,0.0) [0.0|2047.0] ""  SAS

BO_ 1456 CLU12: 4 CLU
 SG_ CF_Clu_Odometer : 0|24@1+ (0.1,0.0) [0.0|1677721.4] "km"  _4WD,AAF,BCM,CUBIS,EMS,EPB,IBOX,LDWS_LKAS,SCC,TPMS

BO_ 688 SAS11: 5 MDPS
 SG_ SAS_Angle : 0|16@1- (0.1,0.0) [-3276.8|3276.7] "Deg"  _4WD,ACU,AFLS,AVM,CLU,ECS,EMS,ESC,IBOX,LCA,LDWS_LKAS,PGS,PSB,SCC,SPAS,TCU,_4WD,ACU,AFLS,AVM,BCM,CLU,ECS,EMS,ESC,IBOX,LCA,LDWS_LKAS,PGS,PSB,SCC,SPAS,TCU
 SG_ SAS_Speed : 16|8@1+ (4.0,0.0) [0.0|1016.0] ""  AFLS,ECS,ESC,IBOX,LDWS_LKAS,SCC,SPAS,TCU,AFLS,ECS,ESC,IBOX,LDWS_LKAS,SCC,SPAS,TCU
 SG_ SAS_Stat : 24|8@1+ (1.0,0.0) [0.0|255.0] ""  ECS,ESC,IBOX,LDWS_LKAS,PSB,SCC,SPAS,TCU,ECS,ESC,IBOX,LDWS_LKAS,PSB,SCC,SPAS,TCU
 SG_ MsgCount : 32|4@1+ (1.0,0.0) [0.0|15.0] ""  ECS,ESC,IBOX,LDWS_LKAS,PSB,SCC,SPAS,ECS,ESC,IBOX,LDWS_LKAS,PSB,SCC,SPAS
 SG_ CheckSum : 36|4@1+ (1.0,0.0) [0.0|15.0] ""  ECS,EMS,ESC,IBOX,LDWS_LKAS,PSB,SCC,SPAS,ECS,EMS,ESC,IBOX,LDWS_LKAS,PSB,SCC,SPAS

BO_ 1441 ACU12: 8 ACU
 SG_ CR_Acu_SN : 0|64@1+ (1.0,0.0) [0.0|0.0] ""  ODS

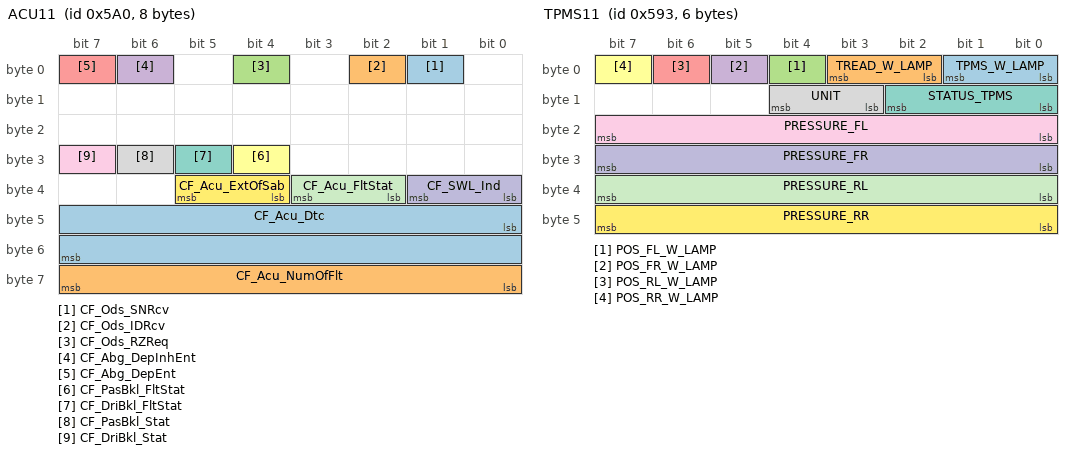
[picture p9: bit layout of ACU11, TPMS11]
BO_ 1440 ACU11: 8 ACU
 SG_ CF_Ods_SNRcv : 1|1@1+ (1.0,0.0) [0.0|1.0] ""  ODS
 SG_ CF_Ods_IDRcv : 2|1@1+ (1.0,0.0) [0.0|1.0] ""  ODS
 SG_ CF_Ods_RZReq : 4|1@1+ (1.0,0.0) [0.0|1.0] ""  ODS
 SG_ CF_Abg_DepInhEnt : 6|1@1+ (1.0,0.0) [0.0|1.0] ""  ODS
 SG_ CF_Abg_DepEnt : 7|1@1+ (1.0,0.0) [0.0|1.0] ""  ODS
 SG_ CF_PasBkl_FltStat : 28|1@1+ (1.0,0.0) [0.0|1.0] ""  ODS,PSB
 SG_ CF_DriBkl_FltStat : 29|1@1+ (1.0,0.0) [0.0|1.0] ""  ODS,PSB
 SG_ CF_PasBkl_Stat : 30|1@1+ (1.0,0.0) [0.0|1.0] ""  IBOX,ODS,PSB,TMU
 SG_ CF_DriBkl_Stat : 31|1@1+ (1.0,0.0) [0.0|1.0] ""  ODS,PSB
 SG_ CF_SWL_Ind : 32|2@1+ (1.0,0.0) [0.0|3.0] ""  CUBIS,IBOX
 SG_ CF_Acu_FltStat : 34|2@1+ (1.0,0.0) [0.0|3.0] ""  CUBIS,IBOX
 SG_ CF_Acu_ExtOfSab : 36|2@1+ (1.0,0.0) [0.0|3.0] ""  BCM,CLU,CUBIS,IBOX
 SG_ CF_Acu_Dtc : 40|16@1+ (1.0,0.0) [0.0|65535.0] ""  CUBIS,IBOX
 SG_ CF_Acu_NumOfFlt : 56|8@1+ (1.0,0.0) [0.0|255.0] ""  CUBIS,IBOX

BO_ 1437 AHLS11: 8 AHLS
 SG_ CF_Ahls_WarnLamp : 0|2@1+ (1.0,0.0) [0.0|3.0] ""  CLU
 SG_ CF_Ahls_WarnMsg : 2|2@1+ (1.0,0.0) [0.0|3.0] ""  CLU

BO_ 1434 PSB11: 2 PSB
 SG_ PSB_LH_FAIL : 0|2@1+ (1.0,0.0) [0.0|3.0] ""  CLU
 SG_ PSB_LH_TGL : 2|1@1+ (1.0,0.0) [0.0|1.0] ""  CLU
 SG_ PSB_LH_ACT : 3|4@1+ (1.0,0.0) [0.0|4.0] ""  Dummy
 SG_ PSB_RH_FAIL : 8|2@1+ (1.0,0.0) [0.0|3.0] ""  CLU
 SG_ PSB_RH_TGL : 10|1@1+ (1.0,0.0) [0.0|1.0] ""  CLU
 SG_ PSB_RH_ACT : 11|4@1+ (1.0,0.0) [0.0|4.0] ""  Dummy

BO_ 916 TCS13: 8 ESC
 SG_ aBasis : 0|11@1+ (0.01,-10.23) [-10.23|10.24] "m/s^2"  EMS,SCC
 SG_ BrakeLight : 11|1@1+ (1.0,0.0) [0.0|1.0] ""  CLU,EMS,SCC
 SG_ DCEnable : 12|1@1+ (1.0,0.0) [0.0|1.0] ""  EMS,SCC
 SG_ AliveCounterTCS : 13|3@1+ (1.0,0.0) [0.0|7.0] ""  EMS,SCC
 SG_ Pre_TCS_CTL : 16|1@1+ (1.0,0.0) [0.0|1.0] ""  Vector__XXX
 SG_ EBA_ACK : 17|1@1+ (1.0,0.0) [0.0|1.0] ""  Vector__XXX
 SG_ FCA_ACK : 18|1@1+ (1.0,0.0) [0.0|1.0] ""  Vector__XXX
 SG_ DF_BF_STAT : 19|2@1+ (1.0,0.0) [0.0|3.0] ""  BCW
 SG_ SCCReqLim : 22|2@1+ (1.0,0.0) [0.0|3.0] ""  SCC
 SG_ TQI_SCC : 24|8@1+ (0.390625,0.0) [0.0|199.609375] "%"  Vector__XXX
 SG_ ACCEL_REF_ACC : 32|11@1+ (0.01,-10.23) [-10.23|10.24] "m/s^2"  EMS,SCC
 SG_ ACCEnable : 43|2@1+ (1.0,0.0) [0.0|3.0] ""  EMS,SCC
 SG_ DriverOverride : 45|2@1+ (1.0,0.0) [0.0|3.0] ""  EMS,SCC
 SG_ StandStill : 47|1@1+ (1.0,0.0) [0.0|1.0] ""  EMS,SCC
 SG_ CheckSum_TCS3 : 48|4@1+ (1.0,0.0) [0.0|15.0] ""  EMS,SCC
 SG_ ACC_EQUIP : 52|1@1+ (1.0,0.0) [0.0|1.0] ""  EMS,SCC
 SG_ PBRAKE_ACT : 53|1@1+ (1.0,0.0) [0.0|1.0] ""  EMS,SCC
 SG_ ACC_REQ : 54|1@1+ (1.0,0.0) [0.0|1.0] ""  EMS
 SG_ DriverBraking : 55|1@1+ (1.0,0.0) [0.0|1.0] ""  EMS,SCC
 SG_ CF_VSM_Coded : 56|1@1+ (1.0,0.0) [0.0|1.0] ""  SCC
 SG_ CF_VSM_Avail : 57|2@1+ (1.0,0.0) [0.0|3.0] ""  CLU,SCC
 SG_ CF_VSM_Handshake : 59|1@1+ (1.0,0.0) [0.0|1.0] ""  SCC
 SG_ CF_DriBkeStat : 60|1@1+ (1.0,0.0) [0.0|1.0] ""  SCC
 SG_ CF_VSM_ConfSwi : 61|2@1+ (1.0,0.0) [0.0|3.0] ""  SCC
 SG_ AEB_EQUIP : 63|1@1+ (1.0,0.0) [0.0|1.0] ""  SCC

BO_ 1427 TPMS11: 6 BCM
 SG_ TPMS_W_LAMP : 0|2@1+ (1.0,0.0) [0.0|3.0] ""  CLU,CUBIS,HUD,IBOX,CLU,CUBIS,HUD,IBOX
 SG_ TREAD_W_LAMP : 2|2@1+ (1.0,0.0) [0.0|3.0] ""  CLU,CUBIS,HUD,IBOX,CLU,CUBIS,HUD,IBOX
 SG_ POS_FL_W_LAMP : 4|1@1+ (1.0,0.0) [0.0|1.0] ""  CLU,CUBIS,HUD,IBOX
 SG_ POS_FR_W_LAMP : 5|1@1+ (1.0,0.0) [0.0|1.0] ""  CLU,CUBIS,HUD,IBOX
 SG_ POS_RL_W_LAMP : 6|1@1+ (1.0,0.0) [0.0|1.0] ""  CLU,CUBIS,HUD,IBOX
 SG_ POS_RR_W_LAMP : 7|1@1+ (1.0,0.0) [0.0|1.0] ""  CLU,CUBIS,HUD,IBOX
 SG_ STATUS_TPMS : 8|3@1+ (1.0,0.0) [0.0|0.0] ""  CLU
 SG_ UNIT : 11|2@1+ (1.0,0.0) [0.0|3.0] ""  CLU
 SG_ PRESSURE_FL : 16|8@1+ (1.0,0.0) [0.0|255.0] ""  CLU
 SG_ PRESSURE_FR : 24|8@1+ (1.0,0.0) [0.0|255.0] ""  CLU
 SG_ PRESSURE_RL : 32|8@1+ (1.0,0.0) [0.0|255.0] ""  CLU
 SG_ PRESSURE_RR : 40|8@1+ (1.0,0.0) [0.0|255.0] ""  CLU

BO_ 915 TCS12: 4 ESC
 SG_ SA_COUNT : 0|16@1+ (2.0,-32768.0) [-32768.0|98302.0] ""  _4WD,ACU,MDPS
 SG_ SA_Z_COUNT : 16|15@1+ (2.0,-32768.0) [-32768.0|32766.0] ""  _4WD,ACU,MDPS
 SG_ SA_Z_FLAG : 31|1@1+ (1.0,0.0) [0.0|1.0] ""  _4WD,ACU,MDPS

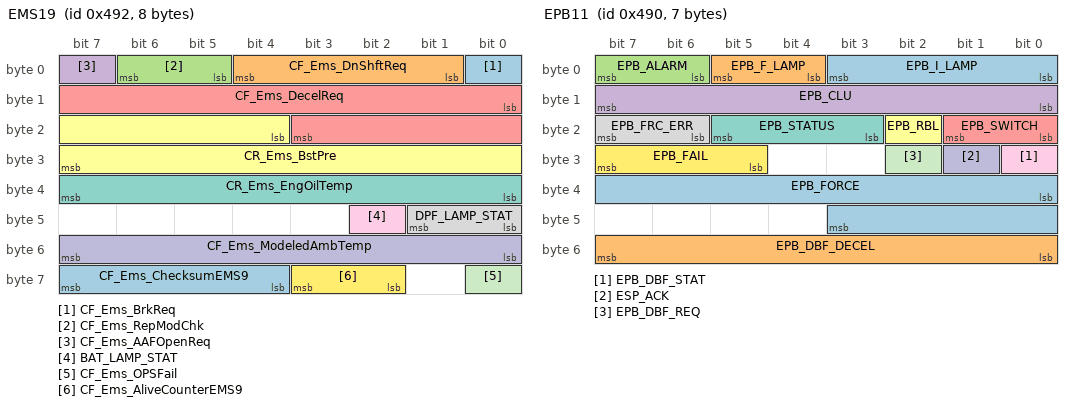
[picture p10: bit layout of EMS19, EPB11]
BO_ 1170 EMS19: 8 EMS
 SG_ CF_Ems_BrkReq : 0|1@1+ (1.0,0.0) [0.0|1.0] ""  ESC,IBOX,TCU
 SG_ CF_Ems_DnShftReq : 1|4@1+ (1.0,0.0) [0.0|14.0] ""  IBOX,TCU
 SG_ CF_Ems_RepModChk : 5|2@1+ (1.0,0.0) [0.0|3.0] ""  IBOX
 SG_ CF_Ems_AAFOpenReq : 7|1@1+ (1.0,0.0) [0.0|1.0] ""  AAF,IBOX
 SG_ CF_Ems_DecelReq : 8|12@1+ (0.0010,-4.094) [-4.094|0.0] "m/s^2"  ESC,IBOX,TCU
 SG_ CR_Ems_BstPre : 20|12@1+ (1.322,0.0) [0.0|4094.0] "hPa"  CLU,IBOX
 SG_ CR_Ems_EngOilTemp : 32|8@1+ (0.75,-40.0) [0.0|254.0] "deg"  CLU,IBOX
 SG_ DPF_LAMP_STAT : 40|2@1+ (1.0,0.0) [0.0|3.0] ""  CLU,IBOX
 SG_ BAT_LAMP_STAT : 42|1@1+ (1.0,0.0) [0.0|1.0] ""  CLU,IBOX
 SG_ CF_Ems_ModeledAmbTemp : 48|8@1+ (0.5,-41.0) [-41.0|85.5] "deg"  AAF,IBOX
 SG_ CF_Ems_OPSFail : 56|1@1+ (1.0,0.0) [0.0|1.0] ""  CLU,IBOX
 SG_ CF_Ems_AliveCounterEMS9 : 58|2@1+ (1.0,0.0) [0.0|3.0] ""  AAF,ABS,CUBIS,ECS,EPB,IBOX,MDPS,REA,SCC,SMK,TCU
 SG_ CF_Ems_ChecksumEMS9 : 60|4@1+ (1.0,0.0) [0.0|15.0] ""  AAF,ABS,CUBIS,ECS,EPB,IBOX,MDPS,REA,SCC,SMK,TCU

BO_ 1425 AFLS11: 2 AFLS
 SG_ AFLS_STAT : 1|2@1+ (1.0,0.0) [0.0|3.0] ""  CLU
 SG_ CF_Afls_TrfChgStat : 3|1@1+ (1.0,0.0) [0.0|1.0] ""  CLU
 SG_ CF_Afls_LedHLStat : 4|2@1+ (1.0,0.0) [0.0|3.0] ""  CLU

BO_ 912 SPAS11: 7 SPAS
 SG_ CF_Spas_Stat : 0|4@1+ (1.0,0.0) [0.0|15.0] ""  ESC,MDPS
 SG_ CF_Spas_TestMode : 4|2@1+ (1.0,0.0) [0.0|3.0] ""  MDPS
 SG_ CR_Spas_StrAngCmd : 8|16@1- (0.1,0.0) [-3276.8|3276.7] ""  MDPS
 SG_ CF_Spas_BeepAlarm : 24|4@1+ (1.0,0.0) [0.0|15.0] ""  CLU
 SG_ CF_Spas_Mode_Seq : 28|2@1+ (1.0,0.0) [0.0|3.0] ""  CLU
 SG_ CF_Spas_AliveCnt : 32|8@1+ (1.0,0.0) [0.0|255.0] ""  MDPS
 SG_ CF_Spas_Chksum : 40|8@1+ (1.0,0.0) [0.0|255.0] ""  MDPS
 SG_ CF_Spas_PasVol : 48|3@1+ (1.0,0.0) [0.0|7.0] ""  CGW,CLU

BO_ 1168 EPB11: 7 EPB
 SG_ EPB_I_LAMP : 0|4@1+ (1.0,0.0) [0.0|15.0] ""  BCM,CLU,CUBIS,ESC,IBOX
 SG_ EPB_F_LAMP : 4|2@1+ (1.0,0.0) [0.0|3.0] ""  CLU,CUBIS,ESC,IBOX
 SG_ EPB_ALARM : 6|2@1+ (1.0,0.0) [0.0|3.0] ""  CLU,ESC
 SG_ EPB_CLU : 8|8@1+ (1.0,0.0) [0.0|255.0] ""  CLU,ESC
 SG_ EPB_SWITCH : 16|2@1+ (1.0,0.0) [0.0|3.0] ""  ESC,SCC
 SG_ EPB_RBL : 18|1@1+ (1.0,0.0) [0.0|1.0] ""  EMS,ESC
 SG_ EPB_STATUS : 19|3@1+ (1.0,0.0) [0.0|7.0] ""  CLU,EMS,ESC,SCC,TCU
 SG_ EPB_FRC_ERR : 22|2@1+ (1.0,0.0) [0.0|3.0] ""  EMS,ESC,SCC,TCU
 SG_ EPB_DBF_STAT : 24|1@1+ (1.0,0.0) [0.0|1.0] ""  ESC
 SG_ ESP_ACK : 25|1@1+ (1.0,0.0) [0.0|1.0] ""  ESC
 SG_ EPB_DBF_REQ : 26|1@1+ (1.0,0.0) [0.0|1.0] ""  ESC
 SG_ EPB_FAIL : 29|3@1+ (1.0,0.0) [0.0|7.0] ""  ESC,SCC
 SG_ EPB_FORCE : 32|12@1+ (1.0,-1000.0) [-1000.0|3000.0] ""  ESC
 SG_ EPB_DBF_DECEL : 48|8@1+ (0.01,0.0) [0.0|2.54] "g"  ESC

BO_ 399 EMS_H12: 8 EMS
 SG_ R_TqAcnApvC : 0|8@1+ (0.2,0.0) [0.0|51.0] "Nm"  DATC,IBOX
 SG_ R_PAcnC : 8|8@1+ (125.0,0.0) [0.0|31875.0] "hPa"  DATC,IBOX
 SG_ TQI_B : 16|8@1+ (0.390625,0.0) [0.0|99.609375] "%"  ABS,ESC,IBOX
 SG_ SLD_VS : 24|8@1+ (1.0,0.0) [0.0|255.0] "km/h"  CLU,IBOX
 SG_ CF_CdaStat : 32|3@1+ (1.0,0.0) [0.0|7.0] ""  AEMC,IBOX,TCU
 SG_ CF_Ems_IsgStat : 35|3@1+ (1.0,0.0) [0.0|7.0] ""  ABS,BCM,CLU,DATC,EPB,ESC,IBOX,LDWS_LKAS,MDPS,SMK,TCU
 SG_ CF_Ems_OilChg : 38|1@1+ (1.0,0.0) [0.0|1.0] ""  CLU,IBOX
 SG_ CF_Ems_EtcLimpMod : 39|1@1+ (1.0,0.0) [0.0|1.0] ""  CLU,IBOX
 SG_ R_NEngIdlTgC : 40|8@1+ (10.0,0.0) [0.0|2550.0] "rpm"  DATC,IBOX,TCU
 SG_ CF_Ems_UpTarGr : 48|1@1+ (1.0,0.0) [0.0|1.0] ""  CLU,IBOX
 SG_ CF_Ems_DownTarGr : 49|1@1+ (1.0,0.0) [0.0|1.0] ""  CLU,IBOX
 SG_ CF_Ems_DesCurGr : 50|4@1+ (1.0,0.0) [0.0|15.0] ""  CLU,IBOX
 SG_ CF_Ems_SldAct : 54|1@1+ (1.0,0.0) [0.0|1.0] ""  CLU,IBOX
 SG_ CF_Ems_SldPosAct : 55|1@1+ (1.0,0.0) [0.0|1.0] ""  CLU,IBOX
 SG_ CF_Ems_HPresStat : 56|1@1+ (1.0,0.0) [0.0|1.0] ""  IBOX,TCU
 SG_ CF_Ems_IsgBuz : 57|1@1+ (1.0,0.0) [0.0|1.0] ""  CLU,IBOX
 SG_ CF_Ems_IdlStpFCO : 58|1@1+ (1.0,0.0) [0.0|1.0] ""  CLU,IBOX
 SG_ CF_Ems_FCopen : 59|1@1+ (1.0,0.0) [0.0|1.0] ""  CLU,IBOX
 SG_ CF_Ems_ActEcoAct : 60|1@1+ (1.0,0.0) [0.0|1.0] ""  CLU,IBOX,TCU
 SG_ CF_Ems_EngRunNorm : 61|1@1+ (1.0,0.0) [0.0|1.0] ""  ABS,ESC,IBOX,TCU
 SG_ CF_Ems_IsgStat2 : 62|2@1+ (2.0,0.0) [0.0|3.0] ""  CLU,IBOX,TCU

BO_ 1419 LCA11: 8 LCA
 SG_ CF_Lca_Stat : 0|4@1+ (1.0,0.0) [0.0|15.0] ""  BCM,CLU
 SG_ CF_Rcta_Stat : 4|4@1+ (1.0,0.0) [0.0|15.0] ""  BCM,CLU
 SG_ CF_Lca_IndLeft : 8|2@1+ (1.0,0.0) [0.0|3.0] ""  BCM,CLU
 SG_ CF_Rcw_Stat : 10|4@1+ (1.0,0.0) [0.0|15.0] ""  BCM,CLU
 SG_ CF_RCW_Warning : 14|2@1+ (1.0,0.0) [0.0|3.0] ""  BCM,CLU
 SG_ CF_Lca_IndRight : 16|2@1+ (1.0,0.0) [0.0|3.0] ""  BCM,CLU
 SG_ CF_Lca_SndWan_Stat : 18|2@1+ (1.0,0.0) [0.0|3.0] ""  BCM,CLU
 SG_ CF_FR_SndWan : 20|1@1+ (1.0,0.0) [0.0|1.0] ""  BCM,CLU
 SG_ CF_FL_SndWan : 21|1@1+ (1.0,0.0) [0.0|1.0] ""  BCM,CLU
 SG_ CF_RR_SndWan : 22|1@1+ (1.0,0.0) [0.0|1.0] ""  BCM,CLU
 SG_ CF_RL_SndWan : 23|1@1+ (1.0,0.0) [0.0|1.0] ""  BCM,CLU
 SG_ CF_Lca_IndBriLeft : 24|8@1+ (1.0,0.0) [0.0|255.0] ""  BCM,CLU
 SG_ CF_Lca_IndBriRight : 32|8@1+ (1.0,0.0) [0.0|255.0] ""  BCM,CLU
 SG_ CF_RCTA_IndBriLeft : 40|8@1+ (1.0,0.0) [0.0|255.0] ""  BCM,CLU
 SG_ CF_RCTA_IndBriRight : 48|8@1+ (1.0,0.0) [0.0|255.0] ""  BCM,CLU
 SG_ CF_RCTA_IndLeft : 56|2@1+ (1.0,0.0) [0.0|3.0] ""  BCM,CLU
 SG_ CF_RCTA_IndRight : 58|2@1+ (1.0,0.0) [0.0|3.0] ""  BCM,CLU
 SG_ CF_SndWarnForClu : 60|1@1+ (1.0,0.0) [0.0|1.0] ""  CLU

BO_ 906 ABS11: 8 ABS
 SG_ ABS_DEF : 0|1@1+ (1.0,0.0) [0.0|1.0] ""  _4WD,ACU,EMS,SPAS,TCU
 SG_ EBD_DEF : 1|1@1+ (1.0,0.0) [0.0|1.0] ""  _4WD,EMS,SPAS,TCU
 SG_ ABS_ACT : 2|1@1+ (1.0,0.0) [0.0|1.0] ""  _4WD,ACU,EPB,SPAS,TCU
 SG_ ABS_W_LAMP : 3|1@1+ (1.0,0.0) [0.0|1.0] ""  _4WD,CLU,CUBIS,MTS,TMU
 SG_ EBD_W_LAMP : 4|1@1+ (1.0,0.0) [0.0|1.0] ""  _4WD,CLU
 SG_ ABS_DIAG : 5|1@1+ (1.0,0.0) [0.0|1.0] ""  _4WD,CLU
 SG_ ESS_STAT : 6|2@1+ (1.0,0.0) [0.0|3.0] ""  _4WD,BCM,CLU,EMS

BO_ 903 WHL_PUL11: 6 ABS
 SG_ WHL_PUL_FL : 0|8@1+ (0.5,0.0) [0.0|127.5] "pulse count"  CUBIS,EPB,IBOX,SPAS,TMU,TPMS,CUBIS,EPB,IBOX,LDWS_LKAS,SPAS,TMU,TPMS
 SG_ WHL_PUL_FR : 8|8@1+ (0.5,0.0) [0.0|127.5] "pulse count"  CUBIS,EPB,IBOX,SPAS,TMU,TPMS,CUBIS,EPB,IBOX,LDWS_LKAS,SPAS,TMU,TPMS
 SG_ WHL_PUL_RL : 16|8@1+ (0.5,0.0) [0.0|127.5] "pulse count"  CUBIS,EPB,IBOX,SPAS,TMU,TPMS,CUBIS,EPB,IBOX,LDWS_LKAS,SPAS,TMU,TPMS
 SG_ WHL_PUL_RR : 24|8@1+ (0.5,0.0) [0.0|127.5] "pulse count"  CUBIS,EPB,IBOX,SPAS,TMU,TPMS,CUBIS,EPB,IBOX,LDWS_LKAS,SPAS,TMU,TPMS
 SG_ WHL_DIR_FL : 32|2@1+ (1.0,0.0) [0.0|3.0] ""  EPB,SPAS,TPMS,EPB,LCA,SPAS,TPMS
 SG_ WHL_DIR_FR : 34|2@1+ (1.0,0.0) [0.0|3.0] ""  EPB,SPAS,TPMS,EPB,LCA,SPAS,TPMS
 SG_ WHL_DIR_RL : 36|2@1+ (1.0,0.0) [0.0|3.0] ""  EPB,SPAS,TPMS,EPB,LCA,SPAS,TPMS
 SG_ WHL_DIR_RR : 38|2@1+ (1.0,0.0) [0.0|3.0] ""  EPB,SPAS,TPMS,EPB,LCA,SPAS,TPMS
 SG_ WHL_PUL_Chksum : 40|8@1+ (1.0,0.0) [0.0|255.0] ""  EPB,SPAS,TPMS,EPB,LCA,LDWS_LKAS,SPAS,TPMS

BO_ 1415 TMU11: 8 IBOX
 SG_ CF_Tmu_VehSld : 0|1@1+ (1.0,0.0) [0.0|1.0] ""  EMS
 SG_ CF_Tmu_VehImmo : 1|1@1+ (1.0,0.0) [0.0|1.0] ""  EMS
 SG_ CF_Tmu_ReqRepCnd : 2|2@1+ (1.0,0.0) [0.0|3.0] ""  EMS
 SG_ CF_Tmu_AirconCtr : 4|1@1+ (1.0,0.0) [0.0|1.0] ""  DATC
 SG_ CF_Tmu_TempMd : 5|1@1+ (1.0,0.0) [0.0|1.0] ""  DATC
 SG_ CF_Tmu_TempSet : 6|16@1+ (1.0,0.0) [0.0|20.0] ""  DATC
 SG_ CF_Tmu_DefrostCtr : 22|1@1+ (1.0,0.0) [0.0|1.0] ""  DATC,FATC
 SG_ CF_Tmu_AliveCnt1 : 56|4@1+ (1.0,0.0) [0.0|15.0] ""  EMS

BO_ 902 WHL_SPD11: 8 ABS
 SG_ WHL_SPD_FL : 0|14@1+ (0.03125,0.0) [0.0|511.96875] "km/h"  _4WD,AFLS,AHLS,AVM,CLU,CUBIS,ECS,EMS,EPB,IBOX,LDWS_LKAS,PGS,PSB,SCC,SMK,SPAS,TCU,TPMS,_4WD,ACU,AFLS,AHLS,AVM,CLU,ECS,EMS,EPB,IBOX,LCA,LDWS_LKAS,PGS,PSB,SCC,SMK,SPAS,TCU,TPMS
 SG_ WHL_SPD_FR : 16|14@1+ (0.03125,0.0) [0.0|511.96875] "km/h"  _4WD,ACU,AFLS,AHLS,AVM,CLU,CUBIS,ECS,EMS,EPB,IBOX,LDWS_LKAS,PGS,PSB,SCC,SMK,SPAS,TCU,TPMS,_4WD,ACU,AFLS,AHLS,AVM,CLU,ECS,EMS,EPB,IBOX,LCA,LDWS_LKAS,PGS,PSB,SCC,SMK,SPAS,TCU,TPMS
 SG_ WHL_SPD_RL : 32|14@1+ (0.03125,0.0) [0.0|511.96875] "km/h"  _4WD,AFLS,AHLS,AVM,BCM,CLU,CUBIS,ECS,EMS,EPB,IBOX,LDWS_LKAS,PGS,PSB,SCC,SMK,SPAS,TCU,TPMS,_4WD,ACU,AFLS,AHLS,AVM,BCM,CLU,ECS,EMS,EPB,IBOX,LCA,LDWS_LKAS,PGS,PSB,SCC,SMK,SPAS,TCU,TPMS
 SG_ WHL_SPD_RR : 48|14@1+ (0.03125,0.0) [0.0|511.96875] "km/h"  _4WD,AFLS,AHLS,AVM,CLU,CUBIS,ECS,EMS,EPB,IBOX,LDWS_LKAS,PGS,PSB,SCC,SMK,SPAS,TCU,TPMS,_4WD,ACU,AFLS,AHLS,AVM,CLU,ECS,EMS,EPB,IBOX,LCA,LDWS_LKAS,PGS,PSB,SCC,SMK,SPAS,TCU,TPMS
 SG_ WHL_SPD_AliveCounter_LSB : 14|2@1+ (1.0,0.0) [0.0|15.0] ""  _4WD,EMS,LPI,TCU,TMU
 SG_ WHL_SPD_AliveCounter_MSB : 30|2@1+ (1.0,0.0) [0.0|15.0] ""  _4WD,EMS,LPI,TCU,TMU
 SG_ WHL_SPD_Checksum_LSB : 46|2@1+ (1.0,0.0) [0.0|15.0] ""  _4WD,EMS,LPI,TCU,TMU
 SG_ WHL_SPD_Checksum_MSB : 62|2@1+ (1.0,0.0) [0.0|15.0] ""  _4WD,EMS,LPI,TCU,TMU

BO_ 1414 EVP11: 3 EVP
 SG_ CF_Evp_Stat : 0|1@1+ (1.0,0.0) [0.0|1.0] ""  CLU

BO_ 1412 AAF11: 8 AAF
 SG_ CF_Aaf_ActFlapStatus : 0|2@1+ (1.0,0.0) [0.0|3.0] ""  AAF_Tester
 SG_ CF_Aaf_ModeStatus : 2|3@1+ (1.0,0.0) [0.0|7.0] ""  AAF_Tester
 SG_ CF_Aaf_WrnLamp : 5|1@1+ (1.0,0.0) [0.0|1.0] ""  CLU
 SG_ CF_Aaf_ErrStatus : 6|10@1+ (1.0,0.0) [0.0|1023.0] ""  AAF_Tester,EMS
 SG_ CF_Aaf_OpenRqSysAct : 16|8@1+ (1.0,0.0) [0.0|255.0] ""  AAF_Tester
 SG_ CF_Aaf_PStatus : 24|8@1+ (1.0,0.0) [0.0|100.0] "%"  AAF_Tester
 SG_ CF_Aaf_OpenRqSysSol : 32|8@1+ (1.0,0.0) [0.0|255.0] ""  AAF_Tester
 SG_ CF_Aaf_SolFlapStatus : 40|2@1+ (1.0,0.0) [0.0|3.0] ""  AAF_Tester
 SG_ CF_Aaf_MilOnReq : 42|1@1+ (1.0,0.0) [0.0|1.0] ""  EMS

BO_ 900 EMS17: 8 EMS
 SG_ CF_Ems_PkpCurMSV : 0|8@1+ (1.0,0.0) [0.0|255.0] ""  DI_BOX
 SG_ CF_Ems_HolCurMSV : 8|8@1+ (1.0,0.0) [0.0|255.0] ""  DI_BOX
 SG_ CF_Ems_InjVBnkAct : 16|8@1+ (1.0,0.0) [0.0|255.0] ""  DI_BOX
 SG_ CF_Ems_InjVActSet : 24|8@1+ (1.0,0.0) [0.0|255.0] ""  DI_BOX
 SG_ CF_Ems_DiagFulHDEV : 32|1@1+ (1.0,0.0) [0.0|1.0] ""  DI_BOX
 SG_ CF_Ems_SwiOffIC1 : 33|1@1+ (1.0,0.0) [0.0|1.0] ""  DI_BOX
 SG_ CF_Ems_SwiOffIC2 : 34|1@1+ (1.0,0.0) [0.0|1.0] ""  DI_BOX
 SG_ CF_Ems_DiagReqHDEV : 38|1@1+ (1.0,0.0) [0.0|1.0] ""  DI_BOX
 SG_ CR_Ems_DutyCycMSV : 40|8@1+ (0.3921568627,0.0) [0.0|100.0] "%"  DI_BOX
 SG_ CR_Ems_BatVolRly : 48|8@1+ (0.1,0.0) [0.0|25.5] "V"  DI_BOX

BO_ 1411 CUBIS11: 8 CUBIS
 SG_ CF_Cubis_HUDisp : 0|4@1+ (1.0,0.0) [0.0|15.0] ""  CLU

BO_ 899 FATC11: 8 DATC
 SG_ CR_Fatc_TqAcnOut : 0|8@1+ (0.2,0.0) [0.0|50.8] "Nm"  EMS,IBOX
 SG_ CF_Fatc_AcnRqSwi : 8|1@1+ (1.0,0.0) [0.0|1.0] ""  AAF,EMS,IBOX
 SG_ CF_Fatc_AcnCltEnRq : 9|1@1+ (1.0,0.0) [0.0|1.0] ""  EMS,IBOX
 SG_ CF_Fatc_EcvFlt : 10|1@1+ (1.0,0.0) [0.0|1.0] ""  EMS,IBOX
 SG_ CF_Fatc_BlwrOn : 11|1@1+ (1.0,0.0) [0.0|1.0] ""  EMS,IBOX
 SG_ CF_FATC_Iden : 12|2@1+ (1.0,0.0) [0.0|3.0] ""  EMS,IBOX
 SG_ CF_Fatc_BlwrMax : 14|1@1+ (1.0,0.0) [0.0|1.0] ""  CLU,EMS,IBOX
 SG_ CF_Fatc_EngStartReq : 15|1@1+ (1.0,0.0) [0.0|1.0] ""  EMS,IBOX
 SG_ CF_Fatc_IsgStopReq : 16|1@1+ (1.0,0.0) [0.0|1.0] ""  EMS,IBOX
 SG_ CF_Fatc_CtrInf : 17|3@1+ (1.0,0.0) [0.0|7.0] ""  EMS,IBOX
 SG_ CF_Fatc_MsgCnt : 20|4@1+ (1.0,0.0) [0.0|15.0] ""  EMS,IBOX
 SG_ CR_Fatc_OutTemp : 24|8@1+ (0.5,-40.0) [-40.0|60.0] "deg"  BCM,CLU,EMS,IBOX,SPAS,TCU,TPMS
 SG_ CR_Fatc_OutTempSns : 32|8@1+ (0.5,-40.0) [-40.0|60.0] "deg"  AAF,AHLS,CLU,EMS,IBOX,SPAS,TCU
 SG_ CF_Fatc_Compload : 40|3@1+ (1.0,0.0) [0.0|7.0] ""  EMS,IBOX
 SG_ CF_Fatc_ActiveEco : 43|1@1+ (1.0,0.0) [0.0|1.0] ""  CLU,IBOX
 SG_ CF_Fatc_AutoActivation : 44|1@1+ (1.0,0.0) [0.0|1.0] ""  IBOX
 SG_ CF_Fatc_DefSw : 45|1@1+ (1.0,0.0) [0.0|1.0] ""  BCM,IBOX
 SG_ CF_Fatc_PtcRlyStat : 46|1@1+ (1.0,0.0) [0.0|1.0] ""  EMS,IBOX
 SG_ CF_Fatc_ChkSum : 56|8@1+ (1.0,0.0) [0.0|255.0] ""  EMS,IBOX,SPAS

BO_ 129 EMS_DCT12: 8 EMS
 SG_ CR_Ems_SoakTimeExt : 0|6@1+ (5.0,0.0) [0.0|315.0] "Min"  TCU
 SG_ BRAKE_ACT : 6|2@1+ (1.0,0.0) [0.0|3.0] ""  TCU
 SG_ CF_Ems_EngOperStat : 8|8@1+ (1.0,0.0) [0.0|255.0] ""  TCU
 SG_ CR_Ems_IndAirTemp : 16|8@1+ (0.75,-48.0) [-48.0|143.25] "deg"  TCU
 SG_ CF_Ems_Alive2 : 56|4@1+ (1.0,0.0) [0.0|15.0] ""  TCU
 SG_ CF_Ems_ChkSum2 : 60|4@1+ (1.0,0.0) [0.0|15.0] ""  TCU

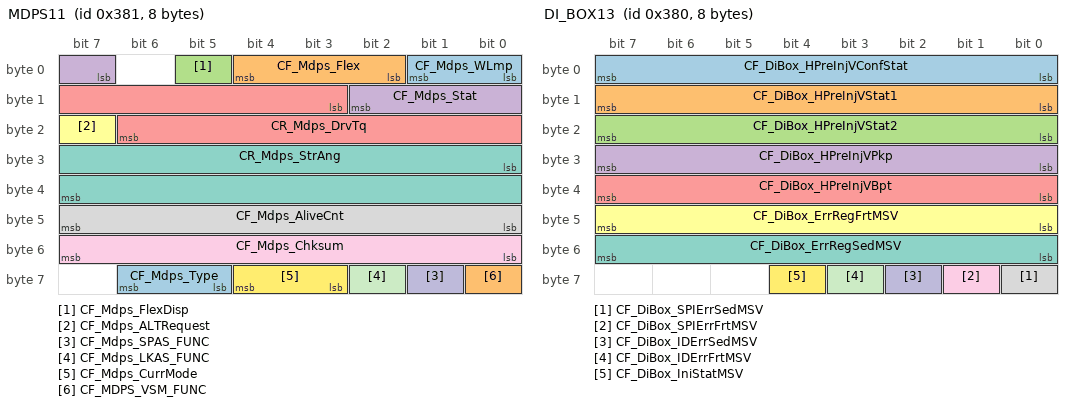
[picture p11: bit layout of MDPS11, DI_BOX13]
BO_ 897 MDPS11: 8 MDPS
 SG_ CF_Mdps_WLmp : 0|2@1+ (1.0,0.0) [0.0|3.0] ""  CLU,CUBIS,EMS,IBOX,SPAS
 SG_ CF_Mdps_Flex : 2|3@1+ (1.0,0.0) [0.0|3.0] ""  CLU,LDWS_LKAS
 SG_ CF_Mdps_FlexDisp : 5|1@1+ (1.0,0.0) [0.0|1.0] ""  CLU
 SG_ CF_Mdps_Stat : 7|4@1+ (1.0,0.0) [0.0|15.0] ""  SPAS
 SG_ CR_Mdps_DrvTq : 11|12@1+ (1.0,-2048.0) [-2048.0|2046.0] ""  SPAS
 SG_ CF_Mdps_ALTRequest : 23|1@1+ (1.0,0.0) [0.0|1.0] ""  EMS
 SG_ CR_Mdps_StrAng : 24|16@1- (0.1,0.0) [-3276.8|3276.7] "Deg"  SPAS
 SG_ CF_Mdps_AliveCnt : 40|8@1+ (1.0,0.0) [0.0|255.0] ""  LDWS_LKAS,SPAS
 SG_ CF_Mdps_Chksum : 48|8@1+ (1.0,0.0) [0.0|255.0] ""  LDWS_LKAS,SPAS
 SG_ CF_Mdps_SPAS_FUNC : 57|1@1+ (1.0,0.0) [0.0|1.0] "flag"  SPAS
 SG_ CF_Mdps_LKAS_FUNC : 58|1@1+ (1.0,0.0) [0.0|1.0] "flag"  LDWS_LKAS
 SG_ CF_Mdps_CurrMode : 59|2@1+ (1.0,0.0) [0.0|3.0] ""  LDWS_LKAS
 SG_ CF_Mdps_Type : 61|2@1+ (1.0,0.0) [0.0|2.0] ""  LDWS_LKAS,SPAS
 SG_ CF_MDPS_VSM_FUNC : 56|1@0+ (1.0,0.0) [0.0|1.0] "" XXX

BO_ 896 DI_BOX13: 8 DI_BOX
 SG_ CF_DiBox_HPreInjVConfStat : 0|8@1+ (1.0,0.0) [0.0|255.0] ""  EMS
 SG_ CF_DiBox_HPreInjVStat1 : 8|8@1+ (1.0,0.0) [0.0|255.0] ""  EMS
 SG_ CF_DiBox_HPreInjVStat2 : 16|8@1+ (1.0,0.0) [0.0|255.0] ""  EMS
 SG_ CF_DiBox_HPreInjVPkp : 24|8@1+ (1.0,0.0) [0.0|255.0] ""  EMS
 SG_ CF_DiBox_HPreInjVBpt : 32|8@1+ (1.0,0.0) [0.0|255.0] ""  EMS
 SG_ CF_DiBox_ErrRegFrtMSV : 40|8@1+ (1.0,0.0) [0.0|255.0] ""  EMS
 SG_ CF_DiBox_ErrRegSedMSV : 48|8@1+ (1.0,0.0) [0.0|255.0] ""  EMS
 SG_ CF_DiBox_SPIErrSedMSV : 56|1@1+ (1.0,0.0) [0.0|1.0] ""  EMS
 SG_ CF_DiBox_SPIErrFrtMSV : 57|1@1+ (1.0,0.0) [0.0|1.0] ""  EMS
 SG_ CF_DiBox_IDErrSedMSV : 58|1@1+ (1.0,0.0) [0.0|1.0] ""  EMS
 SG_ CF_DiBox_IDErrFrtMSV : 59|1@1+ (1.0,0.0) [0.0|1.0] ""  EMS
 SG_ CF_DiBox_IniStatMSV : 60|1@1+ (1.0,0.0) [0.0|1.0] ""  EMS

BO_ 640 EMS13: 8 EMS
 SG_ LV_FUEL_TYPE_ECU : 0|1@1+ (1.0,0.0) [0.0|1.0] ""  BCM,CLU,LPI,SMK
 SG_ LV_BFS_CFIRM : 1|1@1+ (1.0,0.0) [0.0|1.0] ""  LPI
 SG_ LV_CRASH : 2|1@1+ (1.0,0.0) [0.0|1.0] ""  LPI
 SG_ LV_VB_OFF_ACT : 3|1@1+ (1.0,0.0) [0.0|1.0] ""  LPI
 SG_ LV_GSL_MAP M : 4|1@1+ (1.0,0.0) [0.0|1.0] ""  LPI
 SG_ LV_ENG_TURN : 5|1@1+ (1.0,0.0) [0.0|1.0] ""  LPI
 SG_ ERR_FUEL : 8|8@1+ (1.0,0.0) [0.0|255.0] ""  LPI
 SG_ EOS : 16|8@1+ (1.0,0.0) [0.0|255.0] ""  LPI
 SG_ TCO : 24|8@1+ (0.75,-48.0) [-48.0|143.25] "deg"  LPI
 SG_ N_32 : 32|8@1+ (32.0,0.0) [0.0|8160.0] "rpm"  LPI
 SG_ MAF : 40|8@1+ (5.447,0.0) [0.0|1388.985] "mg/TDC"  LPI
 SG_ TIA : 48|8@1+ (0.75,-48.0) [-48.0|143.25] "deg"  LPI
 SG_ MAP m1 : 56|8@1+ (0.47058,0.0) [0.0|119.9979] "kPa"  LPI
 SG_ AMP m0 : 56|8@1+ (21.22,0.0) [0.0|5411.1] "hPa"  LPI

BO_ 128 EMS_DCT11: 8 EMS
 SG_ PV_AV_CAN : 0|8@1+ (0.3906,0.0) [0.0|99.603] "%"  TCU
 SG_ TQ_STND : 8|6@1+ (10.0,0.0) [0.0|630.0] "Nm"  TCU
 SG_ F_N_ENG : 14|1@1+ (1.0,0.0) [0.0|1.0] ""  TCU
 SG_ F_SUB_TQI : 15|1@1+ (1.0,0.0) [0.0|1.0] ""  TCU
 SG_ N : 16|16@1+ (0.25,0.0) [0.0|16383.75] "rpm"  TCU
 SG_ TQI_ACOR : 32|8@1+ (0.390625,0.0) [0.0|99.6094] "%"  IBOX,TCU
 SG_ TQFR : 40|8@1+ (0.390625,0.0) [0.0|99.6094] "%"  TCU
 SG_ TQI : 48|8@1+ (0.390625,0.0) [0.0|99.609375] "%"  TCU
 SG_ CF_Ems_Alive : 56|4@1+ (1.0,0.0) [0.0|15.0] ""  TCU
 SG_ CF_Ems_ChkSum : 60|4@1+ (1.0,0.0) [0.0|15.0] ""  TCU

BO_ 1407 HU_MON_PE_01: 8 CLU
 SG_ HU_Type : 0|8@1+ (1.0,0.0) [0.0|255.0] ""  AVM,PGS

BO_ 127 CGW5: 8 BCM
 SG_ C_StopLampLhOpenSts : 0|1@1+ (1.0,0.0) [0.0|1.0] ""  CLU
 SG_ C_StopLampRhOpenSts : 1|1@1+ (1.0,0.0) [0.0|1.0] ""  CLU
 SG_ C_HMSLOpenSts : 2|1@1+ (1.0,0.0) [0.0|1.0] ""  CLU
 SG_ C_HLampLowLhOpenSts : 3|1@1+ (1.0,0.0) [0.0|1.0] ""  CLU
 SG_ C_HLampLowRhOpenSts : 4|1@1+ (1.0,0.0) [0.0|1.0] ""  CLU
 SG_ C_HLampHighLhOpenSts : 5|1@1+ (1.0,0.0) [0.0|1.0] ""  CLU
 SG_ C_HLampHighRhOpenSts : 6|1@1+ (1.0,0.0) [0.0|1.0] ""  CLU
 SG_ C_DRLLampLhOpenSts : 7|1@1+ (1.0,0.0) [0.0|1.0] ""  CLU
 SG_ C_DRLLampRhOpenSts : 8|1@1+ (1.0,0.0) [0.0|1.0] ""  CLU
 SG_ C_RearFOGLhOpenSts : 9|1@1+ (1.0,0.0) [0.0|1.0] ""  CLU
 SG_ C_RearFOGRhOpenSts : 10|1@1+ (1.0,0.0) [0.0|1.0] ""  CLU
 SG_ C_FrontFOGLhOpenSts : 11|1@1+ (1.0,0.0) [0.0|1.0] ""  CLU
 SG_ C_FrontFOGRhOpenSts : 12|1@1+ (1.0,0.0) [0.0|1.0] ""  CLU
 SG_ C_RearEXTTailLhOpenSts : 13|1@1+ (1.0,0.0) [0.0|1.0] ""  CLU
 SG_ C_RearEXTTailRhOpenSts : 14|1@1+ (1.0,0.0) [0.0|1.0] ""  CLU
 SG_ C_FrontEXTTailLhOpenSts : 15|1@1+ (1.0,0.0) [0.0|1.0] ""  CLU
 SG_ C_FrontEXTTailRhOpenSts : 16|1@1+ (1.0,0.0) [0.0|1.0] ""  CLU
 SG_ C_RearTSIGLhOpenSts : 17|1@1+ (1.0,0.0) [0.0|1.0] ""  CLU
 SG_ C_RearTSIGRhOpenSts : 18|1@1+ (1.0,0.0) [0.0|1.0] ""  CLU
 SG_ C_FrontTSIGLhOpenSts : 19|1@1+ (1.0,0.0) [0.0|1.0] ""  CLU
 SG_ C_FrontTSIGRhOpenSts : 20|1@1+ (1.0,0.0) [0.0|1.0] ""  CLU
 SG_ C_SBendingLhOpenSts : 21|1@1+ (1.0,0.0) [0.0|1.0] ""  CLU
 SG_ C_SBendingRhOpenSts : 22|1@1+ (1.0,0.0) [0.0|1.0] ""  CLU
 SG_ C_LicensePlateLhOpenSts : 23|1@1+ (1.0,0.0) [0.0|1.0] ""  CLU
 SG_ C_LicensePlateRhOpenSts : 24|1@1+ (1.0,0.0) [0.0|1.0] ""  CLU

BO_ 354 TCU_DCT13: 3 TCU
 SG_ Clutch_Driving_Tq : 0|10@1+ (1.0,-512.0) [0.0|0.0] "Nm"  ESC
 SG_ Cluster_Engine_RPM : 10|13@1+ (0.9766,0.0) [0.0|0.0] ""  CLU
 SG_ Cluster_Engine_RPM_Flag : 23|1@1+ (1.0,0.0) [0.0|0.0] ""  CLU

BS_:

BU_: XXX CAMERA FRONT_RADAR ADRV APRK

BO_ 353 MSG_161: 32 CCNC
 SG_ CHECKSUM : 0|16@1+ (1,0) [0|65535] "" XXX
 SG_ COUNTER : 16|8@1+ (1,0) [0|255] "" XXX
 SG_ FCA_ICON : 24|3@1+ (1,0) [0|7] "" XXX
 SG_ FCA_ALT_ICON : 27|3@1+ (1,0) [0|7] "" XXX
 SG_ LKA_ICON : 30|3@1+ (1,0) [0|3] "" XXX
 SG_ HBA_ICON : 33|3@1+ (1,0) [0|7] "" XXX
 SG_ ZEROS_1 : 36|4@1+ (1,0) [0|15] "" XXX
 SG_ ZEROS_2 : 40|2@1+ (1,0) [0|3] "" XXX
 SG_ FCA_IMAGE : 42|3@1+ (1,0) [0|7] "" XXX
 SG_ ZEROS_3 : 45|3@1+ (1,0) [0|7] "" XXX
 SG_ ZEROS_4 : 48|3@1+ (1,0) [0|7] "" XXX
 SG_ BCA_LEFT : 51|3@1+ (1,0) [0|7] "" XXX
 SG_ BCA_RIGHT : 54|3@1+ (1,0) [0|7] "" XXX
 SG_ LCA_LEFT_ARROW : 57|3@1+ (1,0) [0|7] "" XXX
 SG_ LCA_RIGHT_ARROW : 60|3@1+ (1,0) [0|7] "" XXX
 SG_ ZEROS_5 : 63|1@0+ (1,0) [0|1] "" XXX
 SG_ CENTERLINE : 64|2@1+ (1,0) [0|3] "" XXX
 SG_ TARGET : 66|3@1+ (1,0) [0|7] "" XXX
 SG_ TARGET_POSITION : 69|11@1+ (1,0) [0|7] "" XXX
 SG_ LANELINE_LEFT : 80|4@1+ (1,0) [0|15] "" XXX
 SG_ LANELINE_LEFT_POSITION : 84|6@1+ (1,0) [0|15] "" XXX
 SG_ LANELINE_RIGHT : 90|4@1+ (1,0) [0|15] "" XXX
 SG_ LANELINE_RIGHT_POSITION : 94|6@1+ (1,0) [0|3] "" XXX
 SG_ LANELINE_CURVATURE : 100|5@1- (1,15) [0|31] "" XXX
 SG_ LANE_HIGHLIGHT : 105|4@1+ (1,0) [0|15] "" XXX
 SG_ LANE_HIGHLIGHT_DISTANCE : 109|11@1+ (1,0) [0|7] "" XXX
 SG_ LANE_LEFT : 120|3@1+ (1,0) [0|7] "" XXX
 SG_ LANE_RIGHT : 123|3@1+ (1,0) [0|7] "" XXX
 SG_ LANE_ZOOM : 126|2@1+ (1,0) [0|3] "" XXX
 SG_ ALERTS_1 : 128|6@1+ (1,0) [0|63] "" XXX
 SG_ ALERTS_2 : 134|5@1+ (1,0) [0|3] "" XXX
 SG_ ALERTS_3 : 139|4@1+ (1,0) [0|15] "" XXX
 SG_ ALERTS_4 : 143|9@1+ (1,0) [0|511] "" XXX
 SG_ ALERTS_5 : 152|5@1+ (1,0) [0|7] "" XXX
 SG_ MUTE : 157|3@1+ (1,0) [0|7] "" XXX
 SG_ SOUNDS_1 : 160|4@1+ (1,0) [0|3] "" XXX
 SG_ SOUNDS_2 : 164|4@1+ (1,0) [0|3] "" XXX
 SG_ SOUNDS_3 : 168|4@1+ (1,0) [0|15] "" XXX
 SG_ SOUNDS_4 : 172|3@1+ (1,0) [0|7] "" XXX
 SG_ ZEROS_6 : 175|1@0+ (1,0) [0|1] "" XXX
 SG_ ZEROS_7 : 176|5@1+ (1,0) [0|31] "" XXX
 SG_ SETSPEED_HUD : 181|3@1+ (1,0) [0|3] "" XXX
 SG_ DISTANCE_LEAD : 184|5@1+ (1,0) [0|31] "" XXX
 SG_ DISTANCE_CAR : 189|3@1+ (1,0) [0|7] "" XXX
 SG_ DISTANCE_SPACING : 192|4@1+ (1,0) [0|15] "" XXX
 SG_ DISTANCE : 196|4@1+ (1,0) [0|7] "" XXX
 SG_ SETSPEED_SPEED : 200|8@1+ (1,0) [0|255] "" XXX
 SG_ SETSPEED : 208|4@1+ (1,0) [0|3] "" XXX
 SG_ HDA_ICON : 212|4@1+ (1,0) [0|3] "" XXX
 SG_ SLA_ICON : 216|4@1+ (1,0) [0|15] "" XXX
 SG_ NAV_ICON : 220|4@1+ (1,0) [0|3] "" XXX
 SG_ LFA_ICON : 224|4@1+ (1,0) [0|3] "" XXX
 SG_ LCA_LEFT_ICON : 228|4@1+ (1,0) [0|15] "" XXX
 SG_ LCA_RIGHT_ICON : 232|4@1+ (1,0) [0|15] "" XXX
 SG_ BACKGROUND : 236|4@1+ (1,0) [0|15] "" XXX
 SG_ DAW_ICON : 240|3@1+ (1,0) [0|7] "" XXX
 SG_ CAR_CIRCLE : 243|3@1+ (1,0) [0|7] "" XXX
 SG_ ZEROS_8 : 246|2@1+ (1,0) [0|3] "" XXX
 SG_ ZEROS_9 : 248|8@1+ (1,0) [0|255] "" XXX

BO_ 354 MSG_162: 32 CCNC
 SG_ CHECKSUM : 0|16@1+ (1,0) [0|65535] "" XXX
 SG_ COUNTER : 16|8@1+ (1,0) [0|255] "" XXX
 SG_ SPEEDLIMIT_STYLE : 24|4@1+ (1,0) [0|7] "" XXX
 SG_ SPEEDLIMIT_FLASH : 28|4@1+ (1,0) [0|15] "" XXX
 SG_ SPEEDLIMIT : 32|8@1+ (1,0) [0|255] "" XXX
 SG_ SIGNS : 40|8@1+ (1,0) [0|15] "" XXX
 SG_ SPEEDLIMIT_WEATHER : 48|4@1+ (1,0) [0|15] "" XXX
 SG_ VIBRATE : 52|3@1+ (1,0) [0|7] "" XXX
 SG_ ZEROS_1 : 55|1@0+ (1,0) [0|1] "" XXX
 SG_ ZEROS_2 : 56|8@1+ (1,0) [0|255] "" XXX
 SG_ LEAD : 64|5@1+ (1,0) [0|31] "" XXX
 SG_ LEAD_DISTANCE : 69|11@1+ (1,0) [0|2047] "" XXX
 SG_ LEAD_LATERAL : 80|7@1+ (1,0) [0|127] "" XXX
 SG_ ZEROS_3 : 87|1@0+ (1,0) [0|1] "" XXX
 SG_ LEAD_ALT : 88|5@1+ (1,0) [0|31] "" XXX
 SG_ LEAD_ALT_DISTANCE : 93|11@1+ (1,0) [0|2047] "" XXX
 SG_ LEAD_ALT_LATERAL : 104|7@1+ (1,0) [0|127] "" XXX
 SG_ ZEROS_4 : 111|1@0+ (1,0) [0|1] "" XXX
 SG_ LEAD_LEFT : 112|5@1+ (1,0) [0|31] "" XXX
 SG_ LEAD_LEFT_DISTANCE : 117|11@1+ (1,0) [0|2047] "" XXX
 SG_ LEAD_LEFT_LATERAL : 128|7@1+ (1,0) [0|127] "" XXX
 SG_ ZEROS_5 : 135|1@0+ (1,0) [0|1] "" XXX
 SG_ LEAD_RIGHT : 136|5@1+ (1,0) [0|31] "" XXX
 SG_ LEAD_RIGHT_DISTANCE : 141|11@1+ (1,0) [0|2047] "" XXX
 SG_ LEAD_RIGHT_LATERAL : 152|7@1+ (1,0) [0|127] "" XXX
 SG_ ZEROS_6 : 159|1@0+ (1,0) [0|1] "" XXX
 SG_ ZEROS_7 : 160|8@1+ (1,0) [0|255] "" XXX
 SG_ ZEROS_8 : 168|8@1+ (1,0) [0|255] "" XXX
 SG_ ZEROS_9 : 176|8@1+ (1,0) [0|255] "" XXX
 SG_ ZEROS_10 : 184|8@1+ (1,0) [0|255] "" XXX
 SG_ ZEROS_11 : 192|8@1+ (1,0) [0|255] "" XXX
 SG_ ZEROS_12 : 200|8@1+ (1,0) [0|255] "" XXX
 SG_ ZEROS_13 : 208|5@1+ (1,0) [0|31] "" XXX
 SG_ FAULT_FSS : 213|3@1+ (1,0) [0|7] "" XXX
 SG_ FAULT_FCA : 216|3@1+ (1,0) [0|7] "" XXX
 SG_ FAULT_LSS : 219|3@1+ (1,0) [0|7] "" XXX
 SG_ FAULT_SLA : 222|3@1+ (1,0) [0|7] "" XXX
 SG_ FAULT_DAW : 225|3@1+ (1,0) [0|7] "" XXX
 SG_ FAULT_HBA : 228|3@1+ (1,0) [0|7] "" XXX
 SG_ FAULT_SCC : 231|3@1+ (1,0) [0|7] "" XXX
 SG_ FAULT_LFA : 234|3@1+ (1,0) [0|7] "" XXX
 SG_ FAULT_HDA : 237|3@1+ (1,0) [0|7] "" XXX
 SG_ FAULT_LCA : 240|3@1+ (1,0) [0|7] "" XXX
 SG_ FAULT_HDP : 243|3@1+ (1,0) [0|7] "" XXX
 SG_ FAULT_DAS : 246|3@1+ (1,0) [0|7] "" XXX
 SG_ FAULT_ESS : 249|3@1+ (1,0) [0|7] "" XXX
 SG_ ZEROS_14 : 252|4@1+ (1,0) [0|15] "" XXX

BS_:

BU_: IAP ODS _4WD BCM HUD DATC MDPS AAF_Tester AEMC SMK _4WD EPB CUBIS MTS TMU EVP CGW TPMS LPI DI_BOX SPAS EMS LCA TCU IBOX FATC AFLS FPCM SCC AHLS AVM ABS SNV OPI PGS SAS AAF Dummy LDWS_LKAS LVR ESC PSB CLU ECS ACU REA

BO_ 1532 ODS13: 5 ODS
 SG_ CR_Ods_ID : 0|8@1+ (1.0,0.0) [0.0|255.0] ""  ACU
 SG_ CR_Ods_Chksum_H : 8|8@1+ (1.0,0.0) [0.0|255.0] ""  Dummy
 SG_ CR_Ods_Chksum_L : 16|8@1+ (1.0,0.0) [0.0|255.0] ""  Dummy
 SG_ CR_Ods_RomID_H : 24|8@1+ (1.0,0.0) [0.0|255.0] ""  Dummy
 SG_ CR_Ods_RomID_L : 32|8@1+ (1.0,0.0) [0.0|255.0] ""  Dummy

BO_ 1531 ODS12: 8 ODS
 SG_ CR_Ods_SerNum0 : 0|8@1+ (1.0,0.0) [0.0|255.0] ""  ACU
 SG_ CR_Ods_SerNum1 : 8|8@1+ (1.0,0.0) [0.0|255.0] ""  ACU
 SG_ CR_Ods_SerNum2 : 16|8@1+ (1.0,0.0) [0.0|255.0] ""  ACU
 SG_ CR_Ods_SerNum3 : 24|8@1+ (1.0,0.0) [0.0|255.0] ""  ACU
 SG_ CR_Ods_SerNum4 : 32|8@1+ (1.0,0.0) [0.0|255.0] ""  ACU
 SG_ CR_Ods_SerNum5 : 40|8@1+ (1.0,0.0) [0.0|255.0] ""  ACU
 SG_ CR_Ods_SerNum6 : 48|8@1+ (1.0,0.0) [0.0|255.0] ""  ACU
 SG_ CR_Ods_SerNum7 : 56|8@1+ (1.0,0.0) [0.0|255.0] ""  ACU

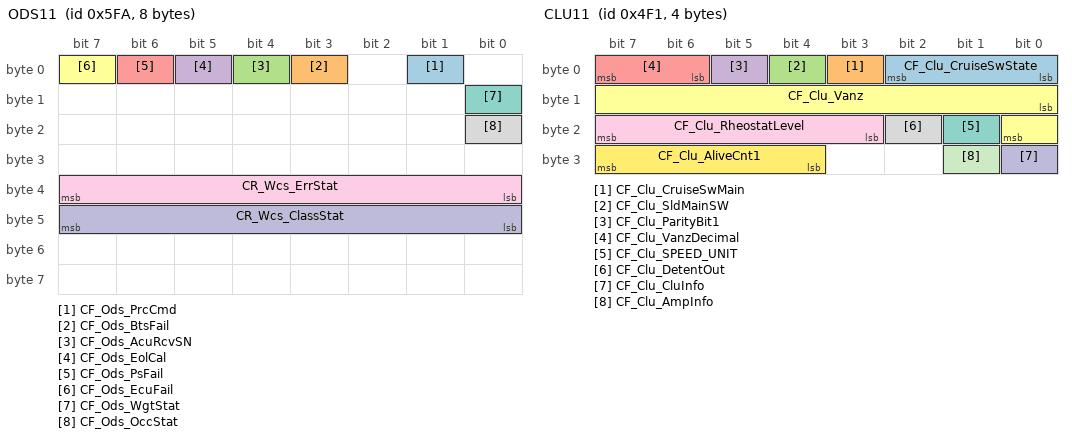
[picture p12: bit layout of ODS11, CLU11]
BO_ 1530 ODS11: 8 ODS
 SG_ CF_Ods_PrcCmd : 1|1@1+ (1.0,0.0) [0.0|1.0] ""  Dummy
 SG_ CF_Ods_BtsFail : 3|1@1+ (1.0,0.0) [0.0|1.0] ""  Dummy
 SG_ CF_Ods_AcuRcvSN : 4|1@1+ (1.0,0.0) [0.0|1.0] ""  ACU
 SG_ CF_Ods_EolCal : 5|1@1+ (1.0,0.0) [0.0|1.0] ""  ACU
 SG_ CF_Ods_PsFail : 6|1@1+ (1.0,0.0) [0.0|1.0] ""  ACU
 SG_ CF_Ods_EcuFail : 7|1@1+ (1.0,0.0) [0.0|1.0] ""  ACU
 SG_ CF_Ods_WgtStat : 8|1@1+ (1.0,0.0) [0.0|1.0] ""  ACU
 SG_ CF_Ods_OccStat : 16|1@1+ (1.0,0.0) [0.0|1.0] ""  ACU
 SG_ CR_Wcs_ErrStat : 32|8@1+ (1.0,0.0) [0.0|63.0] ""  ACU
 SG_ CR_Wcs_ClassStat : 40|8@1+ (1.0,0.0) [0.0|4.0] ""  ACU,BCM

BO_ 1017 ECS12: 4 ECS
 SG_ Height_FL : 0|8@1+ (1.0,-128.0) [-128.0|127.0] "mm"  AFLS
 SG_ Height_FR : 8|8@1+ (1.0,-128.0) [-128.0|127.0] "mm"  AFLS
 SG_ Height_RL : 16|8@1+ (1.0,-128.0) [-128.0|127.0] "mm"  AFLS
 SG_ Height_RR : 24|8@1+ (1.0,-128.0) [-128.0|127.0] "mm"  AFLS

BO_ 1268 SPAS12: 8 SPAS
 SG_ CF_Spas_HMI_Stat : 0|8@1+ (1.0,0.0) [0.0|255.0] ""  CLU
 SG_ CF_Spas_Disp : 8|2@1+ (1.0,0.0) [0.0|3.0] ""  CLU,EMS
 SG_ CF_Spas_FIL_Ind : 10|3@1+ (1.0,0.0) [0.0|7.0] ""  AVM,CLU
 SG_ CF_Spas_FIR_Ind : 13|3@1+ (1.0,0.0) [0.0|7.0] ""  AVM,CLU
 SG_ CF_Spas_FOL_Ind : 16|3@1+ (1.0,0.0) [0.0|7.0] ""  AVM,CLU
 SG_ CF_Spas_FOR_Ind : 19|3@1+ (1.0,0.0) [0.0|7.0] ""  AVM,CLU
 SG_ CF_Spas_VolDown : 22|2@1+ (1.0,0.0) [0.0|3.0] ""  CLU
 SG_ CF_Spas_RIL_Ind : 24|3@1+ (1.0,0.0) [0.0|7.0] ""  AVM,CLU
 SG_ CF_Spas_RIR_Ind : 27|3@1+ (1.0,0.0) [0.0|7.0] ""  AVM,CLU
 SG_ CF_Spas_FLS_Alarm : 30|2@1+ (1.0,0.0) [0.0|3.0] ""  CLU
 SG_ CF_Spas_ROL_Ind : 32|3@1+ (1.0,0.0) [0.0|7.0] ""  AVM,CLU
 SG_ CF_Spas_ROR_Ind : 35|3@1+ (1.0,0.0) [0.0|7.0] ""  AVM,CLU
 SG_ CF_Spas_FCS_Alarm : 38|2@1+ (1.0,0.0) [0.0|3.0] ""  CLU
 SG_ CF_Spas_FI_Ind : 40|3@1+ (1.0,0.0) [0.0|7.0] ""  AVM,CLU
 SG_ CF_Spas_RI_Ind : 43|3@1+ (1.0,0.0) [0.0|7.0] ""  AVM,CLU
 SG_ CF_Spas_FRS_Alarm : 46|2@1+ (1.0,0.0) [0.0|3.0] ""  CLU
 SG_ CF_Spas_FR_Alarm : 48|2@1+ (1.0,0.0) [0.0|3.0] ""  BCM,CLU
 SG_ CF_Spas_RR_Alarm : 50|2@1+ (1.0,0.0) [0.0|3.0] ""  BCM,CLU
 SG_ CF_Spas_BEEP_Alarm : 52|4@1+ (1.0,0.0) [0.0|15.0] ""  BCM,CLU
 SG_ CF_Spas_StatAlarm : 56|1@1+ (1.0,0.0) [0.0|1.0] ""  CLU
 SG_ CF_Spas_RLS_Alarm : 57|2@1+ (1.0,0.0) [0.0|3.0] ""  CLU
 SG_ CF_Spas_RCS_Alarm : 59|2@1+ (1.0,0.0) [0.0|3.0] ""  CLU
 SG_ CF_Spas_RRS_Alarm : 61|2@1+ (1.0,0.0) [0.0|3.0] ""  CLU

BO_ 1265 CLU11: 4 CLU
 SG_ CF_Clu_CruiseSwState : 0|3@1+ (1.0,0.0) [0.0|7.0] ""  EMS,LDWS_LKAS,SCC
 SG_ CF_Clu_CruiseSwMain : 3|1@1+ (1.0,0.0) [0.0|1.0] ""  EMS,LDWS_LKAS,SCC
 SG_ CF_Clu_SldMainSW : 4|1@1+ (1.0,0.0) [0.0|1.0] ""  EMS
 SG_ CF_Clu_ParityBit1 : 5|1@1+ (1.0,0.0) [0.0|1.0] "pulse count"  EMS
 SG_ CF_Clu_VanzDecimal : 6|2@1+ (0.125,0.0) [0.0|0.375] ""  EMS
 SG_ CF_Clu_Vanz : 8|9@1+ (0.5,0.0) [0.0|255.5] "km/h or MPH"  BCM,CUBIS,EMS,IBOX,LDWS_LKAS,MDPS,SCC
 SG_ CF_Clu_SPEED_UNIT : 17|1@1+ (1.0,0.0) [0.0|1.0] ""  BCM,CUBIS,EMS,IBOX,LDWS_LKAS,MDPS,SCC
 SG_ CF_Clu_DetentOut : 18|1@1+ (1.0,0.0) [0.0|1.0] ""  AVM,BCM,LCA,PGS,SPAS
 SG_ CF_Clu_RheostatLevel : 19|5@1+ (1.0,0.0) [0.0|31.0] ""  AVM,BCM,LCA,PGS,SPAS
 SG_ CF_Clu_CluInfo : 24|1@1+ (1.0,0.0) [0.0|1.0] ""  BCM
 SG_ CF_Clu_AmpInfo : 25|1@1+ (1.0,0.0) [0.0|1.0] ""  BCM
 SG_ CF_Clu_AliveCnt1 : 28|4@1+ (1.0,0.0) [0.0|15.0] ""  AHLS,EMS,EPB,LDWS_LKAS,MDPS,SCC

BO_ 1260 Sign_Detection: 8 XXX
 SG_ SpeedLim_Nav_Cam : 40|8@1+ (1,0) [0|255] "km/h / mph" XXX
 SG_ SpeedLim_Nav_Cam2 : 48|8@1+ (1,0) [0|255] "km/h / mph" XXX

BO_ 1492 TMU_GW_PE_01: 8 CLU
 SG_ TMU_IVRActivity : 0|2@1+ (1.0,0.0) [0.0|3.0] ""  DATC
 SG_ TMU_PhoneActivity : 2|2@1+ (1.0,0.0) [0.0|3.0] ""  DATC

BO_ 1491 HU_DATC_PE_00: 8 CLU
 SG_ HU_VRActivity : 0|2@1+ (1.0,0.0) [0.0|3.0] ""  DATC
 SG_ HU_PhoneActivity : 2|2@1+ (1.0,0.0) [0.0|3.0] ""  DATC
 SG_ BlowerNoiseControl : 4|2@1+ (1.0,0.0) [0.0|3.0] ""  DATC

BO_ 1490 HU_DATC_E_02: 8 CLU
 SG_ HU_DATC_RearOnOffSet : 6|2@1+ (1.0,0.0) [0.0|3.0] ""  DATC
 SG_ HU_DATC_ADSOnOffSet : 8|2@1+ (1.0,0.0) [0.0|3.0] ""  DATC

BO_ 1479 EMS21: 8 EMS
 SG_ SCR_LEVEL_WARN_LAMP : 0|1@1+ (1.0,0.0) [0.0|1.0] ""  CLU
 SG_ SCR_LEVEL_WARN : 1|3@1+ (1.0,0.0) [0.0|4.0] ""  CLU
 SG_ SCR_SYS_ERROR_WARN : 4|3@1+ (1.0,0.0) [0.0|7.0] ""  CLU
 SG_ SCR_SYSTEM_WARN_LAMP : 7|1@1+ (1.0,0.0) [0.0|1.0] ""  CLU
 SG_ SCR_INDUCEMENT_EXIT_COND : 8|2@1+ (1.0,0.0) [0.0|3.0] ""  CLU
 SG_ SCR_UREA_LEVEL : 16|8@1+ (0.5,0.0) [0.0|100.0] "%"  CLU
 SG_ SCR_NO_REMAINING_RESTARTS : 24|8@1+ (1.0,0.0) [0.0|255.0] ""  CLU
 SG_ SCR_REMAINING_DISTANCE : 32|16@1+ (1.0,0.0) [0.0|25000.0] "km"  CLU

BO_ 1472 GW_Warning_PE: 8 BCM
 SG_ Audio_VolumeDown : 38|2@1+ (1.0,0.0) [0.0|3.0] ""  CLU
 SG_ Pas_Spkr_Flh_Alarm : 48|2@1+ (1.0,0.0) [0.0|3.0] ""  CLU
 SG_ Pas_Spkr_Fcnt_Alarm : 50|2@1+ (1.0,0.0) [0.0|3.0] ""  CLU
 SG_ Pas_Spkr_Frh_Alarm : 52|2@1+ (1.0,0.0) [0.0|3.0] ""  CLU
 SG_ Pas_Spkr_Rlh_Alarm : 56|2@1+ (1.0,0.0) [0.0|3.0] ""  CLU,PGS
 SG_ Pas_Spkr_Rcnt_Alarm : 58|2@1+ (1.0,0.0) [0.0|3.0] ""  CLU
 SG_ Pas_Spkr_Rrh_Alarm : 60|2@1+ (1.0,0.0) [0.0|3.0] ""  CLU,PGS

BO_ 1984 CAL_SAS11: 2 ESC
 SG_ CCW : 0|4@1+ (1.0,0.0) [0.0|15.0] ""  SAS
 SG_ SAS_CID : 4|11@1+ (1.0,0.0) [0.0|2047.0] ""  SAS

BO_ 1456 CLU12: 4 CLU
 SG_ CF_Clu_Odometer : 0|24@1+ (0.1,0.0) [0.0|1677721.4] "km"  _4WD,AAF,BCM,CUBIS,EMS,EPB,IBOX,LDWS_LKAS,SCC,TPMS

BO_ 688 SAS11: 5 MDPS
 SG_ SAS_Angle : 0|16@1- (0.1,0.0) [-3276.8|3276.7] "Deg"  _4WD,ACU,AFLS,AVM,CLU,ECS,EMS,ESC,IBOX,LCA,LDWS_LKAS,PGS,PSB,SCC,SPAS,TCU,_4WD,ACU,AFLS,AVM,BCM,CLU,ECS,EMS,ESC,IBOX,LCA,LDWS_LKAS,PGS,PSB,SCC,SPAS,TCU
 SG_ SAS_Speed : 16|8@1+ (4.0,0.0) [0.0|1016.0] ""  AFLS,ECS,ESC,IBOX,LDWS_LKAS,SCC,SPAS,TCU,AFLS,ECS,ESC,IBOX,LDWS_LKAS,SCC,SPAS,TCU
 SG_ SAS_Stat : 24|8@1+ (1.0,0.0) [0.0|255.0] ""  ECS,ESC,IBOX,LDWS_LKAS,PSB,SCC,SPAS,TCU,ECS,ESC,IBOX,LDWS_LKAS,PSB,SCC,SPAS,TCU
 SG_ MsgCount : 32|4@1+ (1.0,0.0) [0.0|15.0] ""  ECS,ESC,IBOX,LDWS_LKAS,PSB,SCC,SPAS,ECS,ESC,IBOX,LDWS_LKAS,PSB,SCC,SPAS
 SG_ CheckSum : 36|4@1+ (1.0,0.0) [0.0|15.0] ""  ECS,EMS,ESC,IBOX,LDWS_LKAS,PSB,SCC,SPAS,ECS,EMS,ESC,IBOX,LDWS_LKAS,PSB,SCC,SPAS

BO_ 1441 ACU12: 8 ACU
 SG_ CR_Acu_SN : 0|64@1+ (1.0,0.0) [0.0|0.0] ""  ODS

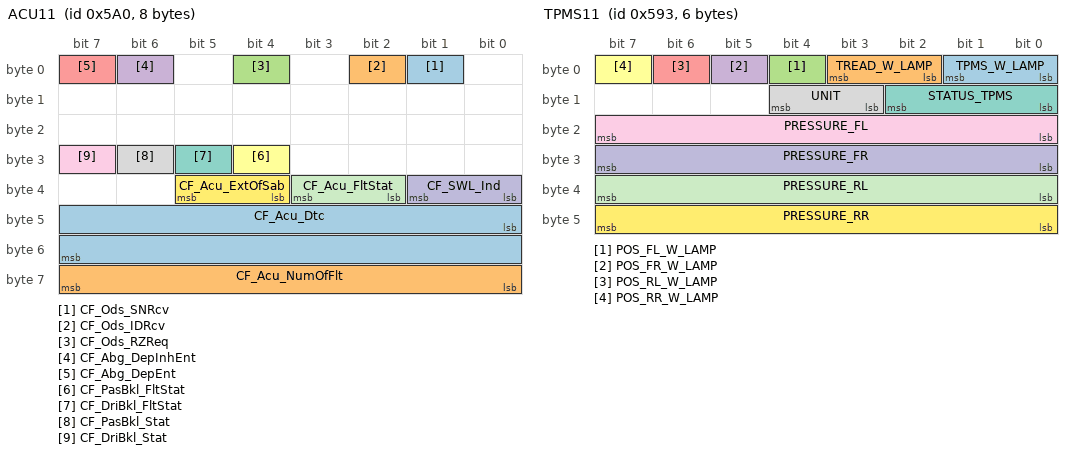
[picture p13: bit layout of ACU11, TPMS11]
BO_ 1440 ACU11: 8 ACU
 SG_ CF_Ods_SNRcv : 1|1@1+ (1.0,0.0) [0.0|1.0] ""  ODS
 SG_ CF_Ods_IDRcv : 2|1@1+ (1.0,0.0) [0.0|1.0] ""  ODS
 SG_ CF_Ods_RZReq : 4|1@1+ (1.0,0.0) [0.0|1.0] ""  ODS
 SG_ CF_Abg_DepInhEnt : 6|1@1+ (1.0,0.0) [0.0|1.0] ""  ODS
 SG_ CF_Abg_DepEnt : 7|1@1+ (1.0,0.0) [0.0|1.0] ""  ODS
 SG_ CF_PasBkl_FltStat : 28|1@1+ (1.0,0.0) [0.0|1.0] ""  ODS,PSB
 SG_ CF_DriBkl_FltStat : 29|1@1+ (1.0,0.0) [0.0|1.0] ""  ODS,PSB
 SG_ CF_PasBkl_Stat : 30|1@1+ (1.0,0.0) [0.0|1.0] ""  IBOX,ODS,PSB,TMU
 SG_ CF_DriBkl_Stat : 31|1@1+ (1.0,0.0) [0.0|1.0] ""  ODS,PSB
 SG_ CF_SWL_Ind : 32|2@1+ (1.0,0.0) [0.0|3.0] ""  CUBIS,IBOX
 SG_ CF_Acu_FltStat : 34|2@1+ (1.0,0.0) [0.0|3.0] ""  CUBIS,IBOX
 SG_ CF_Acu_ExtOfSab : 36|2@1+ (1.0,0.0) [0.0|3.0] ""  BCM,CLU,CUBIS,IBOX
 SG_ CF_Acu_Dtc : 40|16@1+ (1.0,0.0) [0.0|65535.0] ""  CUBIS,IBOX
 SG_ CF_Acu_NumOfFlt : 56|8@1+ (1.0,0.0) [0.0|255.0] ""  CUBIS,IBOX

BO_ 1437 AHLS11: 8 AHLS
 SG_ CF_Ahls_WarnLamp : 0|2@1+ (1.0,0.0) [0.0|3.0] ""  CLU
 SG_ CF_Ahls_WarnMsg : 2|2@1+ (1.0,0.0) [0.0|3.0] ""  CLU

BO_ 1434 PSB11: 2 PSB
 SG_ PSB_LH_FAIL : 0|2@1+ (1.0,0.0) [0.0|3.0] ""  CLU
 SG_ PSB_LH_TGL : 2|1@1+ (1.0,0.0) [0.0|1.0] ""  CLU
 SG_ PSB_LH_ACT : 3|4@1+ (1.0,0.0) [0.0|4.0] ""  Dummy
 SG_ PSB_RH_FAIL : 8|2@1+ (1.0,0.0) [0.0|3.0] ""  CLU
 SG_ PSB_RH_TGL : 10|1@1+ (1.0,0.0) [0.0|1.0] ""  CLU
 SG_ PSB_RH_ACT : 11|4@1+ (1.0,0.0) [0.0|4.0] ""  Dummy

BO_ 916 TCS13: 8 ESC
 SG_ aBasis : 0|11@1+ (0.01,-10.23) [-10.23|10.24] "m/s^2"  EMS,SCC
 SG_ BrakeLight : 11|1@1+ (1.0,0.0) [0.0|1.0] ""  CLU,EMS,SCC
 SG_ DCEnable : 12|1@1+ (1.0,0.0) [0.0|1.0] ""  EMS,SCC
 SG_ AliveCounterTCS : 13|3@1+ (1.0,0.0) [0.0|7.0] ""  EMS,SCC
 SG_ Pre_TCS_CTL : 16|1@1+ (1.0,0.0) [0.0|1.0] ""  Vector__XXX
 SG_ EBA_ACK : 17|1@1+ (1.0,0.0) [0.0|1.0] ""  Vector__XXX
 SG_ FCA_ACK : 18|1@1+ (1.0,0.0) [0.0|1.0] ""  Vector__XXX
 SG_ DF_BF_STAT : 19|2@1+ (1.0,0.0) [0.0|3.0] ""  BCW
 SG_ SCCReqLim : 22|2@1+ (1.0,0.0) [0.0|3.0] ""  SCC
 SG_ TQI_SCC : 24|8@1+ (0.390625,0.0) [0.0|199.609375] "%"  Vector__XXX
 SG_ ACCEL_REF_ACC : 32|11@1+ (0.01,-10.23) [-10.23|10.24] "m/s^2"  EMS,SCC
 SG_ ACCEnable : 43|2@1+ (1.0,0.0) [0.0|3.0] ""  EMS,SCC
 SG_ DriverOverride : 45|2@1+ (1.0,0.0) [0.0|3.0] ""  EMS,SCC
 SG_ StandStill : 47|1@1+ (1.0,0.0) [0.0|1.0] ""  EMS,SCC
 SG_ CheckSum_TCS3 : 48|4@1+ (1.0,0.0) [0.0|15.0] ""  EMS,SCC
 SG_ ACC_EQUIP : 52|1@1+ (1.0,0.0) [0.0|1.0] ""  EMS,SCC
 SG_ PBRAKE_ACT : 53|1@1+ (1.0,0.0) [0.0|1.0] ""  EMS,SCC
 SG_ ACC_REQ : 54|1@1+ (1.0,0.0) [0.0|1.0] ""  EMS
 SG_ DriverBraking : 55|1@1+ (1.0,0.0) [0.0|1.0] ""  EMS,SCC
 SG_ CF_VSM_Coded : 56|1@1+ (1.0,0.0) [0.0|1.0] ""  SCC
 SG_ CF_VSM_Avail : 57|2@1+ (1.0,0.0) [0.0|3.0] ""  CLU,SCC
 SG_ CF_VSM_Handshake : 59|1@1+ (1.0,0.0) [0.0|1.0] ""  SCC
 SG_ CF_DriBkeStat : 60|1@1+ (1.0,0.0) [0.0|1.0] ""  SCC
 SG_ CF_VSM_ConfSwi : 61|2@1+ (1.0,0.0) [0.0|3.0] ""  SCC
 SG_ AEB_EQUIP : 63|1@1+ (1.0,0.0) [0.0|1.0] ""  SCC

BO_ 1427 TPMS11: 6 BCM
 SG_ TPMS_W_LAMP : 0|2@1+ (1.0,0.0) [0.0|3.0] ""  CLU,CUBIS,HUD,IBOX,CLU,CUBIS,HUD,IBOX
 SG_ TREAD_W_LAMP : 2|2@1+ (1.0,0.0) [0.0|3.0] ""  CLU,CUBIS,HUD,IBOX,CLU,CUBIS,HUD,IBOX
 SG_ POS_FL_W_LAMP : 4|1@1+ (1.0,0.0) [0.0|1.0] ""  CLU,CUBIS,HUD,IBOX
 SG_ POS_FR_W_LAMP : 5|1@1+ (1.0,0.0) [0.0|1.0] ""  CLU,CUBIS,HUD,IBOX
 SG_ POS_RL_W_LAMP : 6|1@1+ (1.0,0.0) [0.0|1.0] ""  CLU,CUBIS,HUD,IBOX
 SG_ POS_RR_W_LAMP : 7|1@1+ (1.0,0.0) [0.0|1.0] ""  CLU,CUBIS,HUD,IBOX
 SG_ STATUS_TPMS : 8|3@1+ (1.0,0.0) [0.0|0.0] ""  CLU
 SG_ UNIT : 11|2@1+ (1.0,0.0) [0.0|3.0] ""  CLU
 SG_ PRESSURE_FL : 16|8@1+ (1.0,0.0) [0.0|255.0] ""  CLU
 SG_ PRESSURE_FR : 24|8@1+ (1.0,0.0) [0.0|255.0] ""  CLU
 SG_ PRESSURE_RL : 32|8@1+ (1.0,0.0) [0.0|255.0] ""  CLU
 SG_ PRESSURE_RR : 40|8@1+ (1.0,0.0) [0.0|255.0] ""  CLU

BO_ 915 TCS12: 4 ESC
 SG_ SA_COUNT : 0|16@1+ (2.0,-32768.0) [-32768.0|98302.0] ""  _4WD,ACU,MDPS
 SG_ SA_Z_COUNT : 16|15@1+ (2.0,-32768.0) [-32768.0|32766.0] ""  _4WD,ACU,MDPS
 SG_ SA_Z_FLAG : 31|1@1+ (1.0,0.0) [0.0|1.0] ""  _4WD,ACU,MDPS

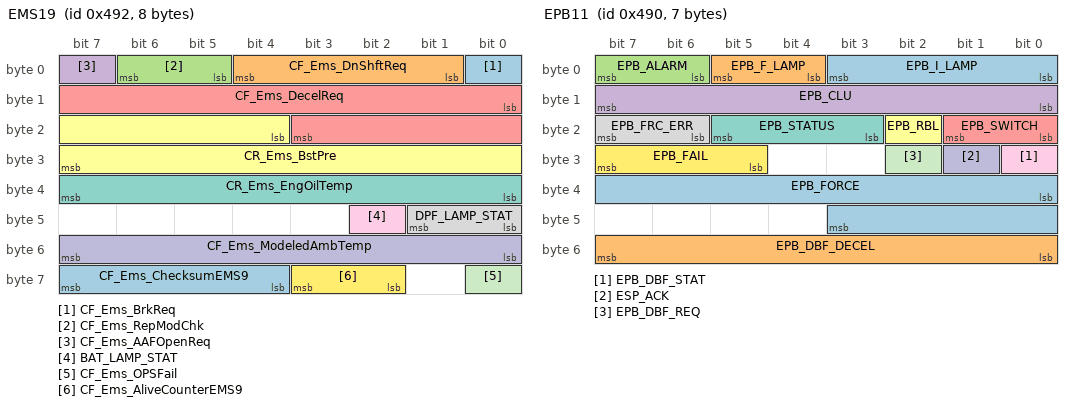
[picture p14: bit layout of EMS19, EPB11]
BO_ 1170 EMS19: 8 EMS
 SG_ CF_Ems_BrkReq : 0|1@1+ (1.0,0.0) [0.0|1.0] ""  ESC,IBOX,TCU
 SG_ CF_Ems_DnShftReq : 1|4@1+ (1.0,0.0) [0.0|14.0] ""  IBOX,TCU
 SG_ CF_Ems_RepModChk : 5|2@1+ (1.0,0.0) [0.0|3.0] ""  IBOX
 SG_ CF_Ems_AAFOpenReq : 7|1@1+ (1.0,0.0) [0.0|1.0] ""  AAF,IBOX
 SG_ CF_Ems_DecelReq : 8|12@1+ (0.0010,-4.094) [-4.094|0.0] "m/s^2"  ESC,IBOX,TCU
 SG_ CR_Ems_BstPre : 20|12@1+ (1.322,0.0) [0.0|4094.0] "hPa"  CLU,IBOX
 SG_ CR_Ems_EngOilTemp : 32|8@1+ (0.75,-40.0) [0.0|254.0] "deg"  CLU,IBOX
 SG_ DPF_LAMP_STAT : 40|2@1+ (1.0,0.0) [0.0|3.0] ""  CLU,IBOX
 SG_ BAT_LAMP_STAT : 42|1@1+ (1.0,0.0) [0.0|1.0] ""  CLU,IBOX
 SG_ CF_Ems_ModeledAmbTemp : 48|8@1+ (0.5,-41.0) [-41.0|85.5] "deg"  AAF,IBOX
 SG_ CF_Ems_OPSFail : 56|1@1+ (1.0,0.0) [0.0|1.0] ""  CLU,IBOX
 SG_ CF_Ems_AliveCounterEMS9 : 58|2@1+ (1.0,0.0) [0.0|3.0] ""  AAF,ABS,CUBIS,ECS,EPB,IBOX,MDPS,REA,SCC,SMK,TCU
 SG_ CF_Ems_ChecksumEMS9 : 60|4@1+ (1.0,0.0) [0.0|15.0] ""  AAF,ABS,CUBIS,ECS,EPB,IBOX,MDPS,REA,SCC,SMK,TCU

BO_ 1425 AFLS11: 2 AFLS
 SG_ AFLS_STAT : 1|2@1+ (1.0,0.0) [0.0|3.0] ""  CLU
 SG_ CF_Afls_TrfChgStat : 3|1@1+ (1.0,0.0) [0.0|1.0] ""  CLU
 SG_ CF_Afls_LedHLStat : 4|2@1+ (1.0,0.0) [0.0|3.0] ""  CLU

BO_ 912 SPAS11: 7 SPAS
 SG_ CF_Spas_Stat : 0|4@1+ (1.0,0.0) [0.0|15.0] ""  ESC,MDPS
 SG_ CF_Spas_TestMode : 4|2@1+ (1.0,0.0) [0.0|3.0] ""  MDPS
 SG_ CR_Spas_StrAngCmd : 8|16@1- (0.1,0.0) [-3276.8|3276.7] ""  MDPS
 SG_ CF_Spas_BeepAlarm : 24|4@1+ (1.0,0.0) [0.0|15.0] ""  CLU
 SG_ CF_Spas_Mode_Seq : 28|2@1+ (1.0,0.0) [0.0|3.0] ""  CLU
 SG_ CF_Spas_AliveCnt : 32|8@1+ (1.0,0.0) [0.0|255.0] ""  MDPS
 SG_ CF_Spas_Chksum : 40|8@1+ (1.0,0.0) [0.0|255.0] ""  MDPS
 SG_ CF_Spas_PasVol : 48|3@1+ (1.0,0.0) [0.0|7.0] ""  CGW,CLU

BO_ 1168 EPB11: 7 EPB
 SG_ EPB_I_LAMP : 0|4@1+ (1.0,0.0) [0.0|15.0] ""  BCM,CLU,CUBIS,ESC,IBOX
 SG_ EPB_F_LAMP : 4|2@1+ (1.0,0.0) [0.0|3.0] ""  CLU,CUBIS,ESC,IBOX
 SG_ EPB_ALARM : 6|2@1+ (1.0,0.0) [0.0|3.0] ""  CLU,ESC
 SG_ EPB_CLU : 8|8@1+ (1.0,0.0) [0.0|255.0] ""  CLU,ESC
 SG_ EPB_SWITCH : 16|2@1+ (1.0,0.0) [0.0|3.0] ""  ESC,SCC
 SG_ EPB_RBL : 18|1@1+ (1.0,0.0) [0.0|1.0] ""  EMS,ESC
 SG_ EPB_STATUS : 19|3@1+ (1.0,0.0) [0.0|7.0] ""  CLU,EMS,ESC,SCC,TCU
 SG_ EPB_FRC_ERR : 22|2@1+ (1.0,0.0) [0.0|3.0] ""  EMS,ESC,SCC,TCU
 SG_ EPB_DBF_STAT : 24|1@1+ (1.0,0.0) [0.0|1.0] ""  ESC
 SG_ ESP_ACK : 25|1@1+ (1.0,0.0) [0.0|1.0] ""  ESC
 SG_ EPB_DBF_REQ : 26|1@1+ (1.0,0.0) [0.0|1.0] ""  ESC
 SG_ EPB_FAIL : 29|3@1+ (1.0,0.0) [0.0|7.0] ""  ESC,SCC
 SG_ EPB_FORCE : 32|12@1+ (1.0,-1000.0) [-1000.0|3000.0] ""  ESC
 SG_ EPB_DBF_DECEL : 48|8@1+ (0.01,0.0) [0.0|2.54] "g"  ESC

BO_ 399 EMS_H12: 8 EMS
 SG_ R_TqAcnApvC : 0|8@1+ (0.2,0.0) [0.0|51.0] "Nm"  DATC,IBOX
 SG_ R_PAcnC : 8|8@1+ (125.0,0.0) [0.0|31875.0] "hPa"  DATC,IBOX
 SG_ TQI_B : 16|8@1+ (0.390625,0.0) [0.0|99.609375] "%"  ABS,ESC,IBOX
 SG_ SLD_VS : 24|8@1+ (1.0,0.0) [0.0|255.0] "km/h"  CLU,IBOX
 SG_ CF_CdaStat : 32|3@1+ (1.0,0.0) [0.0|7.0] ""  AEMC,IBOX,TCU
 SG_ CF_Ems_IsgStat : 35|3@1+ (1.0,0.0) [0.0|7.0] ""  ABS,BCM,CLU,DATC,EPB,ESC,IBOX,LDWS_LKAS,MDPS,SMK,TCU
 SG_ CF_Ems_OilChg : 38|1@1+ (1.0,0.0) [0.0|1.0] ""  CLU,IBOX
 SG_ CF_Ems_EtcLimpMod : 39|1@1+ (1.0,0.0) [0.0|1.0] ""  CLU,IBOX
 SG_ R_NEngIdlTgC : 40|8@1+ (10.0,0.0) [0.0|2550.0] "rpm"  DATC,IBOX,TCU
 SG_ CF_Ems_UpTarGr : 48|1@1+ (1.0,0.0) [0.0|1.0] ""  CLU,IBOX
 SG_ CF_Ems_DownTarGr : 49|1@1+ (1.0,0.0) [0.0|1.0] ""  CLU,IBOX
 SG_ CF_Ems_DesCurGr : 50|4@1+ (1.0,0.0) [0.0|15.0] ""  CLU,IBOX
 SG_ CF_Ems_SldAct : 54|1@1+ (1.0,0.0) [0.0|1.0] ""  CLU,IBOX
 SG_ CF_Ems_SldPosAct : 55|1@1+ (1.0,0.0) [0.0|1.0] ""  CLU,IBOX
 SG_ CF_Ems_HPresStat : 56|1@1+ (1.0,0.0) [0.0|1.0] ""  IBOX,TCU
 SG_ CF_Ems_IsgBuz : 57|1@1+ (1.0,0.0) [0.0|1.0] ""  CLU,IBOX
 SG_ CF_Ems_IdlStpFCO : 58|1@1+ (1.0,0.0) [0.0|1.0] ""  CLU,IBOX
 SG_ CF_Ems_FCopen : 59|1@1+ (1.0,0.0) [0.0|1.0] ""  CLU,IBOX
 SG_ CF_Ems_ActEcoAct : 60|1@1+ (1.0,0.0) [0.0|1.0] ""  CLU,IBOX,TCU
 SG_ CF_Ems_EngRunNorm : 61|1@1+ (1.0,0.0) [0.0|1.0] ""  ABS,ESC,IBOX,TCU
 SG_ CF_Ems_IsgStat2 : 62|2@1+ (2.0,0.0) [0.0|3.0] ""  CLU,IBOX,TCU

BO_ 1419 LCA11: 8 LCA
 SG_ CF_Lca_Stat : 0|4@1+ (1.0,0.0) [0.0|15.0] ""  BCM,CLU
 SG_ CF_Rcta_Stat : 4|4@1+ (1.0,0.0) [0.0|15.0] ""  BCM,CLU
 SG_ CF_Lca_IndLeft : 8|2@1+ (1.0,0.0) [0.0|3.0] ""  BCM,CLU
 SG_ CF_Rcw_Stat : 10|4@1+ (1.0,0.0) [0.0|15.0] ""  BCM,CLU
 SG_ CF_RCW_Warning : 14|2@1+ (1.0,0.0) [0.0|3.0] ""  BCM,CLU
 SG_ CF_Lca_IndRight : 16|2@1+ (1.0,0.0) [0.0|3.0] ""  BCM,CLU
 SG_ CF_Lca_SndWan_Stat : 18|2@1+ (1.0,0.0) [0.0|3.0] ""  BCM,CLU
 SG_ CF_FR_SndWan : 20|1@1+ (1.0,0.0) [0.0|1.0] ""  BCM,CLU
 SG_ CF_FL_SndWan : 21|1@1+ (1.0,0.0) [0.0|1.0] ""  BCM,CLU
 SG_ CF_RR_SndWan : 22|1@1+ (1.0,0.0) [0.0|1.0] ""  BCM,CLU
 SG_ CF_RL_SndWan : 23|1@1+ (1.0,0.0) [0.0|1.0] ""  BCM,CLU
 SG_ CF_Lca_IndBriLeft : 24|8@1+ (1.0,0.0) [0.0|255.0] ""  BCM,CLU
 SG_ CF_Lca_IndBriRight : 32|8@1+ (1.0,0.0) [0.0|255.0] ""  BCM,CLU
 SG_ CF_RCTA_IndBriLeft : 40|8@1+ (1.0,0.0) [0.0|255.0] ""  BCM,CLU
 SG_ CF_RCTA_IndBriRight : 48|8@1+ (1.0,0.0) [0.0|255.0] ""  BCM,CLU
 SG_ CF_RCTA_IndLeft : 56|2@1+ (1.0,0.0) [0.0|3.0] ""  BCM,CLU
 SG_ CF_RCTA_IndRight : 58|2@1+ (1.0,0.0) [0.0|3.0] ""  BCM,CLU
 SG_ CF_SndWarnForClu : 60|1@1+ (1.0,0.0) [0.0|1.0] ""  CLU

BO_ 906 ABS11: 8 ABS
 SG_ ABS_DEF : 0|1@1+ (1.0,0.0) [0.0|1.0] ""  _4WD,ACU,EMS,SPAS,TCU
 SG_ EBD_DEF : 1|1@1+ (1.0,0.0) [0.0|1.0] ""  _4WD,EMS,SPAS,TCU
 SG_ ABS_ACT : 2|1@1+ (1.0,0.0) [0.0|1.0] ""  _4WD,ACU,EPB,SPAS,TCU
 SG_ ABS_W_LAMP : 3|1@1+ (1.0,0.0) [0.0|1.0] ""  _4WD,CLU,CUBIS,MTS,TMU
 SG_ EBD_W_LAMP : 4|1@1+ (1.0,0.0) [0.0|1.0] ""  _4WD,CLU
 SG_ ABS_DIAG : 5|1@1+ (1.0,0.0) [0.0|1.0] ""  _4WD,CLU
 SG_ ESS_STAT : 6|2@1+ (1.0,0.0) [0.0|3.0] ""  _4WD,BCM,CLU,EMS

BO_ 903 WHL_PUL11: 6 ABS
 SG_ WHL_PUL_FL : 0|8@1+ (0.5,0.0) [0.0|127.5] "pulse count"  CUBIS,EPB,IBOX,SPAS,TMU,TPMS,CUBIS,EPB,IBOX,LDWS_LKAS,SPAS,TMU,TPMS
 SG_ WHL_PUL_FR : 8|8@1+ (0.5,0.0) [0.0|127.5] "pulse count"  CUBIS,EPB,IBOX,SPAS,TMU,TPMS,CUBIS,EPB,IBOX,LDWS_LKAS,SPAS,TMU,TPMS
 SG_ WHL_PUL_RL : 16|8@1+ (0.5,0.0) [0.0|127.5] "pulse count"  CUBIS,EPB,IBOX,SPAS,TMU,TPMS,CUBIS,EPB,IBOX,LDWS_LKAS,SPAS,TMU,TPMS
 SG_ WHL_PUL_RR : 24|8@1+ (0.5,0.0) [0.0|127.5] "pulse count"  CUBIS,EPB,IBOX,SPAS,TMU,TPMS,CUBIS,EPB,IBOX,LDWS_LKAS,SPAS,TMU,TPMS
 SG_ WHL_DIR_FL : 32|2@1+ (1.0,0.0) [0.0|3.0] ""  EPB,SPAS,TPMS,EPB,LCA,SPAS,TPMS
 SG_ WHL_DIR_FR : 34|2@1+ (1.0,0.0) [0.0|3.0] ""  EPB,SPAS,TPMS,EPB,LCA,SPAS,TPMS
 SG_ WHL_DIR_RL : 36|2@1+ (1.0,0.0) [0.0|3.0] ""  EPB,SPAS,TPMS,EPB,LCA,SPAS,TPMS
 SG_ WHL_DIR_RR : 38|2@1+ (1.0,0.0) [0.0|3.0] ""  EPB,SPAS,TPMS,EPB,LCA,SPAS,TPMS
 SG_ WHL_PUL_Chksum : 40|8@1+ (1.0,0.0) [0.0|255.0] ""  EPB,SPAS,TPMS,EPB,LCA,LDWS_LKAS,SPAS,TPMS

BO_ 1415 TMU11: 8 IBOX
 SG_ CF_Tmu_VehSld : 0|1@1+ (1.0,0.0) [0.0|1.0] ""  EMS
 SG_ CF_Tmu_VehImmo : 1|1@1+ (1.0,0.0) [0.0|1.0] ""  EMS
 SG_ CF_Tmu_ReqRepCnd : 2|2@1+ (1.0,0.0) [0.0|3.0] ""  EMS
 SG_ CF_Tmu_AirconCtr : 4|1@1+ (1.0,0.0) [0.0|1.0] ""  DATC
 SG_ CF_Tmu_TempMd : 5|1@1+ (1.0,0.0) [0.0|1.0] ""  DATC
 SG_ CF_Tmu_TempSet : 6|16@1+ (1.0,0.0) [0.0|20.0] ""  DATC
 SG_ CF_Tmu_DefrostCtr : 22|1@1+ (1.0,0.0) [0.0|1.0] ""  DATC,FATC
 SG_ CF_Tmu_AliveCnt1 : 56|4@1+ (1.0,0.0) [0.0|15.0] ""  EMS

BO_ 902 WHL_SPD11: 8 ABS
 SG_ WHL_SPD_FL : 0|14@1+ (0.03125,0.0) [0.0|511.96875] "km/h"  _4WD,AFLS,AHLS,AVM,CLU,CUBIS,ECS,EMS,EPB,IBOX,LDWS_LKAS,PGS,PSB,SCC,SMK,SPAS,TCU,TPMS,_4WD,ACU,AFLS,AHLS,AVM,CLU,ECS,EMS,EPB,IBOX,LCA,LDWS_LKAS,PGS,PSB,SCC,SMK,SPAS,TCU,TPMS
 SG_ WHL_SPD_FR : 16|14@1+ (0.03125,0.0) [0.0|511.96875] "km/h"  _4WD,ACU,AFLS,AHLS,AVM,CLU,CUBIS,ECS,EMS,EPB,IBOX,LDWS_LKAS,PGS,PSB,SCC,SMK,SPAS,TCU,TPMS,_4WD,ACU,AFLS,AHLS,AVM,CLU,ECS,EMS,EPB,IBOX,LCA,LDWS_LKAS,PGS,PSB,SCC,SMK,SPAS,TCU,TPMS
 SG_ WHL_SPD_RL : 32|14@1+ (0.03125,0.0) [0.0|511.96875] "km/h"  _4WD,AFLS,AHLS,AVM,BCM,CLU,CUBIS,ECS,EMS,EPB,IBOX,LDWS_LKAS,PGS,PSB,SCC,SMK,SPAS,TCU,TPMS,_4WD,ACU,AFLS,AHLS,AVM,BCM,CLU,ECS,EMS,EPB,IBOX,LCA,LDWS_LKAS,PGS,PSB,SCC,SMK,SPAS,TCU,TPMS
 SG_ WHL_SPD_RR : 48|14@1+ (0.03125,0.0) [0.0|511.96875] "km/h"  _4WD,AFLS,AHLS,AVM,CLU,CUBIS,ECS,EMS,EPB,IBOX,LDWS_LKAS,PGS,PSB,SCC,SMK,SPAS,TCU,TPMS,_4WD,ACU,AFLS,AHLS,AVM,CLU,ECS,EMS,EPB,IBOX,LCA,LDWS_LKAS,PGS,PSB,SCC,SMK,SPAS,TCU,TPMS
 SG_ WHL_SPD_AliveCounter_LSB : 14|2@1+ (1.0,0.0) [0.0|15.0] ""  _4WD,EMS,LPI,TCU,TMU
 SG_ WHL_SPD_AliveCounter_MSB : 30|2@1+ (1.0,0.0) [0.0|15.0] ""  _4WD,EMS,LPI,TCU,TMU
 SG_ WHL_SPD_Checksum_LSB : 46|2@1+ (1.0,0.0) [0.0|15.0] ""  _4WD,EMS,LPI,TCU,TMU
 SG_ WHL_SPD_Checksum_MSB : 62|2@1+ (1.0,0.0) [0.0|15.0] ""  _4WD,EMS,LPI,TCU,TMU

BO_ 1414 EVP11: 3 EVP
 SG_ CF_Evp_Stat : 0|1@1+ (1.0,0.0) [0.0|1.0] ""  CLU

BO_ 1412 AAF11: 8 AAF
 SG_ CF_Aaf_ActFlapStatus : 0|2@1+ (1.0,0.0) [0.0|3.0] ""  AAF_Tester
 SG_ CF_Aaf_ModeStatus : 2|3@1+ (1.0,0.0) [0.0|7.0] ""  AAF_Tester
 SG_ CF_Aaf_WrnLamp : 5|1@1+ (1.0,0.0) [0.0|1.0] ""  CLU
 SG_ CF_Aaf_ErrStatus : 6|10@1+ (1.0,0.0) [0.0|1023.0] ""  AAF_Tester,EMS
 SG_ CF_Aaf_OpenRqSysAct : 16|8@1+ (1.0,0.0) [0.0|255.0] ""  AAF_Tester
 SG_ CF_Aaf_PStatus : 24|8@1+ (1.0,0.0) [0.0|100.0] "%"  AAF_Tester
 SG_ CF_Aaf_OpenRqSysSol : 32|8@1+ (1.0,0.0) [0.0|255.0] ""  AAF_Tester
 SG_ CF_Aaf_SolFlapStatus : 40|2@1+ (1.0,0.0) [0.0|3.0] ""  AAF_Tester
 SG_ CF_Aaf_MilOnReq : 42|1@1+ (1.0,0.0) [0.0|1.0] ""  EMS

BO_ 900 EMS17: 8 EMS
 SG_ CF_Ems_PkpCurMSV : 0|8@1+ (1.0,0.0) [0.0|255.0] ""  DI_BOX
 SG_ CF_Ems_HolCurMSV : 8|8@1+ (1.0,0.0) [0.0|255.0] ""  DI_BOX
 SG_ CF_Ems_InjVBnkAct : 16|8@1+ (1.0,0.0) [0.0|255.0] ""  DI_BOX
 SG_ CF_Ems_InjVActSet : 24|8@1+ (1.0,0.0) [0.0|255.0] ""  DI_BOX
 SG_ CF_Ems_DiagFulHDEV : 32|1@1+ (1.0,0.0) [0.0|1.0] ""  DI_BOX
 SG_ CF_Ems_SwiOffIC1 : 33|1@1+ (1.0,0.0) [0.0|1.0] ""  DI_BOX
 SG_ CF_Ems_SwiOffIC2 : 34|1@1+ (1.0,0.0) [0.0|1.0] ""  DI_BOX
 SG_ CF_Ems_DiagReqHDEV : 38|1@1+ (1.0,0.0) [0.0|1.0] ""  DI_BOX
 SG_ CR_Ems_DutyCycMSV : 40|8@1+ (0.3921568627,0.0) [0.0|100.0] "%"  DI_BOX
 SG_ CR_Ems_BatVolRly : 48|8@1+ (0.1,0.0) [0.0|25.5] "V"  DI_BOX

BO_ 1411 CUBIS11: 8 CUBIS
 SG_ CF_Cubis_HUDisp : 0|4@1+ (1.0,0.0) [0.0|15.0] ""  CLU

BO_ 899 FATC11: 8 DATC
 SG_ CR_Fatc_TqAcnOut : 0|8@1+ (0.2,0.0) [0.0|50.8] "Nm"  EMS,IBOX
 SG_ CF_Fatc_AcnRqSwi : 8|1@1+ (1.0,0.0) [0.0|1.0] ""  AAF,EMS,IBOX
 SG_ CF_Fatc_AcnCltEnRq : 9|1@1+ (1.0,0.0) [0.0|1.0] ""  EMS,IBOX
 SG_ CF_Fatc_EcvFlt : 10|1@1+ (1.0,0.0) [0.0|1.0] ""  EMS,IBOX
 SG_ CF_Fatc_BlwrOn : 11|1@1+ (1.0,0.0) [0.0|1.0] ""  EMS,IBOX
 SG_ CF_FATC_Iden : 12|2@1+ (1.0,0.0) [0.0|3.0] ""  EMS,IBOX
 SG_ CF_Fatc_BlwrMax : 14|1@1+ (1.0,0.0) [0.0|1.0] ""  CLU,EMS,IBOX
 SG_ CF_Fatc_EngStartReq : 15|1@1+ (1.0,0.0) [0.0|1.0] ""  EMS,IBOX
 SG_ CF_Fatc_IsgStopReq : 16|1@1+ (1.0,0.0) [0.0|1.0] ""  EMS,IBOX
 SG_ CF_Fatc_CtrInf : 17|3@1+ (1.0,0.0) [0.0|7.0] ""  EMS,IBOX
 SG_ CF_Fatc_MsgCnt : 20|4@1+ (1.0,0.0) [0.0|15.0] ""  EMS,IBOX
 SG_ CR_Fatc_OutTemp : 24|8@1+ (0.5,-40.0) [-40.0|60.0] "deg"  BCM,CLU,EMS,IBOX,SPAS,TCU,TPMS
 SG_ CR_Fatc_OutTempSns : 32|8@1+ (0.5,-40.0) [-40.0|60.0] "deg"  AAF,AHLS,CLU,EMS,IBOX,SPAS,TCU
 SG_ CF_Fatc_Compload : 40|3@1+ (1.0,0.0) [0.0|7.0] ""  EMS,IBOX
 SG_ CF_Fatc_ActiveEco : 43|1@1+ (1.0,0.0) [0.0|1.0] ""  CLU,IBOX
 SG_ CF_Fatc_AutoActivation : 44|1@1+ (1.0,0.0) [0.0|1.0] ""  IBOX
 SG_ CF_Fatc_DefSw : 45|1@1+ (1.0,0.0) [0.0|1.0] ""  BCM,IBOX
 SG_ CF_Fatc_PtcRlyStat : 46|1@1+ (1.0,0.0) [0.0|1.0] ""  EMS,IBOX
 SG_ CF_Fatc_ChkSum : 56|8@1+ (1.0,0.0) [0.0|255.0] ""  EMS,IBOX,SPAS

BO_ 129 EMS_DCT12: 8 EMS
 SG_ CR_Ems_SoakTimeExt : 0|6@1+ (5.0,0.0) [0.0|315.0] "Min"  TCU
 SG_ BRAKE_ACT : 6|2@1+ (1.0,0.0) [0.0|3.0] ""  TCU
 SG_ CF_Ems_EngOperStat : 8|8@1+ (1.0,0.0) [0.0|255.0] ""  TCU
 SG_ CR_Ems_IndAirTemp : 16|8@1+ (0.75,-48.0) [-48.0|143.25] "deg"  TCU
 SG_ CF_Ems_Alive2 : 56|4@1+ (1.0,0.0) [0.0|15.0] ""  TCU
 SG_ CF_Ems_ChkSum2 : 60|4@1+ (1.0,0.0) [0.0|15.0] ""  TCU

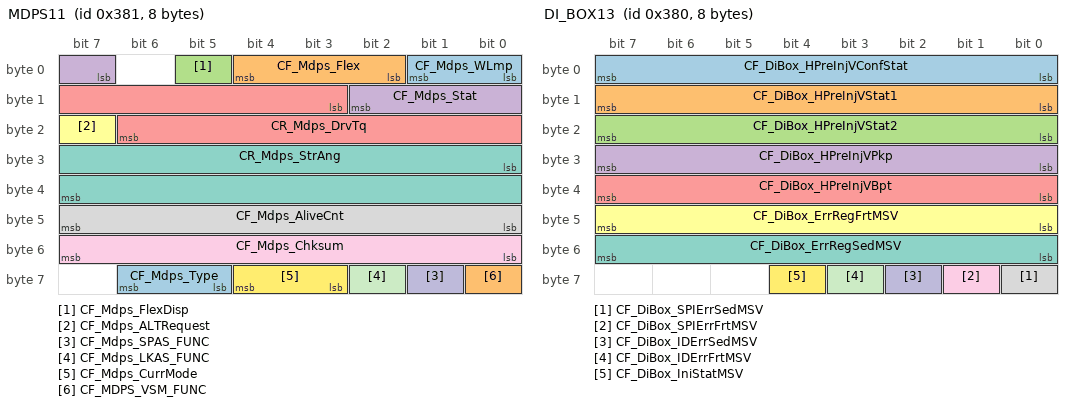
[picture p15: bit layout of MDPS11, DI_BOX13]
BO_ 897 MDPS11: 8 MDPS
 SG_ CF_Mdps_WLmp : 0|2@1+ (1.0,0.0) [0.0|3.0] ""  CLU,CUBIS,EMS,IBOX,SPAS
 SG_ CF_Mdps_Flex : 2|3@1+ (1.0,0.0) [0.0|3.0] ""  CLU,LDWS_LKAS
 SG_ CF_Mdps_FlexDisp : 5|1@1+ (1.0,0.0) [0.0|1.0] ""  CLU
 SG_ CF_Mdps_Stat : 7|4@1+ (1.0,0.0) [0.0|15.0] ""  SPAS
 SG_ CR_Mdps_DrvTq : 11|12@1+ (1.0,-2048.0) [-2048.0|2046.0] ""  SPAS
 SG_ CF_Mdps_ALTRequest : 23|1@1+ (1.0,0.0) [0.0|1.0] ""  EMS
 SG_ CR_Mdps_StrAng : 24|16@1- (0.1,0.0) [-3276.8|3276.7] "Deg"  SPAS
 SG_ CF_Mdps_AliveCnt : 40|8@1+ (1.0,0.0) [0.0|255.0] ""  LDWS_LKAS,SPAS
 SG_ CF_Mdps_Chksum : 48|8@1+ (1.0,0.0) [0.0|255.0] ""  LDWS_LKAS,SPAS
 SG_ CF_Mdps_SPAS_FUNC : 57|1@1+ (1.0,0.0) [0.0|1.0] "flag"  SPAS
 SG_ CF_Mdps_LKAS_FUNC : 58|1@1+ (1.0,0.0) [0.0|1.0] "flag"  LDWS_LKAS
 SG_ CF_Mdps_CurrMode : 59|2@1+ (1.0,0.0) [0.0|3.0] ""  LDWS_LKAS
 SG_ CF_Mdps_Type : 61|2@1+ (1.0,0.0) [0.0|2.0] ""  LDWS_LKAS,SPAS
 SG_ CF_MDPS_VSM_FUNC : 56|1@0+ (1.0,0.0) [0.0|1.0] "" XXX

BO_ 896 DI_BOX13: 8 DI_BOX
 SG_ CF_DiBox_HPreInjVConfStat : 0|8@1+ (1.0,0.0) [0.0|255.0] ""  EMS
 SG_ CF_DiBox_HPreInjVStat1 : 8|8@1+ (1.0,0.0) [0.0|255.0] ""  EMS
 SG_ CF_DiBox_HPreInjVStat2 : 16|8@1+ (1.0,0.0) [0.0|255.0] ""  EMS
 SG_ CF_DiBox_HPreInjVPkp : 24|8@1+ (1.0,0.0) [0.0|255.0] ""  EMS
 SG_ CF_DiBox_HPreInjVBpt : 32|8@1+ (1.0,0.0) [0.0|255.0] ""  EMS
 SG_ CF_DiBox_ErrRegFrtMSV : 40|8@1+ (1.0,0.0) [0.0|255.0] ""  EMS
 SG_ CF_DiBox_ErrRegSedMSV : 48|8@1+ (1.0,0.0) [0.0|255.0] ""  EMS
 SG_ CF_DiBox_SPIErrSedMSV : 56|1@1+ (1.0,0.0) [0.0|1.0] ""  EMS
 SG_ CF_DiBox_SPIErrFrtMSV : 57|1@1+ (1.0,0.0) [0.0|1.0] ""  EMS
 SG_ CF_DiBox_IDErrSedMSV : 58|1@1+ (1.0,0.0) [0.0|1.0] ""  EMS
 SG_ CF_DiBox_IDErrFrtMSV : 59|1@1+ (1.0,0.0) [0.0|1.0] ""  EMS
 SG_ CF_DiBox_IniStatMSV : 60|1@1+ (1.0,0.0) [0.0|1.0] ""  EMS

BO_ 640 EMS13: 8 EMS
 SG_ LV_FUEL_TYPE_ECU : 0|1@1+ (1.0,0.0) [0.0|1.0] ""  BCM,CLU,LPI,SMK
 SG_ LV_BFS_CFIRM : 1|1@1+ (1.0,0.0) [0.0|1.0] ""  LPI
 SG_ LV_CRASH : 2|1@1+ (1.0,0.0) [0.0|1.0] ""  LPI
 SG_ LV_VB_OFF_ACT : 3|1@1+ (1.0,0.0) [0.0|1.0] ""  LPI
 SG_ LV_GSL_MAP M : 4|1@1+ (1.0,0.0) [0.0|1.0] ""  LPI
 SG_ LV_ENG_TURN : 5|1@1+ (1.0,0.0) [0.0|1.0] ""  LPI
 SG_ ERR_FUEL : 8|8@1+ (1.0,0.0) [0.0|255.0] ""  LPI
 SG_ EOS : 16|8@1+ (1.0,0.0) [0.0|255.0] ""  LPI
 SG_ TCO : 24|8@1+ (0.75,-48.0) [-48.0|143.25] "deg"  LPI
 SG_ N_32 : 32|8@1+ (32.0,0.0) [0.0|8160.0] "rpm"  LPI
 SG_ MAF : 40|8@1+ (5.447,0.0) [0.0|1388.985] "mg/TDC"  LPI
 SG_ TIA : 48|8@1+ (0.75,-48.0) [-48.0|143.25] "deg"  LPI
 SG_ MAP m1 : 56|8@1+ (0.47058,0.0) [0.0|119.9979] "kPa"  LPI
 SG_ AMP m0 : 56|8@1+ (21.22,0.0) [0.0|5411.1] "hPa"  LPI

BO_ 128 EMS_DCT11: 8 EMS
 SG_ PV_AV_CAN : 0|8@1+ (0.3906,0.0) [0.0|99.603] "%"  TCU
 SG_ TQ_STND : 8|6@1+ (10.0,0.0) [0.0|630.0] "Nm"  TCU
 SG_ F_N_ENG : 14|1@1+ (1.0,0.0) [0.0|1.0] ""  TCU
 SG_ F_SUB_TQI : 15|1@1+ (1.0,0.0) [0.0|1.0] ""  TCU
 SG_ N : 16|16@1+ (0.25,0.0) [0.0|16383.75] "rpm"  TCU
 SG_ TQI_ACOR : 32|8@1+ (0.390625,0.0) [0.0|99.6094] "%"  IBOX,TCU
 SG_ TQFR : 40|8@1+ (0.390625,0.0) [0.0|99.6094] "%"  TCU
 SG_ TQI : 48|8@1+ (0.390625,0.0) [0.0|99.609375] "%"  TCU
 SG_ CF_Ems_Alive : 56|4@1+ (1.0,0.0) [0.0|15.0] ""  TCU
 SG_ CF_Ems_ChkSum : 60|4@1+ (1.0,0.0) [0.0|15.0] ""  TCU

BO_ 1407 HU_MON_PE_01: 8 CLU
 SG_ HU_Type : 0|8@1+ (1.0,0.0) [0.0|255.0] ""  AVM,PGS

BO_ 127 CGW5: 8 BCM
 SG_ C_StopLampLhOpenSts : 0|1@1+ (1.0,0.0) [0.0|1.0] ""  CLU
 SG_ C_StopLampRhOpenSts : 1|1@1+ (1.0,0.0) [0.0|1.0] ""  CLU
 SG_ C_HMSLOpenSts : 2|1@1+ (1.0,0.0) [0.0|1.0] ""  CLU
 SG_ C_HLampLowLhOpenSts : 3|1@1+ (1.0,0.0) [0.0|1.0] ""  CLU
 SG_ C_HLampLowRhOpenSts : 4|1@1+ (1.0,0.0) [0.0|1.0] ""  CLU
 SG_ C_HLampHighLhOpenSts : 5|1@1+ (1.0,0.0) [0.0|1.0] ""  CLU
 SG_ C_HLampHighRhOpenSts : 6|1@1+ (1.0,0.0) [0.0|1.0] ""  CLU
 SG_ C_DRLLampLhOpenSts : 7|1@1+ (1.0,0.0) [0.0|1.0] ""  CLU
 SG_ C_DRLLampRhOpenSts : 8|1@1+ (1.0,0.0) [0.0|1.0] ""  CLU
 SG_ C_RearFOGLhOpenSts : 9|1@1+ (1.0,0.0) [0.0|1.0] ""  CLU
 SG_ C_RearFOGRhOpenSts : 10|1@1+ (1.0,0.0) [0.0|1.0] ""  CLU
 SG_ C_FrontFOGLhOpenSts : 11|1@1+ (1.0,0.0) [0.0|1.0] ""  CLU
 SG_ C_FrontFOGRhOpenSts : 12|1@1+ (1.0,0.0) [0.0|1.0] ""  CLU
 SG_ C_RearEXTTailLhOpenSts : 13|1@1+ (1.0,0.0) [0.0|1.0] ""  CLU
 SG_ C_RearEXTTailRhOpenSts : 14|1@1+ (1.0,0.0) [0.0|1.0] ""  CLU
 SG_ C_FrontEXTTailLhOpenSts : 15|1@1+ (1.0,0.0) [0.0|1.0] ""  CLU
 SG_ C_FrontEXTTailRhOpenSts : 16|1@1+ (1.0,0.0) [0.0|1.0] ""  CLU
 SG_ C_RearTSIGLhOpenSts : 17|1@1+ (1.0,0.0) [0.0|1.0] ""  CLU
 SG_ C_RearTSIGRhOpenSts : 18|1@1+ (1.0,0.0) [0.0|1.0] ""  CLU
 SG_ C_FrontTSIGLhOpenSts : 19|1@1+ (1.0,0.0) [0.0|1.0] ""  CLU
 SG_ C_FrontTSIGRhOpenSts : 20|1@1+ (1.0,0.0) [0.0|1.0] ""  CLU
 SG_ C_SBendingLhOpenSts : 21|1@1+ (1.0,0.0) [0.0|1.0] ""  CLU
 SG_ C_SBendingRhOpenSts : 22|1@1+ (1.0,0.0) [0.0|1.0] ""  CLU
 SG_ C_LicensePlateLhOpenSts : 23|1@1+ (1.0,0.0) [0.0|1.0] ""  CLU
 SG_ C_LicensePlateRhOpenSts : 24|1@1+ (1.0,0.0) [0.0|1.0] ""  CLU

BO_ 354 TCU_DCT13: 3 TCU
 SG_ Clutch_Driving_Tq : 0|10@1+ (1.0,-512.0) [0.0|0.0] "Nm"  ESC
 SG_ Cluster_Engine_RPM : 10|13@1+ (0.9766,0.0) [0.0|0.0] ""  CLU
 SG_ Cluster_Engine_RPM_Flag : 23|1@1+ (1.0,0.0) [0.0|0.0] ""  CLU

BS_:

BU_: XXX CAMERA FRONT_RADAR ADRV APRK

BO_ 353 MSG_161: 32 CCNC
 SG_ CHECKSUM : 0|16@1+ (1,0) [0|65535] "" XXX
 SG_ COUNTER : 16|8@1+ (1,0) [0|255] "" XXX
 SG_ FCA_ICON : 24|3@1+ (1,0) [0|7] "" XXX
 SG_ FCA_ALT_ICON : 27|3@1+ (1,0) [0|7] "" XXX
 SG_ LKA_ICON : 30|3@1+ (1,0) [0|3] "" XXX
 SG_ HBA_ICON : 33|3@1+ (1,0) [0|7] "" XXX
 SG_ ZEROS_1 : 36|4@1+ (1,0) [0|15] "" XXX
 SG_ ZEROS_2 : 40|2@1+ (1,0) [0|3] "" XXX
 SG_ FCA_IMAGE : 42|3@1+ (1,0) [0|7] "" XXX
 SG_ ZEROS_3 : 45|3@1+ (1,0) [0|7] "" XXX
 SG_ ZEROS_4 : 48|3@1+ (1,0) [0|7] "" XXX
 SG_ BCA_LEFT : 51|3@1+ (1,0) [0|7] "" XXX
 SG_ BCA_RIGHT : 54|3@1+ (1,0) [0|7] "" XXX
 SG_ LCA_LEFT_ARROW : 57|3@1+ (1,0) [0|7] "" XXX
 SG_ LCA_RIGHT_ARROW : 60|3@1+ (1,0) [0|7] "" XXX
 SG_ ZEROS_5 : 63|1@0+ (1,0) [0|1] "" XXX
 SG_ CENTERLINE : 64|2@1+ (1,0) [0|3] "" XXX
 SG_ TARGET : 66|3@1+ (1,0) [0|7] "" XXX
 SG_ TARGET_POSITION : 69|11@1+ (1,0) [0|7] "" XXX
 SG_ LANELINE_LEFT : 80|4@1+ (1,0) [0|15] "" XXX
 SG_ LANELINE_LEFT_POSITION : 84|6@1+ (1,0) [0|15] "" XXX
 SG_ LANELINE_RIGHT : 90|4@1+ (1,0) [0|15] "" XXX
 SG_ LANELINE_RIGHT_POSITION : 94|6@1+ (1,0) [0|3] "" XXX
 SG_ LANELINE_CURVATURE : 100|5@1- (1,15) [0|31] "" XXX
 SG_ LANE_HIGHLIGHT : 105|4@1+ (1,0) [0|15] "" XXX
 SG_ LANE_HIGHLIGHT_DISTANCE : 109|11@1+ (1,0) [0|7] "" XXX
 SG_ LANE_LEFT : 120|3@1+ (1,0) [0|7] "" XXX
 SG_ LANE_RIGHT : 123|3@1+ (1,0) [0|7] "" XXX
 SG_ LANE_ZOOM : 126|2@1+ (1,0) [0|3] "" XXX
 SG_ ALERTS_1 : 128|6@1+ (1,0) [0|63] "" XXX
 SG_ ALERTS_2 : 134|5@1+ (1,0) [0|3] "" XXX
 SG_ ALERTS_3 : 139|4@1+ (1,0) [0|15] "" XXX
 SG_ ALERTS_4 : 143|9@1+ (1,0) [0|511] "" XXX
 SG_ ALERTS_5 : 152|5@1+ (1,0) [0|7] "" XXX
 SG_ MUTE : 157|3@1+ (1,0) [0|7] "" XXX
 SG_ SOUNDS_1 : 160|4@1+ (1,0) [0|3] "" XXX
 SG_ SOUNDS_2 : 164|4@1+ (1,0) [0|3] "" XXX
 SG_ SOUNDS_3 : 168|4@1+ (1,0) [0|15] "" XXX
 SG_ SOUNDS_4 : 172|3@1+ (1,0) [0|7] "" XXX
 SG_ ZEROS_6 : 175|1@0+ (1,0) [0|1] "" XXX
 SG_ ZEROS_7 : 176|5@1+ (1,0) [0|31] "" XXX
 SG_ SETSPEED_HUD : 181|3@1+ (1,0) [0|3] "" XXX
 SG_ DISTANCE_LEAD : 184|5@1+ (1,0) [0|31] "" XXX
 SG_ DISTANCE_CAR : 189|3@1+ (1,0) [0|7] "" XXX
 SG_ DISTANCE_SPACING : 192|4@1+ (1,0) [0|15] "" XXX
 SG_ DISTANCE : 196|4@1+ (1,0) [0|7] "" XXX
 SG_ SETSPEED_SPEED : 200|8@1+ (1,0) [0|255] "" XXX
 SG_ SETSPEED : 208|4@1+ (1,0) [0|3] "" XXX
 SG_ HDA_ICON : 212|4@1+ (1,0) [0|3] "" XXX
 SG_ SLA_ICON : 216|4@1+ (1,0) [0|15] "" XXX
 SG_ NAV_ICON : 220|4@1+ (1,0) [0|3] "" XXX
 SG_ LFA_ICON : 224|4@1+ (1,0) [0|3] "" XXX
 SG_ LCA_LEFT_ICON : 228|4@1+ (1,0) [0|15] "" XXX
 SG_ LCA_RIGHT_ICON : 232|4@1+ (1,0) [0|15] "" XXX
 SG_ BACKGROUND : 236|4@1+ (1,0) [0|15] "" XXX
 SG_ DAW_ICON : 240|3@1+ (1,0) [0|7] "" XXX
 SG_ CAR_CIRCLE : 243|3@1+ (1,0) [0|7] "" XXX
 SG_ ZEROS_8 : 246|2@1+ (1,0) [0|3] "" XXX
 SG_ ZEROS_9 : 248|8@1+ (1,0) [0|255] "" XXX

BO_ 354 MSG_162: 32 CCNC
 SG_ CHECKSUM : 0|16@1+ (1,0) [0|65535] "" XXX
 SG_ COUNTER : 16|8@1+ (1,0) [0|255] "" XXX
 SG_ SPEEDLIMIT_STYLE : 24|4@1+ (1,0) [0|7] "" XXX
 SG_ SPEEDLIMIT_FLASH : 28|4@1+ (1,0) [0|15] "" XXX
 SG_ SPEEDLIMIT : 32|8@1+ (1,0) [0|255] "" XXX
 SG_ SIGNS : 40|8@1+ (1,0) [0|15] "" XXX
 SG_ SPEEDLIMIT_WEATHER : 48|4@1+ (1,0) [0|15] "" XXX
 SG_ VIBRATE : 52|3@1+ (1,0) [0|7] "" XXX
 SG_ ZEROS_1 : 55|1@0+ (1,0) [0|1] "" XXX
 SG_ ZEROS_2 : 56|8@1+ (1,0) [0|255] "" XXX
 SG_ LEAD : 64|5@1+ (1,0) [0|31] "" XXX
 SG_ LEAD_DISTANCE : 69|11@1+ (1,0) [0|2047] "" XXX
 SG_ LEAD_LATERAL : 80|7@1+ (1,0) [0|127] "" XXX
 SG_ ZEROS_3 : 87|1@0+ (1,0) [0|1] "" XXX
 SG_ LEAD_ALT : 88|5@1+ (1,0) [0|31] "" XXX
 SG_ LEAD_ALT_DISTANCE : 93|11@1+ (1,0) [0|2047] "" XXX
 SG_ LEAD_ALT_LATERAL : 104|7@1+ (1,0) [0|127] "" XXX
 SG_ ZEROS_4 : 111|1@0+ (1,0) [0|1] "" XXX
 SG_ LEAD_LEFT : 112|5@1+ (1,0) [0|31] "" XXX
 SG_ LEAD_LEFT_DISTANCE : 117|11@1+ (1,0) [0|2047] "" XXX
 SG_ LEAD_LEFT_LATERAL : 128|7@1+ (1,0) [0|127] "" XXX
 SG_ ZEROS_5 : 135|1@0+ (1,0) [0|1] "" XXX
 SG_ LEAD_RIGHT : 136|5@1+ (1,0) [0|31] "" XXX
 SG_ LEAD_RIGHT_DISTANCE : 141|11@1+ (1,0) [0|2047] "" XXX
 SG_ LEAD_RIGHT_LATERAL : 152|7@1+ (1,0) [0|127] "" XXX
 SG_ ZEROS_6 : 159|1@0+ (1,0) [0|1] "" XXX
 SG_ ZEROS_7 : 160|8@1+ (1,0) [0|255] "" XXX
 SG_ ZEROS_8 : 168|8@1+ (1,0) [0|255] "" XXX
 SG_ ZEROS_9 : 176|8@1+ (1,0) [0|255] "" XXX
 SG_ ZEROS_10 : 184|8@1+ (1,0) [0|255] "" XXX
 SG_ ZEROS_11 : 192|8@1+ (1,0) [0|255] "" XXX
 SG_ ZEROS_12 : 200|8@1+ (1,0) [0|255] "" XXX
 SG_ ZEROS_13 : 208|5@1+ (1,0) [0|31] "" XXX
 SG_ FAULT_FSS : 213|3@1+ (1,0) [0|7] "" XXX
 SG_ FAULT_FCA : 216|3@1+ (1,0) [0|7] "" XXX
 SG_ FAULT_LSS : 219|3@1+ (1,0) [0|7] "" XXX
 SG_ FAULT_SLA : 222|3@1+ (1,0) [0|7] "" XXX
 SG_ FAULT_DAW : 225|3@1+ (1,0) [0|7] "" XXX
 SG_ FAULT_HBA : 228|3@1+ (1,0) [0|7] "" XXX
 SG_ FAULT_SCC : 231|3@1+ (1,0) [0|7] "" XXX
 SG_ FAULT_LFA : 234|3@1+ (1,0) [0|7] "" XXX
 SG_ FAULT_HDA : 237|3@1+ (1,0) [0|7] "" XXX
 SG_ FAULT_LCA : 240|3@1+ (1,0) [0|7] "" XXX
 SG_ FAULT_HDP : 243|3@1+ (1,0) [0|7] "" XXX
 SG_ FAULT_DAS : 246|3@1+ (1,0) [0|7] "" XXX
 SG_ FAULT_ESS : 249|3@1+ (1,0) [0|7] "" XXX
 SG_ ZEROS_14 : 252|4@1+ (1,0) [0|15] "" XXX

BS_:

BU_: IAP ODS _4WD BCM HUD DATC MDPS AAF_Tester AEMC SMK _4WD EPB CUBIS MTS TMU EVP CGW TPMS LPI DI_BOX SPAS EMS LCA TCU IBOX FATC AFLS FPCM SCC AHLS AVM ABS SNV OPI PGS SAS AAF Dummy LDWS_LKAS LVR ESC PSB CLU ECS ACU REA

BO_ 1532 ODS13: 5 ODS
 SG_ CR_Ods_ID : 0|8@1+ (1.0,0.0) [0.0|255.0] ""  ACU
 SG_ CR_Ods_Chksum_H : 8|8@1+ (1.0,0.0) [0.0|255.0] ""  Dummy
 SG_ CR_Ods_Chksum_L : 16|8@1+ (1.0,0.0) [0.0|255.0] ""  Dummy
 SG_ CR_Ods_RomID_H : 24|8@1+ (1.0,0.0) [0.0|255.0] ""  Dummy
 SG_ CR_Ods_RomID_L : 32|8@1+ (1.0,0.0) [0.0|255.0] ""  Dummy

BO_ 1531 ODS12: 8 ODS
 SG_ CR_Ods_SerNum0 : 0|8@1+ (1.0,0.0) [0.0|255.0] ""  ACU
 SG_ CR_Ods_SerNum1 : 8|8@1+ (1.0,0.0) [0.0|255.0] ""  ACU
 SG_ CR_Ods_SerNum2 : 16|8@1+ (1.0,0.0) [0.0|255.0] ""  ACU
 SG_ CR_Ods_SerNum3 : 24|8@1+ (1.0,0.0) [0.0|255.0] ""  ACU
 SG_ CR_Ods_SerNum4 : 32|8@1+ (1.0,0.0) [0.0|255.0] ""  ACU
 SG_ CR_Ods_SerNum5 : 40|8@1+ (1.0,0.0) [0.0|255.0] ""  ACU
 SG_ CR_Ods_SerNum6 : 48|8@1+ (1.0,0.0) [0.0|255.0] ""  ACU
 SG_ CR_Ods_SerNum7 : 56|8@1+ (1.0,0.0) [0.0|255.0] ""  ACU

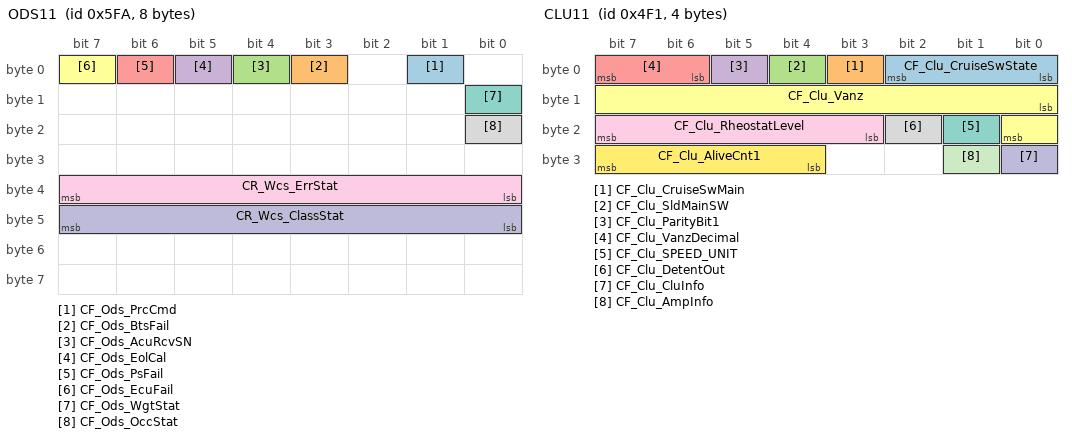
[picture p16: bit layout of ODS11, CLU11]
BO_ 1530 ODS11: 8 ODS
 SG_ CF_Ods_PrcCmd : 1|1@1+ (1.0,0.0) [0.0|1.0] ""  Dummy
 SG_ CF_Ods_BtsFail : 3|1@1+ (1.0,0.0) [0.0|1.0] ""  Dummy
 SG_ CF_Ods_AcuRcvSN : 4|1@1+ (1.0,0.0) [0.0|1.0] ""  ACU
 SG_ CF_Ods_EolCal : 5|1@1+ (1.0,0.0) [0.0|1.0] ""  ACU
 SG_ CF_Ods_PsFail : 6|1@1+ (1.0,0.0) [0.0|1.0] ""  ACU
 SG_ CF_Ods_EcuFail : 7|1@1+ (1.0,0.0) [0.0|1.0] ""  ACU
 SG_ CF_Ods_WgtStat : 8|1@1+ (1.0,0.0) [0.0|1.0] ""  ACU
 SG_ CF_Ods_OccStat : 16|1@1+ (1.0,0.0) [0.0|1.0] ""  ACU
 SG_ CR_Wcs_ErrStat : 32|8@1+ (1.0,0.0) [0.0|63.0] ""  ACU
 SG_ CR_Wcs_ClassStat : 40|8@1+ (1.0,0.0) [0.0|4.0] ""  ACU,BCM

BO_ 1017 ECS12: 4 ECS
 SG_ Height_FL : 0|8@1+ (1.0,-128.0) [-128.0|127.0] "mm"  AFLS
 SG_ Height_FR : 8|8@1+ (1.0,-128.0) [-128.0|127.0] "mm"  AFLS
 SG_ Height_RL : 16|8@1+ (1.0,-128.0) [-128.0|127.0] "mm"  AFLS
 SG_ Height_RR : 24|8@1+ (1.0,-128.0) [-128.0|127.0] "mm"  AFLS

BO_ 1268 SPAS12: 8 SPAS
 SG_ CF_Spas_HMI_Stat : 0|8@1+ (1.0,0.0) [0.0|255.0] ""  CLU
 SG_ CF_Spas_Disp : 8|2@1+ (1.0,0.0) [0.0|3.0] ""  CLU,EMS
 SG_ CF_Spas_FIL_Ind : 10|3@1+ (1.0,0.0) [0.0|7.0] ""  AVM,CLU
 SG_ CF_Spas_FIR_Ind : 13|3@1+ (1.0,0.0) [0.0|7.0] ""  AVM,CLU
 SG_ CF_Spas_FOL_Ind : 16|3@1+ (1.0,0.0) [0.0|7.0] ""  AVM,CLU
 SG_ CF_Spas_FOR_Ind : 19|3@1+ (1.0,0.0) [0.0|7.0] ""  AVM,CLU
 SG_ CF_Spas_VolDown : 22|2@1+ (1.0,0.0) [0.0|3.0] ""  CLU
 SG_ CF_Spas_RIL_Ind : 24|3@1+ (1.0,0.0) [0.0|7.0] ""  AVM,CLU
 SG_ CF_Spas_RIR_Ind : 27|3@1+ (1.0,0.0) [0.0|7.0] ""  AVM,CLU
 SG_ CF_Spas_FLS_Alarm : 30|2@1+ (1.0,0.0) [0.0|3.0] ""  CLU
 SG_ CF_Spas_ROL_Ind : 32|3@1+ (1.0,0.0) [0.0|7.0] ""  AVM,CLU
 SG_ CF_Spas_ROR_Ind : 35|3@1+ (1.0,0.0) [0.0|7.0] ""  AVM,CLU
 SG_ CF_Spas_FCS_Alarm : 38|2@1+ (1.0,0.0) [0.0|3.0] ""  CLU
 SG_ CF_Spas_FI_Ind : 40|3@1+ (1.0,0.0) [0.0|7.0] ""  AVM,CLU
 SG_ CF_Spas_RI_Ind : 43|3@1+ (1.0,0.0) [0.0|7.0] ""  AVM,CLU
 SG_ CF_Spas_FRS_Alarm : 46|2@1+ (1.0,0.0) [0.0|3.0] ""  CLU
 SG_ CF_Spas_FR_Alarm : 48|2@1+ (1.0,0.0) [0.0|3.0] ""  BCM,CLU
 SG_ CF_Spas_RR_Alarm : 50|2@1+ (1.0,0.0) [0.0|3.0] ""  BCM,CLU
 SG_ CF_Spas_BEEP_Alarm : 52|4@1+ (1.0,0.0) [0.0|15.0] ""  BCM,CLU
 SG_ CF_Spas_StatAlarm : 56|1@1+ (1.0,0.0) [0.0|1.0] ""  CLU
 SG_ CF_Spas_RLS_Alarm : 57|2@1+ (1.0,0.0) [0.0|3.0] ""  CLU
 SG_ CF_Spas_RCS_Alarm : 59|2@1+ (1.0,0.0) [0.0|3.0] ""  CLU
 SG_ CF_Spas_RRS_Alarm : 61|2@1+ (1.0,0.0) [0.0|3.0] ""  CLU

BO_ 1265 CLU11: 4 CLU
 SG_ CF_Clu_CruiseSwState : 0|3@1+ (1.0,0.0) [0.0|7.0] ""  EMS,LDWS_LKAS,SCC
 SG_ CF_Clu_CruiseSwMain : 3|1@1+ (1.0,0.0) [0.0|1.0] ""  EMS,LDWS_LKAS,SCC
 SG_ CF_Clu_SldMainSW : 4|1@1+ (1.0,0.0) [0.0|1.0] ""  EMS
 SG_ CF_Clu_ParityBit1 : 5|1@1+ (1.0,0.0) [0.0|1.0] "pulse count"  EMS
 SG_ CF_Clu_VanzDecimal : 6|2@1+ (0.125,0.0) [0.0|0.375] ""  EMS
 SG_ CF_Clu_Vanz : 8|9@1+ (0.5,0.0) [0.0|255.5] "km/h or MPH"  BCM,CUBIS,EMS,IBOX,LDWS_LKAS,MDPS,SCC
 SG_ CF_Clu_SPEED_UNIT : 17|1@1+ (1.0,0.0) [0.0|1.0] ""  BCM,CUBIS,EMS,IBOX,LDWS_LKAS,MDPS,SCC
 SG_ CF_Clu_DetentOut : 18|1@1+ (1.0,0.0) [0.0|1.0] ""  AVM,BCM,LCA,PGS,SPAS
 SG_ CF_Clu_RheostatLevel : 19|5@1+ (1.0,0.0) [0.0|31.0] ""  AVM,BCM,LCA,PGS,SPAS
 SG_ CF_Clu_CluInfo : 24|1@1+ (1.0,0.0) [0.0|1.0] ""  BCM
 SG_ CF_Clu_AmpInfo : 25|1@1+ (1.0,0.0) [0.0|1.0] ""  BCM
 SG_ CF_Clu_AliveCnt1 : 28|4@1+ (1.0,0.0) [0.0|15.0] ""  AHLS,EMS,EPB,LDWS_LKAS,MDPS,SCC

BO_ 1260 Sign_Detection: 8 XXX
 SG_ SpeedLim_Nav_Cam : 40|8@1+ (1,0) [0|255] "km/h / mph" XXX
 SG_ SpeedLim_Nav_Cam2 : 48|8@1+ (1,0) [0|255] "km/h / mph" XXX

BO_ 1492 TMU_GW_PE_01: 8 CLU
 SG_ TMU_IVRActivity : 0|2@1+ (1.0,0.0) [0.0|3.0] ""  DATC
 SG_ TMU_PhoneActivity : 2|2@1+ (1.0,0.0) [0.0|3.0] ""  DATC

BO_ 1491 HU_DATC_PE_00: 8 CLU
 SG_ HU_VRActivity : 0|2@1+ (1.0,0.0) [0.0|3.0] ""  DATC
 SG_ HU_PhoneActivity : 2|2@1+ (1.0,0.0) [0.0|3.0] ""  DATC
 SG_ BlowerNoiseControl : 4|2@1+ (1.0,0.0) [0.0|3.0] ""  DATC

BO_ 1490 HU_DATC_E_02: 8 CLU
 SG_ HU_DATC_RearOnOffSet : 6|2@1+ (1.0,0.0) [0.0|3.0] ""  DATC
 SG_ HU_DATC_ADSOnOffSet : 8|2@1+ (1.0,0.0) [0.0|3.0] ""  DATC

BO_ 1479 EMS21: 8 EMS
 SG_ SCR_LEVEL_WARN_LAMP : 0|1@1+ (1.0,0.0) [0.0|1.0] ""  CLU
 SG_ SCR_LEVEL_WARN : 1|3@1+ (1.0,0.0) [0.0|4.0] ""  CLU
 SG_ SCR_SYS_ERROR_WARN : 4|3@1+ (1.0,0.0) [0.0|7.0] ""  CLU
 SG_ SCR_SYSTEM_WARN_LAMP : 7|1@1+ (1.0,0.0) [0.0|1.0] ""  CLU
 SG_ SCR_INDUCEMENT_EXIT_COND : 8|2@1+ (1.0,0.0) [0.0|3.0] ""  CLU
 SG_ SCR_UREA_LEVEL : 16|8@1+ (0.5,0.0) [0.0|100.0] "%"  CLU
 SG_ SCR_NO_REMAINING_RESTARTS : 24|8@1+ (1.0,0.0) [0.0|255.0] ""  CLU
 SG_ SCR_REMAINING_DISTANCE : 32|16@1+ (1.0,0.0) [0.0|25000.0] "km"  CLU

BO_ 1472 GW_Warning_PE: 8 BCM
 SG_ Audio_VolumeDown : 38|2@1+ (1.0,0.0) [0.0|3.0] ""  CLU
 SG_ Pas_Spkr_Flh_Alarm : 48|2@1+ (1.0,0.0) [0.0|3.0] ""  CLU
 SG_ Pas_Spkr_Fcnt_Alarm : 50|2@1+ (1.0,0.0) [0.0|3.0] ""  CLU
 SG_ Pas_Spkr_Frh_Alarm : 52|2@1+ (1.0,0.0) [0.0|3.0] ""  CLU
 SG_ Pas_Spkr_Rlh_Alarm : 56|2@1+ (1.0,0.0) [0.0|3.0] ""  CLU,PGS
 SG_ Pas_Spkr_Rcnt_Alarm : 58|2@1+ (1.0,0.0) [0.0|3.0] ""  CLU
 SG_ Pas_Spkr_Rrh_Alarm : 60|2@1+ (1.0,0.0) [0.0|3.0] ""  CLU,PGS

BO_ 1984 CAL_SAS11: 2 ESC
 SG_ CCW : 0|4@1+ (1.0,0.0) [0.0|15.0] ""  SAS
 SG_ SAS_CID : 4|11@1+ (1.0,0.0) [0.0|2047.0] ""  SAS

BO_ 1456 CLU12: 4 CLU
 SG_ CF_Clu_Odometer : 0|24@1+ (0.1,0.0) [0.0|1677721.4] "km"  _4WD,AAF,BCM,CUBIS,EMS,EPB,IBOX,LDWS_LKAS,SCC,TPMS

BO_ 688 SAS11: 5 MDPS
 SG_ SAS_Angle : 0|16@1- (0.1,0.0) [-3276.8|3276.7] "Deg"  _4WD,ACU,AFLS,AVM,CLU,ECS,EMS,ESC,IBOX,LCA,LDWS_LKAS,PGS,PSB,SCC,SPAS,TCU,_4WD,ACU,AFLS,AVM,BCM,CLU,ECS,EMS,ESC,IBOX,LCA,LDWS_LKAS,PGS,PSB,SCC,SPAS,TCU
 SG_ SAS_Speed : 16|8@1+ (4.0,0.0) [0.0|1016.0] ""  AFLS,ECS,ESC,IBOX,LDWS_LKAS,SCC,SPAS,TCU,AFLS,ECS,ESC,IBOX,LDWS_LKAS,SCC,SPAS,TCU
 SG_ SAS_Stat : 24|8@1+ (1.0,0.0) [0.0|255.0] ""  ECS,ESC,IBOX,LDWS_LKAS,PSB,SCC,SPAS,TCU,ECS,ESC,IBOX,LDWS_LKAS,PSB,SCC,SPAS,TCU
 SG_ MsgCount : 32|4@1+ (1.0,0.0) [0.0|15.0] ""  ECS,ESC,IBOX,LDWS_LKAS,PSB,SCC,SPAS,ECS,ESC,IBOX,LDWS_LKAS,PSB,SCC,SPAS
 SG_ CheckSum : 36|4@1+ (1.0,0.0) [0.0|15.0] ""  ECS,EMS,ESC,IBOX,LDWS_LKAS,PSB,SCC,SPAS,ECS,EMS,ESC,IBOX,LDWS_LKAS,PSB,SCC,SPAS

BO_ 1441 ACU12: 8 ACU
 SG_ CR_Acu_SN : 0|64@1+ (1.0,0.0) [0.0|0.0] ""  ODS

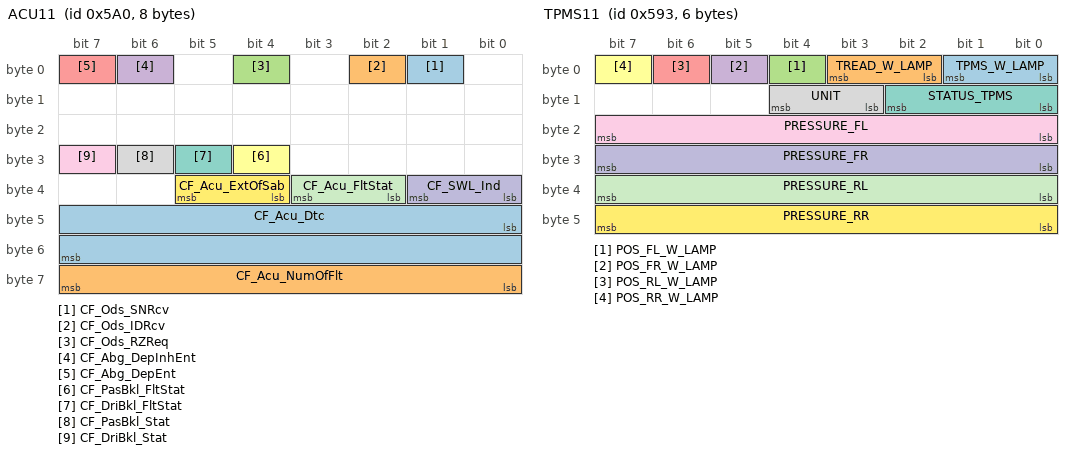
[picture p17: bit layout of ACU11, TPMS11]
BO_ 1440 ACU11: 8 ACU
 SG_ CF_Ods_SNRcv : 1|1@1+ (1.0,0.0) [0.0|1.0] ""  ODS
 SG_ CF_Ods_IDRcv : 2|1@1+ (1.0,0.0) [0.0|1.0] ""  ODS
 SG_ CF_Ods_RZReq : 4|1@1+ (1.0,0.0) [0.0|1.0] ""  ODS
 SG_ CF_Abg_DepInhEnt : 6|1@1+ (1.0,0.0) [0.0|1.0] ""  ODS
 SG_ CF_Abg_DepEnt : 7|1@1+ (1.0,0.0) [0.0|1.0] ""  ODS
 SG_ CF_PasBkl_FltStat : 28|1@1+ (1.0,0.0) [0.0|1.0] ""  ODS,PSB
 SG_ CF_DriBkl_FltStat : 29|1@1+ (1.0,0.0) [0.0|1.0] ""  ODS,PSB
 SG_ CF_PasBkl_Stat : 30|1@1+ (1.0,0.0) [0.0|1.0] ""  IBOX,ODS,PSB,TMU
 SG_ CF_DriBkl_Stat : 31|1@1+ (1.0,0.0) [0.0|1.0] ""  ODS,PSB
 SG_ CF_SWL_Ind : 32|2@1+ (1.0,0.0) [0.0|3.0] ""  CUBIS,IBOX
 SG_ CF_Acu_FltStat : 34|2@1+ (1.0,0.0) [0.0|3.0] ""  CUBIS,IBOX
 SG_ CF_Acu_ExtOfSab : 36|2@1+ (1.0,0.0) [0.0|3.0] ""  BCM,CLU,CUBIS,IBOX
 SG_ CF_Acu_Dtc : 40|16@1+ (1.0,0.0) [0.0|65535.0] ""  CUBIS,IBOX
 SG_ CF_Acu_NumOfFlt : 56|8@1+ (1.0,0.0) [0.0|255.0] ""  CUBIS,IBOX

BO_ 1437 AHLS11: 8 AHLS
 SG_ CF_Ahls_WarnLamp : 0|2@1+ (1.0,0.0) [0.0|3.0] ""  CLU
 SG_ CF_Ahls_WarnMsg : 2|2@1+ (1.0,0.0) [0.0|3.0] ""  CLU

BO_ 1434 PSB11: 2 PSB
 SG_ PSB_LH_FAIL : 0|2@1+ (1.0,0.0) [0.0|3.0] ""  CLU
 SG_ PSB_LH_TGL : 2|1@1+ (1.0,0.0) [0.0|1.0] ""  CLU
 SG_ PSB_LH_ACT : 3|4@1+ (1.0,0.0) [0.0|4.0] ""  Dummy
 SG_ PSB_RH_FAIL : 8|2@1+ (1.0,0.0) [0.0|3.0] ""  CLU
 SG_ PSB_RH_TGL : 10|1@1+ (1.0,0.0) [0.0|1.0] ""  CLU
 SG_ PSB_RH_ACT : 11|4@1+ (1.0,0.0) [0.0|4.0] ""  Dummy

BO_ 916 TCS13: 8 ESC
 SG_ aBasis : 0|11@1+ (0.01,-10.23) [-10.23|10.24] "m/s^2"  EMS,SCC
 SG_ BrakeLight : 11|1@1+ (1.0,0.0) [0.0|1.0] ""  CLU,EMS,SCC
 SG_ DCEnable : 12|1@1+ (1.0,0.0) [0.0|1.0] ""  EMS,SCC
 SG_ AliveCounterTCS : 13|3@1+ (1.0,0.0) [0.0|7.0] ""  EMS,SCC
 SG_ Pre_TCS_CTL : 16|1@1+ (1.0,0.0) [0.0|1.0] ""  Vector__XXX
 SG_ EBA_ACK : 17|1@1+ (1.0,0.0) [0.0|1.0] ""  Vector__XXX
 SG_ FCA_ACK : 18|1@1+ (1.0,0.0) [0.0|1.0] ""  Vector__XXX
 SG_ DF_BF_STAT : 19|2@1+ (1.0,0.0) [0.0|3.0] ""  BCW
 SG_ SCCReqLim : 22|2@1+ (1.0,0.0) [0.0|3.0] ""  SCC
 SG_ TQI_SCC : 24|8@1+ (0.390625,0.0) [0.0|199.609375] "%"  Vector__XXX
 SG_ ACCEL_REF_ACC : 32|11@1+ (0.01,-10.23) [-10.23|10.24] "m/s^2"  EMS,SCC
 SG_ ACCEnable : 43|2@1+ (1.0,0.0) [0.0|3.0] ""  EMS,SCC
 SG_ DriverOverride : 45|2@1+ (1.0,0.0) [0.0|3.0] ""  EMS,SCC
 SG_ StandStill : 47|1@1+ (1.0,0.0) [0.0|1.0] ""  EMS,SCC
 SG_ CheckSum_TCS3 : 48|4@1+ (1.0,0.0) [0.0|15.0] ""  EMS,SCC
 SG_ ACC_EQUIP : 52|1@1+ (1.0,0.0) [0.0|1.0] ""  EMS,SCC
 SG_ PBRAKE_ACT : 53|1@1+ (1.0,0.0) [0.0|1.0] ""  EMS,SCC
 SG_ ACC_REQ : 54|1@1+ (1.0,0.0) [0.0|1.0] ""  EMS
 SG_ DriverBraking : 55|1@1+ (1.0,0.0) [0.0|1.0] ""  EMS,SCC
 SG_ CF_VSM_Coded : 56|1@1+ (1.0,0.0) [0.0|1.0] ""  SCC
 SG_ CF_VSM_Avail : 57|2@1+ (1.0,0.0) [0.0|3.0] ""  CLU,SCC
 SG_ CF_VSM_Handshake : 59|1@1+ (1.0,0.0) [0.0|1.0] ""  SCC
 SG_ CF_DriBkeStat : 60|1@1+ (1.0,0.0) [0.0|1.0] ""  SCC
 SG_ CF_VSM_ConfSwi : 61|2@1+ (1.0,0.0) [0.0|3.0] ""  SCC
 SG_ AEB_EQUIP : 63|1@1+ (1.0,0.0) [0.0|1.0] ""  SCC

BO_ 1427 TPMS11: 6 BCM
 SG_ TPMS_W_LAMP : 0|2@1+ (1.0,0.0) [0.0|3.0] ""  CLU,CUBIS,HUD,IBOX,CLU,CUBIS,HUD,IBOX
 SG_ TREAD_W_LAMP : 2|2@1+ (1.0,0.0) [0.0|3.0] ""  CLU,CUBIS,HUD,IBOX,CLU,CUBIS,HUD,IBOX
 SG_ POS_FL_W_LAMP : 4|1@1+ (1.0,0.0) [0.0|1.0] ""  CLU,CUBIS,HUD,IBOX
 SG_ POS_FR_W_LAMP : 5|1@1+ (1.0,0.0) [0.0|1.0] ""  CLU,CUBIS,HUD,IBOX
 SG_ POS_RL_W_LAMP : 6|1@1+ (1.0,0.0) [0.0|1.0] ""  CLU,CUBIS,HUD,IBOX
 SG_ POS_RR_W_LAMP : 7|1@1+ (1.0,0.0) [0.0|1.0] ""  CLU,CUBIS,HUD,IBOX
 SG_ STATUS_TPMS : 8|3@1+ (1.0,0.0) [0.0|0.0] ""  CLU
 SG_ UNIT : 11|2@1+ (1.0,0.0) [0.0|3.0] ""  CLU
 SG_ PRESSURE_FL : 16|8@1+ (1.0,0.0) [0.0|255.0] ""  CLU
 SG_ PRESSURE_FR : 24|8@1+ (1.0,0.0) [0.0|255.0] ""  CLU
 SG_ PRESSURE_RL : 32|8@1+ (1.0,0.0) [0.0|255.0] ""  CLU
 SG_ PRESSURE_RR : 40|8@1+ (1.0,0.0) [0.0|255.0] ""  CLU

BO_ 915 TCS12: 4 ESC
 SG_ SA_COUNT : 0|16@1+ (2.0,-32768.0) [-32768.0|98302.0] ""  _4WD,ACU,MDPS
 SG_ SA_Z_COUNT : 16|15@1+ (2.0,-32768.0) [-32768.0|32766.0] ""  _4WD,ACU,MDPS
 SG_ SA_Z_FLAG : 31|1@1+ (1.0,0.0) [0.0|1.0] ""  _4WD,ACU,MDPS

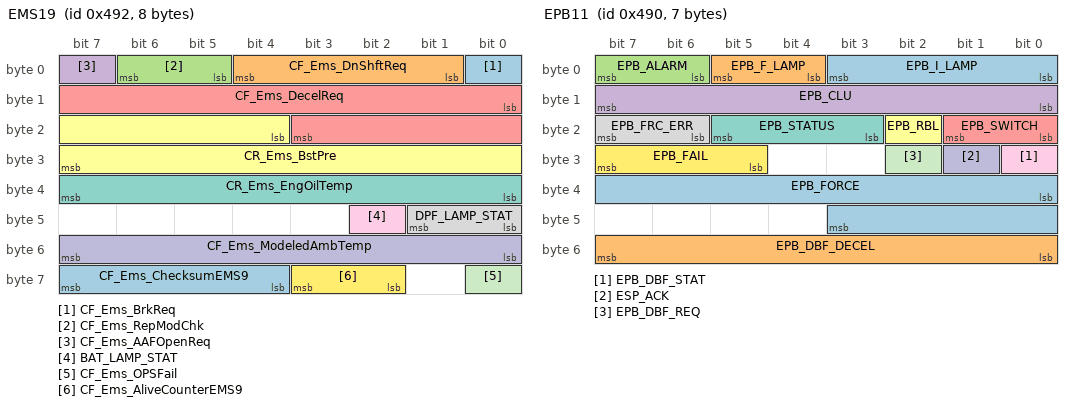
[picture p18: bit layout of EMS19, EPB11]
BO_ 1170 EMS19: 8 EMS
 SG_ CF_Ems_BrkReq : 0|1@1+ (1.0,0.0) [0.0|1.0] ""  ESC,IBOX,TCU
 SG_ CF_Ems_DnShftReq : 1|4@1+ (1.0,0.0) [0.0|14.0] ""  IBOX,TCU
 SG_ CF_Ems_RepModChk : 5|2@1+ (1.0,0.0) [0.0|3.0] ""  IBOX
 SG_ CF_Ems_AAFOpenReq : 7|1@1+ (1.0,0.0) [0.0|1.0] ""  AAF,IBOX
 SG_ CF_Ems_DecelReq : 8|12@1+ (0.0010,-4.094) [-4.094|0.0] "m/s^2"  ESC,IBOX,TCU
 SG_ CR_Ems_BstPre : 20|12@1+ (1.322,0.0) [0.0|4094.0] "hPa"  CLU,IBOX
 SG_ CR_Ems_EngOilTemp : 32|8@1+ (0.75,-40.0) [0.0|254.0] "deg"  CLU,IBOX
 SG_ DPF_LAMP_STAT : 40|2@1+ (1.0,0.0) [0.0|3.0] ""  CLU,IBOX
 SG_ BAT_LAMP_STAT : 42|1@1+ (1.0,0.0) [0.0|1.0] ""  CLU,IBOX
 SG_ CF_Ems_ModeledAmbTemp : 48|8@1+ (0.5,-41.0) [-41.0|85.5] "deg"  AAF,IBOX
 SG_ CF_Ems_OPSFail : 56|1@1+ (1.0,0.0) [0.0|1.0] ""  CLU,IBOX
 SG_ CF_Ems_AliveCounterEMS9 : 58|2@1+ (1.0,0.0) [0.0|3.0] ""  AAF,ABS,CUBIS,ECS,EPB,IBOX,MDPS,REA,SCC,SMK,TCU
 SG_ CF_Ems_ChecksumEMS9 : 60|4@1+ (1.0,0.0) [0.0|15.0] ""  AAF,ABS,CUBIS,ECS,EPB,IBOX,MDPS,REA,SCC,SMK,TCU

BO_ 1425 AFLS11: 2 AFLS
 SG_ AFLS_STAT : 1|2@1+ (1.0,0.0) [0.0|3.0] ""  CLU
 SG_ CF_Afls_TrfChgStat : 3|1@1+ (1.0,0.0) [0.0|1.0] ""  CLU
 SG_ CF_Afls_LedHLStat : 4|2@1+ (1.0,0.0) [0.0|3.0] ""  CLU

BO_ 912 SPAS11: 7 SPAS
 SG_ CF_Spas_Stat : 0|4@1+ (1.0,0.0) [0.0|15.0] ""  ESC,MDPS
 SG_ CF_Spas_TestMode : 4|2@1+ (1.0,0.0) [0.0|3.0] ""  MDPS
 SG_ CR_Spas_StrAngCmd : 8|16@1- (0.1,0.0) [-3276.8|3276.7] ""  MDPS
 SG_ CF_Spas_BeepAlarm : 24|4@1+ (1.0,0.0) [0.0|15.0] ""  CLU
 SG_ CF_Spas_Mode_Seq : 28|2@1+ (1.0,0.0) [0.0|3.0] ""  CLU
 SG_ CF_Spas_AliveCnt : 32|8@1+ (1.0,0.0) [0.0|255.0] ""  MDPS
 SG_ CF_Spas_Chksum : 40|8@1+ (1.0,0.0) [0.0|255.0] ""  MDPS
 SG_ CF_Spas_PasVol : 48|3@1+ (1.0,0.0) [0.0|7.0] ""  CGW,CLU

BO_ 1168 EPB11: 7 EPB
 SG_ EPB_I_LAMP : 0|4@1+ (1.0,0.0) [0.0|15.0] ""  BCM,CLU,CUBIS,ESC,IBOX
 SG_ EPB_F_LAMP : 4|2@1+ (1.0,0.0) [0.0|3.0] ""  CLU,CUBIS,ESC,IBOX
 SG_ EPB_ALARM : 6|2@1+ (1.0,0.0) [0.0|3.0] ""  CLU,ESC
 SG_ EPB_CLU : 8|8@1+ (1.0,0.0) [0.0|255.0] ""  CLU,ESC
 SG_ EPB_SWITCH : 16|2@1+ (1.0,0.0) [0.0|3.0] ""  ESC,SCC
 SG_ EPB_RBL : 18|1@1+ (1.0,0.0) [0.0|1.0] ""  EMS,ESC
 SG_ EPB_STATUS : 19|3@1+ (1.0,0.0) [0.0|7.0] ""  CLU,EMS,ESC,SCC,TCU
 SG_ EPB_FRC_ERR : 22|2@1+ (1.0,0.0) [0.0|3.0] ""  EMS,ESC,SCC,TCU
 SG_ EPB_DBF_STAT : 24|1@1+ (1.0,0.0) [0.0|1.0] ""  ESC
 SG_ ESP_ACK : 25|1@1+ (1.0,0.0) [0.0|1.0] ""  ESC
 SG_ EPB_DBF_REQ : 26|1@1+ (1.0,0.0) [0.0|1.0] ""  ESC
 SG_ EPB_FAIL : 29|3@1+ (1.0,0.0) [0.0|7.0] ""  ESC,SCC
 SG_ EPB_FORCE : 32|12@1+ (1.0,-1000.0) [-1000.0|3000.0] ""  ESC
 SG_ EPB_DBF_DECEL : 48|8@1+ (0.01,0.0) [0.0|2.54] "g"  ESC

BO_ 399 EMS_H12: 8 EMS
 SG_ R_TqAcnApvC : 0|8@1+ (0.2,0.0) [0.0|51.0] "Nm"  DATC,IBOX
 SG_ R_PAcnC : 8|8@1+ (125.0,0.0) [0.0|31875.0] "hPa"  DATC,IBOX
 SG_ TQI_B : 16|8@1+ (0.390625,0.0) [0.0|99.609375] "%"  ABS,ESC,IBOX
 SG_ SLD_VS : 24|8@1+ (1.0,0.0) [0.0|255.0] "km/h"  CLU,IBOX
 SG_ CF_CdaStat : 32|3@1+ (1.0,0.0) [0.0|7.0] ""  AEMC,IBOX,TCU
 SG_ CF_Ems_IsgStat : 35|3@1+ (1.0,0.0) [0.0|7.0] ""  ABS,BCM,CLU,DATC,EPB,ESC,IBOX,LDWS_LKAS,MDPS,SMK,TCU
 SG_ CF_Ems_OilChg : 38|1@1+ (1.0,0.0) [0.0|1.0] ""  CLU,IBOX
 SG_ CF_Ems_EtcLimpMod : 39|1@1+ (1.0,0.0) [0.0|1.0] ""  CLU,IBOX
 SG_ R_NEngIdlTgC : 40|8@1+ (10.0,0.0) [0.0|2550.0] "rpm"  DATC,IBOX,TCU
 SG_ CF_Ems_UpTarGr : 48|1@1+ (1.0,0.0) [0.0|1.0] ""  CLU,IBOX
 SG_ CF_Ems_DownTarGr : 49|1@1+ (1.0,0.0) [0.0|1.0] ""  CLU,IBOX
 SG_ CF_Ems_DesCurGr : 50|4@1+ (1.0,0.0) [0.0|15.0] ""  CLU,IBOX
 SG_ CF_Ems_SldAct : 54|1@1+ (1.0,0.0) [0.0|1.0] ""  CLU,IBOX
 SG_ CF_Ems_SldPosAct : 55|1@1+ (1.0,0.0) [0.0|1.0] ""  CLU,IBOX
 SG_ CF_Ems_HPresStat : 56|1@1+ (1.0,0.0) [0.0|1.0] ""  IBOX,TCU
 SG_ CF_Ems_IsgBuz : 57|1@1+ (1.0,0.0) [0.0|1.0] ""  CLU,IBOX
 SG_ CF_Ems_IdlStpFCO : 58|1@1+ (1.0,0.0) [0.0|1.0] ""  CLU,IBOX
 SG_ CF_Ems_FCopen : 59|1@1+ (1.0,0.0) [0.0|1.0] ""  CLU,IBOX
 SG_ CF_Ems_ActEcoAct : 60|1@1+ (1.0,0.0) [0.0|1.0] ""  CLU,IBOX,TCU
 SG_ CF_Ems_EngRunNorm : 61|1@1+ (1.0,0.0) [0.0|1.0] ""  ABS,ESC,IBOX,TCU
 SG_ CF_Ems_IsgStat2 : 62|2@1+ (2.0,0.0) [0.0|3.0] ""  CLU,IBOX,TCU

BO_ 1419 LCA11: 8 LCA
 SG_ CF_Lca_Stat : 0|4@1+ (1.0,0.0) [0.0|15.0] ""  BCM,CLU
 SG_ CF_Rcta_Stat : 4|4@1+ (1.0,0.0) [0.0|15.0] ""  BCM,CLU
 SG_ CF_Lca_IndLeft : 8|2@1+ (1.0,0.0) [0.0|3.0] ""  BCM,CLU
 SG_ CF_Rcw_Stat : 10|4@1+ (1.0,0.0) [0.0|15.0] ""  BCM,CLU
 SG_ CF_RCW_Warning : 14|2@1+ (1.0,0.0) [0.0|3.0] ""  BCM,CLU
 SG_ CF_Lca_IndRight : 16|2@1+ (1.0,0.0) [0.0|3.0] ""  BCM,CLU
 SG_ CF_Lca_SndWan_Stat : 18|2@1+ (1.0,0.0) [0.0|3.0] ""  BCM,CLU
 SG_ CF_FR_SndWan : 20|1@1+ (1.0,0.0) [0.0|1.0] ""  BCM,CLU
 SG_ CF_FL_SndWan : 21|1@1+ (1.0,0.0) [0.0|1.0] ""  BCM,CLU
 SG_ CF_RR_SndWan : 22|1@1+ (1.0,0.0) [0.0|1.0] ""  BCM,CLU
 SG_ CF_RL_SndWan : 23|1@1+ (1.0,0.0) [0.0|1.0] ""  BCM,CLU
 SG_ CF_Lca_IndBriLeft : 24|8@1+ (1.0,0.0) [0.0|255.0] ""  BCM,CLU
 SG_ CF_Lca_IndBriRight : 32|8@1+ (1.0,0.0) [0.0|255.0] ""  BCM,CLU
 SG_ CF_RCTA_IndBriLeft : 40|8@1+ (1.0,0.0) [0.0|255.0] ""  BCM,CLU
 SG_ CF_RCTA_IndBriRight : 48|8@1+ (1.0,0.0) [0.0|255.0] ""  BCM,CLU
 SG_ CF_RCTA_IndLeft : 56|2@1+ (1.0,0.0) [0.0|3.0] ""  BCM,CLU
 SG_ CF_RCTA_IndRight : 58|2@1+ (1.0,0.0) [0.0|3.0] ""  BCM,CLU
 SG_ CF_SndWarnForClu : 60|1@1+ (1.0,0.0) [0.0|1.0] ""  CLU

BO_ 906 ABS11: 8 ABS
 SG_ ABS_DEF : 0|1@1+ (1.0,0.0) [0.0|1.0] ""  _4WD,ACU,EMS,SPAS,TCU
 SG_ EBD_DEF : 1|1@1+ (1.0,0.0) [0.0|1.0] ""  _4WD,EMS,SPAS,TCU
 SG_ ABS_ACT : 2|1@1+ (1.0,0.0) [0.0|1.0] ""  _4WD,ACU,EPB,SPAS,TCU
 SG_ ABS_W_LAMP : 3|1@1+ (1.0,0.0) [0.0|1.0] ""  _4WD,CLU,CUBIS,MTS,TMU
 SG_ EBD_W_LAMP : 4|1@1+ (1.0,0.0) [0.0|1.0] ""  _4WD,CLU
 SG_ ABS_DIAG : 5|1@1+ (1.0,0.0) [0.0|1.0] ""  _4WD,CLU
 SG_ ESS_STAT : 6|2@1+ (1.0,0.0) [0.0|3.0] ""  _4WD,BCM,CLU,EMS

BO_ 903 WHL_PUL11: 6 ABS
 SG_ WHL_PUL_FL : 0|8@1+ (0.5,0.0) [0.0|127.5] "pulse count"  CUBIS,EPB,IBOX,SPAS,TMU,TPMS,CUBIS,EPB,IBOX,LDWS_LKAS,SPAS,TMU,TPMS
 SG_ WHL_PUL_FR : 8|8@1+ (0.5,0.0) [0.0|127.5] "pulse count"  CUBIS,EPB,IBOX,SPAS,TMU,TPMS,CUBIS,EPB,IBOX,LDWS_LKAS,SPAS,TMU,TPMS
 SG_ WHL_PUL_RL : 16|8@1+ (0.5,0.0) [0.0|127.5] "pulse count"  CUBIS,EPB,IBOX,SPAS,TMU,TPMS,CUBIS,EPB,IBOX,LDWS_LKAS,SPAS,TMU,TPMS
 SG_ WHL_PUL_RR : 24|8@1+ (0.5,0.0) [0.0|127.5] "pulse count"  CUBIS,EPB,IBOX,SPAS,TMU,TPMS,CUBIS,EPB,IBOX,LDWS_LKAS,SPAS,TMU,TPMS
 SG_ WHL_DIR_FL : 32|2@1+ (1.0,0.0) [0.0|3.0] ""  EPB,SPAS,TPMS,EPB,LCA,SPAS,TPMS
 SG_ WHL_DIR_FR : 34|2@1+ (1.0,0.0) [0.0|3.0] ""  EPB,SPAS,TPMS,EPB,LCA,SPAS,TPMS
 SG_ WHL_DIR_RL : 36|2@1+ (1.0,0.0) [0.0|3.0] ""  EPB,SPAS,TPMS,EPB,LCA,SPAS,TPMS
 SG_ WHL_DIR_RR : 38|2@1+ (1.0,0.0) [0.0|3.0] ""  EPB,SPAS,TPMS,EPB,LCA,SPAS,TPMS
 SG_ WHL_PUL_Chksum : 40|8@1+ (1.0,0.0) [0.0|255.0] ""  EPB,SPAS,TPMS,EPB,LCA,LDWS_LKAS,SPAS,TPMS

BO_ 1415 TMU11: 8 IBOX
 SG_ CF_Tmu_VehSld : 0|1@1+ (1.0,0.0) [0.0|1.0] ""  EMS
 SG_ CF_Tmu_VehImmo : 1|1@1+ (1.0,0.0) [0.0|1.0] ""  EMS
 SG_ CF_Tmu_ReqRepCnd : 2|2@1+ (1.0,0.0) [0.0|3.0] ""  EMS
 SG_ CF_Tmu_AirconCtr : 4|1@1+ (1.0,0.0) [0.0|1.0] ""  DATC
 SG_ CF_Tmu_TempMd : 5|1@1+ (1.0,0.0) [0.0|1.0] ""  DATC
 SG_ CF_Tmu_TempSet : 6|16@1+ (1.0,0.0) [0.0|20.0] ""  DATC
 SG_ CF_Tmu_DefrostCtr : 22|1@1+ (1.0,0.0) [0.0|1.0] ""  DATC,FATC
 SG_ CF_Tmu_AliveCnt1 : 56|4@1+ (1.0,0.0) [0.0|15.0] ""  EMS

BO_ 902 WHL_SPD11: 8 ABS
 SG_ WHL_SPD_FL : 0|14@1+ (0.03125,0.0) [0.0|511.96875] "km/h"  _4WD,AFLS,AHLS,AVM,CLU,CUBIS,ECS,EMS,EPB,IBOX,LDWS_LKAS,PGS,PSB,SCC,SMK,SPAS,TCU,TPMS,_4WD,ACU,AFLS,AHLS,AVM,CLU,ECS,EMS,EPB,IBOX,LCA,LDWS_LKAS,PGS,PSB,SCC,SMK,SPAS,TCU,TPMS
 SG_ WHL_SPD_FR : 16|14@1+ (0.03125,0.0) [0.0|511.96875] "km/h"  _4WD,ACU,AFLS,AHLS,AVM,CLU,CUBIS,ECS,EMS,EPB,IBOX,LDWS_LKAS,PGS,PSB,SCC,SMK,SPAS,TCU,TPMS,_4WD,ACU,AFLS,AHLS,AVM,CLU,ECS,EMS,EPB,IBOX,LCA,LDWS_LKAS,PGS,PSB,SCC,SMK,SPAS,TCU,TPMS
 SG_ WHL_SPD_RL : 32|14@1+ (0.03125,0.0) [0.0|511.96875] "km/h"  _4WD,AFLS,AHLS,AVM,BCM,CLU,CUBIS,ECS,EMS,EPB,IBOX,LDWS_LKAS,PGS,PSB,SCC,SMK,SPAS,TCU,TPMS,_4WD,ACU,AFLS,AHLS,AVM,BCM,CLU,ECS,EMS,EPB,IBOX,LCA,LDWS_LKAS,PGS,PSB,SCC,SMK,SPAS,TCU,TPMS
 SG_ WHL_SPD_RR : 48|14@1+ (0.03125,0.0) [0.0|511.96875] "km/h"  _4WD,AFLS,AHLS,AVM,CLU,CUBIS,ECS,EMS,EPB,IBOX,LDWS_LKAS,PGS,PSB,SCC,SMK,SPAS,TCU,TPMS,_4WD,ACU,AFLS,AHLS,AVM,CLU,ECS,EMS,EPB,IBOX,LCA,LDWS_LKAS,PGS,PSB,SCC,SMK,SPAS,TCU,TPMS
 SG_ WHL_SPD_AliveCounter_LSB : 14|2@1+ (1.0,0.0) [0.0|15.0] ""  _4WD,EMS,LPI,TCU,TMU
 SG_ WHL_SPD_AliveCounter_MSB : 30|2@1+ (1.0,0.0) [0.0|15.0] ""  _4WD,EMS,LPI,TCU,TMU
 SG_ WHL_SPD_Checksum_LSB : 46|2@1+ (1.0,0.0) [0.0|15.0] ""  _4WD,EMS,LPI,TCU,TMU
 SG_ WHL_SPD_Checksum_MSB : 62|2@1+ (1.0,0.0) [0.0|15.0] ""  _4WD,EMS,LPI,TCU,TMU

BO_ 1414 EVP11: 3 EVP
 SG_ CF_Evp_Stat : 0|1@1+ (1.0,0.0) [0.0|1.0] ""  CLU

BO_ 1412 AAF11: 8 AAF
 SG_ CF_Aaf_ActFlapStatus : 0|2@1+ (1.0,0.0) [0.0|3.0] ""  AAF_Tester
 SG_ CF_Aaf_ModeStatus : 2|3@1+ (1.0,0.0) [0.0|7.0] ""  AAF_Tester
 SG_ CF_Aaf_WrnLamp : 5|1@1+ (1.0,0.0) [0.0|1.0] ""  CLU
 SG_ CF_Aaf_ErrStatus : 6|10@1+ (1.0,0.0) [0.0|1023.0] ""  AAF_Tester,EMS
 SG_ CF_Aaf_OpenRqSysAct : 16|8@1+ (1.0,0.0) [0.0|255.0] ""  AAF_Tester
 SG_ CF_Aaf_PStatus : 24|8@1+ (1.0,0.0) [0.0|100.0] "%"  AAF_Tester
 SG_ CF_Aaf_OpenRqSysSol : 32|8@1+ (1.0,0.0) [0.0|255.0] ""  AAF_Tester
 SG_ CF_Aaf_SolFlapStatus : 40|2@1+ (1.0,0.0) [0.0|3.0] ""  AAF_Tester
 SG_ CF_Aaf_MilOnReq : 42|1@1+ (1.0,0.0) [0.0|1.0] ""  EMS

BO_ 900 EMS17: 8 EMS
 SG_ CF_Ems_PkpCurMSV : 0|8@1+ (1.0,0.0) [0.0|255.0] ""  DI_BOX
 SG_ CF_Ems_HolCurMSV : 8|8@1+ (1.0,0.0) [0.0|255.0] ""  DI_BOX
 SG_ CF_Ems_InjVBnkAct : 16|8@1+ (1.0,0.0) [0.0|255.0] ""  DI_BOX
 SG_ CF_Ems_InjVActSet : 24|8@1+ (1.0,0.0) [0.0|255.0] ""  DI_BOX
 SG_ CF_Ems_DiagFulHDEV : 32|1@1+ (1.0,0.0) [0.0|1.0] ""  DI_BOX
 SG_ CF_Ems_SwiOffIC1 : 33|1@1+ (1.0,0.0) [0.0|1.0] ""  DI_BOX
 SG_ CF_Ems_SwiOffIC2 : 34|1@1+ (1.0,0.0) [0.0|1.0] ""  DI_BOX
 SG_ CF_Ems_DiagReqHDEV : 38|1@1+ (1.0,0.0) [0.0|1.0] ""  DI_BOX
 SG_ CR_Ems_DutyCycMSV : 40|8@1+ (0.3921568627,0.0) [0.0|100.0] "%"  DI_BOX
 SG_ CR_Ems_BatVolRly : 48|8@1+ (0.1,0.0) [0.0|25.5] "V"  DI_BOX

BO_ 1411 CUBIS11: 8 CUBIS
 SG_ CF_Cubis_HUDisp : 0|4@1+ (1.0,0.0) [0.0|15.0] ""  CLU

BO_ 899 FATC11: 8 DATC
 SG_ CR_Fatc_TqAcnOut : 0|8@1+ (0.2,0.0) [0.0|50.8] "Nm"  EMS,IBOX
 SG_ CF_Fatc_AcnRqSwi : 8|1@1+ (1.0,0.0) [0.0|1.0] ""  AAF,EMS,IBOX
 SG_ CF_Fatc_AcnCltEnRq : 9|1@1+ (1.0,0.0) [0.0|1.0] ""  EMS,IBOX
 SG_ CF_Fatc_EcvFlt : 10|1@1+ (1.0,0.0) [0.0|1.0] ""  EMS,IBOX
 SG_ CF_Fatc_BlwrOn : 11|1@1+ (1.0,0.0) [0.0|1.0] ""  EMS,IBOX
 SG_ CF_FATC_Iden : 12|2@1+ (1.0,0.0) [0.0|3.0] ""  EMS,IBOX
 SG_ CF_Fatc_BlwrMax : 14|1@1+ (1.0,0.0) [0.0|1.0] ""  CLU,EMS,IBOX
 SG_ CF_Fatc_EngStartReq : 15|1@1+ (1.0,0.0) [0.0|1.0] ""  EMS,IBOX
 SG_ CF_Fatc_IsgStopReq : 16|1@1+ (1.0,0.0) [0.0|1.0] ""  EMS,IBOX
 SG_ CF_Fatc_CtrInf : 17|3@1+ (1.0,0.0) [0.0|7.0] ""  EMS,IBOX
 SG_ CF_Fatc_MsgCnt : 20|4@1+ (1.0,0.0) [0.0|15.0] ""  EMS,IBOX
 SG_ CR_Fatc_OutTemp : 24|8@1+ (0.5,-40.0) [-40.0|60.0] "deg"  BCM,CLU,EMS,IBOX,SPAS,TCU,TPMS
 SG_ CR_Fatc_OutTempSns : 32|8@1+ (0.5,-40.0) [-40.0|60.0] "deg"  AAF,AHLS,CLU,EMS,IBOX,SPAS,TCU
 SG_ CF_Fatc_Compload : 40|3@1+ (1.0,0.0) [0.0|7.0] ""  EMS,IBOX
 SG_ CF_Fatc_ActiveEco : 43|1@1+ (1.0,0.0) [0.0|1.0] ""  CLU,IBOX
 SG_ CF_Fatc_AutoActivation : 44|1@1+ (1.0,0.0) [0.0|1.0] ""  IBOX
 SG_ CF_Fatc_DefSw : 45|1@1+ (1.0,0.0) [0.0|1.0] ""  BCM,IBOX
 SG_ CF_Fatc_PtcRlyStat : 46|1@1+ (1.0,0.0) [0.0|1.0] ""  EMS,IBOX
 SG_ CF_Fatc_ChkSum : 56|8@1+ (1.0,0.0) [0.0|255.0] ""  EMS,IBOX,SPAS

BO_ 129 EMS_DCT12: 8 EMS
 SG_ CR_Ems_SoakTimeExt : 0|6@1+ (5.0,0.0) [0.0|315.0] "Min"  TCU
 SG_ BRAKE_ACT : 6|2@1+ (1.0,0.0) [0.0|3.0] ""  TCU
 SG_ CF_Ems_EngOperStat : 8|8@1+ (1.0,0.0) [0.0|255.0] ""  TCU
 SG_ CR_Ems_IndAirTemp : 16|8@1+ (0.75,-48.0) [-48.0|143.25] "deg"  TCU
 SG_ CF_Ems_Alive2 : 56|4@1+ (1.0,0.0) [0.0|15.0] ""  TCU
 SG_ CF_Ems_ChkSum2 : 60|4@1+ (1.0,0.0) [0.0|15.0] ""  TCU

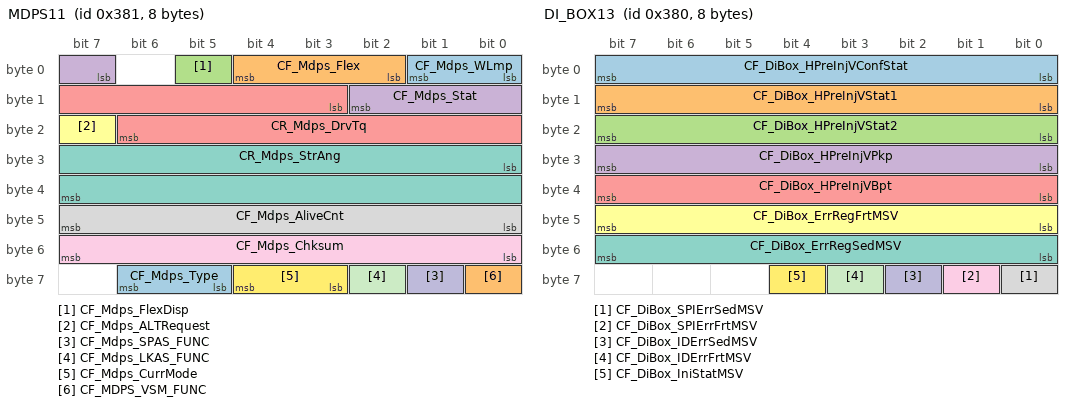
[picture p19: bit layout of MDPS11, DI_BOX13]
BO_ 897 MDPS11: 8 MDPS
 SG_ CF_Mdps_WLmp : 0|2@1+ (1.0,0.0) [0.0|3.0] ""  CLU,CUBIS,EMS,IBOX,SPAS
 SG_ CF_Mdps_Flex : 2|3@1+ (1.0,0.0) [0.0|3.0] ""  CLU,LDWS_LKAS
 SG_ CF_Mdps_FlexDisp : 5|1@1+ (1.0,0.0) [0.0|1.0] ""  CLU
 SG_ CF_Mdps_Stat : 7|4@1+ (1.0,0.0) [0.0|15.0] ""  SPAS
 SG_ CR_Mdps_DrvTq : 11|12@1+ (1.0,-2048.0) [-2048.0|2046.0] ""  SPAS
 SG_ CF_Mdps_ALTRequest : 23|1@1+ (1.0,0.0) [0.0|1.0] ""  EMS
 SG_ CR_Mdps_StrAng : 24|16@1- (0.1,0.0) [-3276.8|3276.7] "Deg"  SPAS
 SG_ CF_Mdps_AliveCnt : 40|8@1+ (1.0,0.0) [0.0|255.0] ""  LDWS_LKAS,SPAS
 SG_ CF_Mdps_Chksum : 48|8@1+ (1.0,0.0) [0.0|255.0] ""  LDWS_LKAS,SPAS
 SG_ CF_Mdps_SPAS_FUNC : 57|1@1+ (1.0,0.0) [0.0|1.0] "flag"  SPAS
 SG_ CF_Mdps_LKAS_FUNC : 58|1@1+ (1.0,0.0) [0.0|1.0] "flag"  LDWS_LKAS
 SG_ CF_Mdps_CurrMode : 59|2@1+ (1.0,0.0) [0.0|3.0] ""  LDWS_LKAS
 SG_ CF_Mdps_Type : 61|2@1+ (1.0,0.0) [0.0|2.0] ""  LDWS_LKAS,SPAS
 SG_ CF_MDPS_VSM_FUNC : 56|1@0+ (1.0,0.0) [0.0|1.0] "" XXX

BO_ 896 DI_BOX13: 8 DI_BOX
 SG_ CF_DiBox_HPreInjVConfStat : 0|8@1+ (1.0,0.0) [0.0|255.0] ""  EMS
 SG_ CF_DiBox_HPreInjVStat1 : 8|8@1+ (1.0,0.0) [0.0|255.0] ""  EMS
 SG_ CF_DiBox_HPreInjVStat2 : 16|8@1+ (1.0,0.0) [0.0|255.0] ""  EMS
 SG_ CF_DiBox_HPreInjVPkp : 24|8@1+ (1.0,0.0) [0.0|255.0] ""  EMS
 SG_ CF_DiBox_HPreInjVBpt : 32|8@1+ (1.0,0.0) [0.0|255.0] ""  EMS
 SG_ CF_DiBox_ErrRegFrtMSV : 40|8@1+ (1.0,0.0) [0.0|255.0] ""  EMS
 SG_ CF_DiBox_ErrRegSedMSV : 48|8@1+ (1.0,0.0) [0.0|255.0] ""  EMS
 SG_ CF_DiBox_SPIErrSedMSV : 56|1@1+ (1.0,0.0) [0.0|1.0] ""  EMS
 SG_ CF_DiBox_SPIErrFrtMSV : 57|1@1+ (1.0,0.0) [0.0|1.0] ""  EMS
 SG_ CF_DiBox_IDErrSedMSV : 58|1@1+ (1.0,0.0) [0.0|1.0] ""  EMS
 SG_ CF_DiBox_IDErrFrtMSV : 59|1@1+ (1.0,0.0) [0.0|1.0] ""  EMS
 SG_ CF_DiBox_IniStatMSV : 60|1@1+ (1.0,0.0) [0.0|1.0] ""  EMS

BO_ 640 EMS13: 8 EMS
 SG_ LV_FUEL_TYPE_ECU : 0|1@1+ (1.0,0.0) [0.0|1.0] ""  BCM,CLU,LPI,SMK
 SG_ LV_BFS_CFIRM : 1|1@1+ (1.0,0.0) [0.0|1.0] ""  LPI
 SG_ LV_CRASH : 2|1@1+ (1.0,0.0) [0.0|1.0] ""  LPI
 SG_ LV_VB_OFF_ACT : 3|1@1+ (1.0,0.0) [0.0|1.0] ""  LPI
 SG_ LV_GSL_MAP M : 4|1@1+ (1.0,0.0) [0.0|1.0] ""  LPI
 SG_ LV_ENG_TURN : 5|1@1+ (1.0,0.0) [0.0|1.0] ""  LPI
 SG_ ERR_FUEL : 8|8@1+ (1.0,0.0) [0.0|255.0] ""  LPI
 SG_ EOS : 16|8@1+ (1.0,0.0) [0.0|255.0] ""  LPI
 SG_ TCO : 24|8@1+ (0.75,-48.0) [-48.0|143.25] "deg"  LPI
 SG_ N_32 : 32|8@1+ (32.0,0.0) [0.0|8160.0] "rpm"  LPI
 SG_ MAF : 40|8@1+ (5.447,0.0) [0.0|1388.985] "mg/TDC"  LPI
 SG_ TIA : 48|8@1+ (0.75,-48.0) [-48.0|143.25] "deg"  LPI
 SG_ MAP m1 : 56|8@1+ (0.47058,0.0) [0.0|119.9979] "kPa"  LPI
 SG_ AMP m0 : 56|8@1+ (21.22,0.0) [0.0|5411.1] "hPa"  LPI

BO_ 128 EMS_DCT11: 8 EMS
 SG_ PV_AV_CAN : 0|8@1+ (0.3906,0.0) [0.0|99.603] "%"  TCU
 SG_ TQ_STND : 8|6@1+ (10.0,0.0) [0.0|630.0] "Nm"  TCU
 SG_ F_N_ENG : 14|1@1+ (1.0,0.0) [0.0|1.0] ""  TCU
 SG_ F_SUB_TQI : 15|1@1+ (1.0,0.0) [0.0|1.0] ""  TCU
 SG_ N : 16|16@1+ (0.25,0.0) [0.0|16383.75] "rpm"  TCU
 SG_ TQI_ACOR : 32|8@1+ (0.390625,0.0) [0.0|99.6094] "%"  IBOX,TCU
 SG_ TQFR : 40|8@1+ (0.390625,0.0) [0.0|99.6094] "%"  TCU
 SG_ TQI : 48|8@1+ (0.390625,0.0) [0.0|99.609375] "%"  TCU
 SG_ CF_Ems_Alive : 56|4@1+ (1.0,0.0) [0.0|15.0] ""  TCU
 SG_ CF_Ems_ChkSum : 60|4@1+ (1.0,0.0) [0.0|15.0] ""  TCU

BO_ 1407 HU_MON_PE_01: 8 CLU
 SG_ HU_Type : 0|8@1+ (1.0,0.0) [0.0|255.0] ""  AVM,PGS

BO_ 127 CGW5: 8 BCM
 SG_ C_StopLampLhOpenSts : 0|1@1+ (1.0,0.0) [0.0|1.0] ""  CLU
 SG_ C_StopLampRhOpenSts : 1|1@1+ (1.0,0.0) [0.0|1.0] ""  CLU
 SG_ C_HMSLOpenSts : 2|1@1+ (1.0,0.0) [0.0|1.0] ""  CLU
 SG_ C_HLampLowLhOpenSts : 3|1@1+ (1.0,0.0) [0.0|1.0] ""  CLU
 SG_ C_HLampLowRhOpenSts : 4|1@1+ (1.0,0.0) [0.0|1.0] ""  CLU
 SG_ C_HLampHighLhOpenSts : 5|1@1+ (1.0,0.0) [0.0|1.0] ""  CLU
 SG_ C_HLampHighRhOpenSts : 6|1@1+ (1.0,0.0) [0.0|1.0] ""  CLU
 SG_ C_DRLLampLhOpenSts : 7|1@1+ (1.0,0.0) [0.0|1.0] ""  CLU
 SG_ C_DRLLampRhOpenSts : 8|1@1+ (1.0,0.0) [0.0|1.0] ""  CLU
 SG_ C_RearFOGLhOpenSts : 9|1@1+ (1.0,0.0) [0.0|1.0] ""  CLU
 SG_ C_RearFOGRhOpenSts : 10|1@1+ (1.0,0.0) [0.0|1.0] ""  CLU
 SG_ C_FrontFOGLhOpenSts : 11|1@1+ (1.0,0.0) [0.0|1.0] ""  CLU
 SG_ C_FrontFOGRhOpenSts : 12|1@1+ (1.0,0.0) [0.0|1.0] ""  CLU
 SG_ C_RearEXTTailLhOpenSts : 13|1@1+ (1.0,0.0) [0.0|1.0] ""  CLU
 SG_ C_RearEXTTailRhOpenSts : 14|1@1+ (1.0,0.0) [0.0|1.0] ""  CLU
 SG_ C_FrontEXTTailLhOpenSts : 15|1@1+ (1.0,0.0) [0.0|1.0] ""  CLU
 SG_ C_FrontEXTTailRhOpenSts : 16|1@1+ (1.0,0.0) [0.0|1.0] ""  CLU
 SG_ C_RearTSIGLhOpenSts : 17|1@1+ (1.0,0.0) [0.0|1.0] ""  CLU
 SG_ C_RearTSIGRhOpenSts : 18|1@1+ (1.0,0.0) [0.0|1.0] ""  CLU
 SG_ C_FrontTSIGLhOpenSts : 19|1@1+ (1.0,0.0) [0.0|1.0] ""  CLU
 SG_ C_FrontTSIGRhOpenSts : 20|1@1+ (1.0,0.0) [0.0|1.0] ""  CLU
 SG_ C_SBendingLhOpenSts : 21|1@1+ (1.0,0.0) [0.0|1.0] ""  CLU
 SG_ C_SBendingRhOpenSts : 22|1@1+ (1.0,0.0) [0.0|1.0] ""  CLU
 SG_ C_LicensePlateLhOpenSts : 23|1@1+ (1.0,0.0) [0.0|1.0] ""  CLU
 SG_ C_LicensePlateRhOpenSts : 24|1@1+ (1.0,0.0) [0.0|1.0] ""  CLU

BO_ 354 TCU_DCT13: 3 TCU
 SG_ Clutch_Driving_Tq : 0|10@1+ (1.0,-512.0) [0.0|0.0] "Nm"  ESC
 SG_ Cluster_Engine_RPM : 10|13@1+ (0.9766,0.0) [0.0|0.0] ""  CLU
 SG_ Cluster_Engine_RPM_Flag : 23|1@1+ (1.0,0.0) [0.0|0.0] ""  CLU
